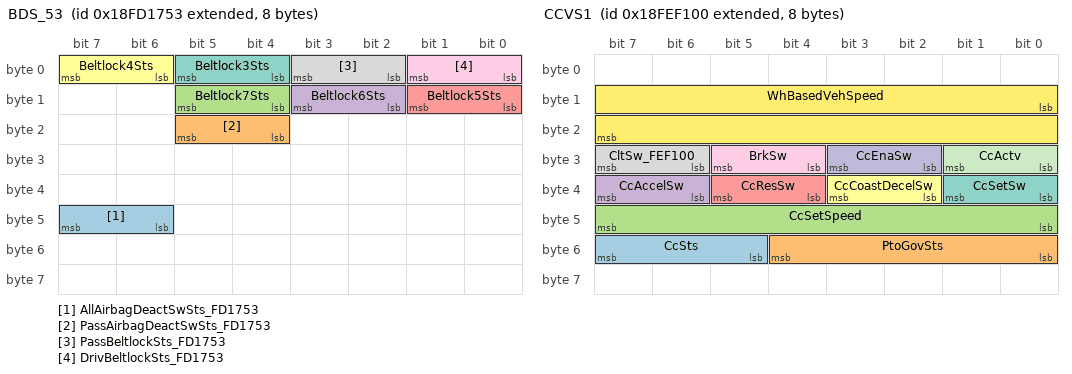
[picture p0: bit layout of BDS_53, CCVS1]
BO_ 2566723411 BDS_53: 8 Airbag
 SG_ AllAirbagDeactSwSts_FD1753 : 46|2@1+ (1,0) [0|3] ""  PCM
 SG_ PassAirbagDeactSwSts_FD1753 : 20|2@1+ (1,0) [0|3] ""  PCM
 SG_ Beltlock7Sts : 12|2@1+ (1,0) [0|3] ""  PCM
 SG_ Beltlock6Sts : 10|2@1+ (1,0) [0|3] ""  PCM
 SG_ Beltlock5Sts : 8|2@1+ (1,0) [0|3] ""  PCM
 SG_ Beltlock4Sts : 6|2@1+ (1,0) [0|3] ""  PCM
 SG_ Beltlock3Sts : 4|2@1+ (1,0) [0|3] ""  PCM
 SG_ PassBeltlockSts_FD1753 : 2|2@1+ (1,0) [0|3] ""  PCM
 SG_ DrivBeltlockSts_FD1753 : 0|2@1+ (1,0) [0|3] ""  PCM

BO_ 2365579520 BsdSensor_00: 8 ECM
 SG_ GasolInj4Diag : 62|2@1+ (1,0) [0|3] ""  PCM
 SG_ GasolInj3Diag : 60|2@1+ (1,0) [0|3] ""  PCM
 SG_ GasolInj2Diag : 58|2@1+ (1,0) [0|3] ""  PCM
 SG_ GasolInj1Diag : 56|2@1+ (1,0) [0|3] ""  PCM
 SG_ MuxSigOnCntVal : 48|8@1+ (1,0) [0|255] ""  PCM
 SG_ AckGasolInjEna : 47|1@1+ (1,0) [0|1] ""  PCM
 SG_ AckGasInjEna : 46|1@1+ (1,0) [0|1] ""  PCM
 SG_ CngInjBottomFault : 44|2@1+ (1,0) [0|3] ""  PCM
 SG_ RollCnt : 40|4@1+ (1,0) [0|15] ""  PCM
 SG_ CngInj1Diag : 38|2@1+ (1,0) [0|3] ""  PCM
 SG_ CngInj2Diag : 36|2@1+ (1,0) [0|3] ""  PCM
 SG_ CngInj3Diag : 34|2@1+ (1,0) [0|3] ""  PCM
 SG_ CngInj4Diag : 32|2@1+ (1,0) [0|3] ""  PCM
 SG_ CngTankPrsSens : 24|8@1+ (1,0) [0|250] "bar"  PCM
 SG_ TempRailPrsSens : 16|8@1+ (1,-40) [-40|60] "�C"  PCM
 SG_ FuelRailPrsSens : 8|8@1+ (0.055,0) [0|14] "bar"  PCM
 SG_ FuelRailPrsSensValData : 7|1@1+ (1,0) [0|1] ""  PCM
 SG_ TempRailPrsSensValData : 6|1@1+ (1,0) [0|1] ""  PCM
 SG_ CngTankPrsSensValData : 5|1@1+ (1,0) [0|1] ""  PCM
 SG_ CngInjBottomFaultType : 3|2@1+ (1,0) [0|3] ""  PCM
 SG_ FuelSelSts : 2|1@1+ (1,0) [0|1] ""  PCM
 SG_ DiagInj2And3ValData : 1|1@1+ (1,0) [0|1] ""  PCM
 SG_ DiagInj1And4ValData : 0|1@1+ (1,0) [0|1] ""  PCM

BO_ 2566843648 CCSS_00: 8 ECM
 SG_ MaxVsl : 0|8@1+ (1,0) [0|250] "km/h"  PCM

BO_ 2566843676 CCSS_1C: 8 PCM
 SG_ MaxVsl_FEED1C : 0|8@1+ (1,0) [0|250] "km/h" Vector__XXX

BO_ 2566844672 CCVS1: 8 ECM
 SG_ CcSts : 53|3@1+ (1,0) [0|7] ""  PCM
 SG_ PtoGovSts : 48|5@1+ (1,0) [0|31] ""  PCM
 SG_ CcSetSpeed : 40|8@1+ (1,0) [0|250] "km/h"  PCM
 SG_ CcAccelSw : 38|2@1+ (1,0) [0|3] ""  PCM
 SG_ CcResSw : 36|2@1+ (1,0) [0|3] ""  PCM
 SG_ CcCoastDecelSw : 34|2@1+ (1,0) [0|3] ""  PCM
 SG_ CcSetSw : 32|2@1+ (1,0) [0|3] ""  PCM
 SG_ CltSw_FEF100 : 30|2@1+ (1,0) [0|3] ""  PCM
 SG_ BrkSw : 28|2@1+ (1,0) [0|3] ""  PCM
 SG_ CcEnaSw : 26|2@1+ (1,0) [0|3] ""  PCM
 SG_ CcActv : 24|2@1+ (1,0) [0|3] ""  PCM
 SG_ WhBasedVehSpeed : 8|16@1+ (0.00390625,0) [0|250.996] "km/h"  PCM

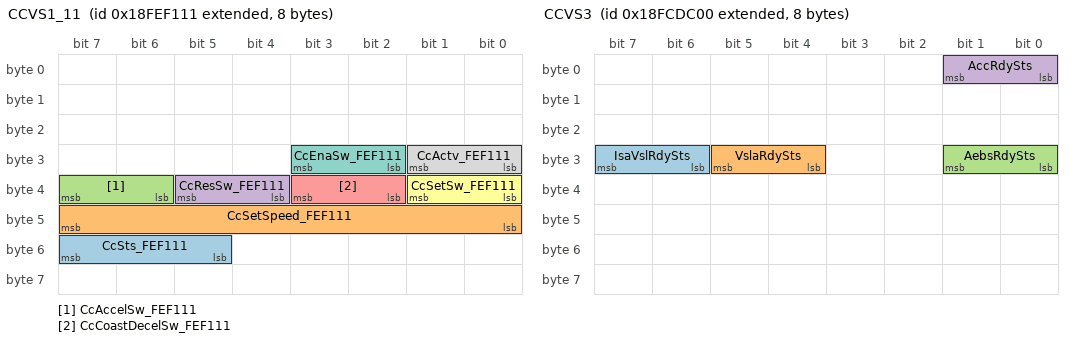
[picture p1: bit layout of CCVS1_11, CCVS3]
BO_ 2566844689 CCVS1_11: 8 NODE_11
 SG_ CcSts_FEF111 : 53|3@1+ (1,0) [0|7] ""  PCM
 SG_ CcSetSpeed_FEF111 : 40|8@1+ (1,0) [0|250] "km/h"  PCM
 SG_ CcAccelSw_FEF111 : 38|2@1+ (1,0) [0|3] ""  PCM
 SG_ CcResSw_FEF111 : 36|2@1+ (1,0) [0|3] ""  PCM
 SG_ CcCoastDecelSw_FEF111 : 34|2@1+ (1,0) [0|3] ""  PCM
 SG_ CcSetSw_FEF111 : 32|2@1+ (1,0) [0|3] ""  PCM
 SG_ CcEnaSw_FEF111 : 26|2@1+ (1,0) [0|3] ""  PCM
 SG_ CcActv_FEF111 : 24|2@1+ (1,0) [0|3] ""  PCM

BO_ 2566708224 CCVS3: 8 ECM
 SG_ IsaVslRdySts : 30|2@1+ (1,0) [0|3] ""  PCM
 SG_ VslaRdySts : 28|2@1+ (1,0) [0|3] ""  PCM
 SG_ AebsRdySts : 24|2@1+ (1,0) [0|3] ""  PCM
 SG_ AccRdySts : 0|2@1+ (1,0) [0|3] ""  PCM

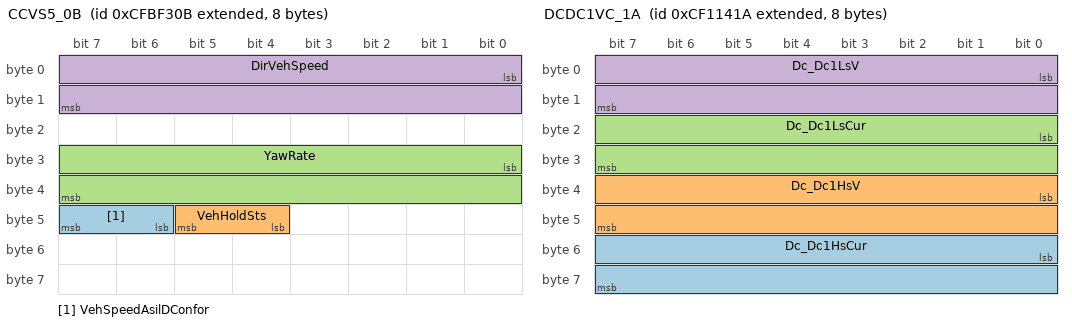
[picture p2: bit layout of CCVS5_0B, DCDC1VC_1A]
BO_ 2365321995 CCVS5_0B: 8 BSM
 SG_ VehSpeedAsilDConfor : 46|2@1+ (1,0) [0|3] ""  PCM
 SG_ VehHoldSts : 44|2@1+ (1,0) [0|3] ""  PCM
 SG_ YawRate : 24|16@1+ (0.0001220703125,-3.92) [-3.92|3.92] "rad/s"  PCM
 SG_ DirVehSpeed : 0|16@1+ (0.0078125,-250) [-250|251.992] "km/h"  PCM

BO_ 2566843136 CI_00: 609 ECM
 SG_ UnitNumPwrUnit : 24|8@1+ (1,0) [0|255] "ASCII"  PCM
 SG_ Sn : 16|8@1+ (1,0) [0|255] "ASCII"  PCM
 SG_ Model : 8|8@1+ (1,0) [0|255] "ASCII"  PCM
 SG_ Make : 0|8@1+ (1,0) [0|255] "ASCII"  PCM

BO_ 2566843141 CI_05: 609 NODE_5
 SG_ UnitNumPwrUnit_FEEB05 : 24|8@1+ (1,0) [0|255] "ASCII"  PCM
 SG_ Sn_FEEB05 : 16|8@1+ (1,0) [0|255] "ASCII"  PCM
 SG_ Model_FEEB05 : 8|8@1+ (1,0) [0|255] "ASCII"  PCM
 SG_ Make_FEEB05 : 0|8@1+ (1,0) [0|255] "ASCII"  PCM

BO_ 2566843143 CI_07: 609 NODE_7
 SG_ Sn_FEEB07 : 16|8@1+ (1,0) [0|255] "ASCII"  PCM
 SG_ Model_FEEB07 : 8|8@1+ (1,0) [0|255] "ASCII"  PCM
 SG_ Make_FEEB07 : 0|8@1+ (1,0) [0|255] "ASCII"  PCM

BO_ 2566843159 CI_17: 609 ICC
 SG_ UnitNumPwrUnit_FEEB17 : 24|8@1+ (1,0) [0|255] "ASCII"  PCM
 SG_ Sn_FEEB17 : 16|8@1+ (1,0) [0|255] "ASCII"  PCM
 SG_ Model_FEEB17 : 8|8@1+ (1,0) [0|255] "ASCII"  PCM
 SG_ Make_FEEB17 : 0|8@1+ (1,0) [0|255] "ASCII"  PCM

BO_ 2566843162 CI_1A: 609 ECS
 SG_ Sn_FEEB1A : 16|8@1+ (1,0) [0|255] "ASCII"  PCM
 SG_ Model_FEEB1A : 8|8@1+ (1,0) [0|255] "ASCII"  PCM
 SG_ Make_FEEB1A : 0|8@1+ (1,0) [0|255] "ASCII"  PCM

BO_ 2566843165 CI_1D: 609 SGW
 SG_ Sn_FEEB1D : 16|8@1+ (1,0) [0|255] "ASCII"  PCM
 SG_ Model_FEEB1D : 8|8@1+ (1,0) [0|255] "ASCII"  PCM
 SG_ Make_FEEB1D : 0|8@1+ (1,0) [0|255] "ASCII"  PCM

BO_ 2566843172 CI_24: 609 NODE_24
 SG_ Sn_FEEB24 : 16|8@1+ (1,0) [0|255] "ASCII"  PCM
 SG_ Model_FEEB24 : 8|8@1+ (1,0) [0|255] "ASCII"  PCM
 SG_ Make_FEEB24 : 0|8@1+ (1,0) [0|255] "ASCII"  PCM

BO_ 2566843175 CI_27: 609 VCM
 SG_ Sn_FEEB27 : 16|8@1+ (1,0) [0|255] "ASCII"  PCM
 SG_ Model_FEEB27 : 8|8@1+ (1,0) [0|255] "ASCII"  PCM
 SG_ Make_FEEB27 : 0|8@1+ (1,0) [0|255] "ASCII"  PCM

BO_ 2566843183 CI_2F: 609 ECAS
 SG_ UnitNumPwrUnit_FEEB2F : 24|8@1+ (1,0) [0|255] "ASCII"  PCM
 SG_ Sn_FEEB2F : 16|8@1+ (1,0) [0|255] "ASCII"  PCM
 SG_ Model_FEEB2F : 8|8@1+ (1,0) [0|255] "ASCII"  PCM
 SG_ Make_FEEB2F : 0|8@1+ (1,0) [0|255] "ASCII"  PCM

BO_ 2566843184 CI_30: 609 CDC
 SG_ Sn_FEEB30 : 16|8@1+ (1,0) [0|255] "ASCII"  PCM
 SG_ Model_FEEB30 : 8|8@1+ (1,0) [0|255] "ASCII"  PCM
 SG_ Make_FEEB30 : 0|8@1+ (1,0) [0|255] "ASCII"  PCM

BO_ 2566843201 CI_41: 609 NIS_RDR
 SG_ UnitNumPwrUnit_FEEB41 : 24|8@1+ (1,0) [0|255] "ASCII"  PCM
 SG_ Sn_FEEB41 : 16|8@1+ (1,0) [0|255] "ASCII"  PCM
 SG_ Model_FEEB41 : 8|8@1+ (1,0) [0|255] "ASCII"  PCM
 SG_ Make_FEEB41 : 0|8@1+ (1,0) [0|255] "ASCII"  PCM

BO_ 2566843209 CI_49: 609 NODE_49
 SG_ Sn_FEEB49 : 16|8@1+ (1,0) [0|255] "ASCII"  PCM
 SG_ Model_FEEB49 : 8|8@1+ (1,0) [0|255] "ASCII"  PCM
 SG_ Make_FEEB49 : 0|8@1+ (1,0) [0|255] "ASCII"  PCM

BO_ 2566843210 CI_4A: 609 PCM
 SG_ UnitNumPwrUnit_FEEB4A : 24|8@1+ (1,0) [0|255] "ASCII" Vector__XXX
 SG_ Sn_FEEB4A : 16|8@1+ (1,0) [0|255] "ASCII" Vector__XXX
 SG_ Model_FEEB4A : 8|8@1+ (1,0) [0|255] "ASCII" Vector__XXX
 SG_ Make_FEEB4A : 0|8@1+ (1,0) [0|255] "ASCII" Vector__XXX

BO_ 2566843213 CI_4D: 609 SCU
 SG_ UnitNumPwrUnit_FEEB4D : 24|8@1+ (1,0) [0|255] "ASCII"  PCM
 SG_ Sn_FEEB4D : 16|8@1+ (1,0) [0|255] "ASCII"  PCM
 SG_ Model_FEEB4D : 8|8@1+ (1,0) [0|255] "ASCII"  PCM
 SG_ Make_FEEB4D : 0|8@1+ (1,0) [0|255] "ASCII"  PCM

BO_ 2566843256 CI_78: 609 PAM
 SG_ UnitNumPwrUnit_FEEB78 : 24|8@1+ (1,0) [0|255] "ASCII"  PCM
 SG_ Sn_FEEB78 : 16|8@1+ (1,0) [0|255] "ASCII"  PCM
 SG_ Model_FEEB78 : 8|8@1+ (1,0) [0|255] "ASCII"  PCM
 SG_ Make_FEEB78 : 0|8@1+ (1,0) [0|255] "ASCII"  PCM

BO_ 2566843260 CI_7C: 609 NODE_7C
 SG_ Sn_FEEB7C : 16|8@1+ (1,0) [0|255] "ASCII"  PCM
 SG_ Model_FEEB7C : 8|8@1+ (1,0) [0|255] "ASCII"  PCM
 SG_ Make_FEEB7C : 0|8@1+ (1,0) [0|255] "ASCII"  PCM

BO_ 2566843375 CI_EF: 609 NODE_EF
 SG_ Sn_FEEBEF : 16|8@1+ (1,0) [0|255] "ASCII"  PCM
 SG_ Model_FEEBEF : 8|8@1+ (1,0) [0|255] "ASCII"  PCM
 SG_ Make_FEEBEF : 0|8@1+ (1,0) [0|255] "ASCII"  PCM

BO_ 2566843378 CI_F2: 609 NODE_F2
 SG_ Sn_FEEBF2 : 16|8@1+ (1,0) [0|255] "ASCII"  PCM
 SG_ Model_FEEBF2 : 8|8@1+ (1,0) [0|255] "ASCII"  PCM
 SG_ Make_FEEBF2 : 0|8@1+ (1,0) [0|255] "ASCII"  PCM

BO_ 2566843379 CI_F3: 609 NODE_F3
 SG_ Sn_FEEBF3 : 16|8@1+ (1,0) [0|255] "ASCII"  PCM
 SG_ Model_FEEBF3 : 8|8@1+ (1,0) [0|255] "ASCII"  PCM
 SG_ Make_FEEBF3 : 0|8@1+ (1,0) [0|255] "ASCII"  PCM

BO_ 2563833623 CL_17: 8 ICC
 SG_ IllBrtPc : 0|8@1+ (0.4,0) [0|100] "%"  PCM

BO_ 2563829281 CL_21_EE: 8 BCM
 SG_ IllBrtPc_D0EE21 : 0|8@1+ (0.4,0) [0|100] "%"  PCM,DTCO

BO_ 2563833665 CL_41: 8 NIS_RDR
 SG_ IllBrtPc_D0FF41 : 0|8@1+ (0.4,0) [0|100] "%"  PCM

BO_ 2564882176 CM1_00: 8 ECM
 SG_ BatMainSwHoldReq : 26|2@1+ (1,0) [0|3] ""  PCM

BO_ 2564882179 CM1_03: 8 AI_G5_TCM
 SG_ EngAutoStartEnaSw : 46|2@1+ (1,0) [0|3] ""  PCM

BO_ 2564882199 CM1_17: 8 ICC
 SG_ AtRegenForceSw : 42|2@1+ (1,0) [0|3] ""  PCM

BO_ 2564882201 CM1_19: 8 ACM
 SG_ CabInternTempCmd : 8|16@1+ (0.03125,-273) [-273|1734.96875] "�C"  PCM

BO_ 2564882209 CM1_21: 8 BCM
 SG_ SeatBeltSw : 30|2@1+ (1,0) [0|3] ""  PCM
 SG_ CabInternTempCmd_E0FF21 : 8|16@1+ (0.03125,-273) [-273|1734.96875] "�C"  PCM

BO_ 2564882215 CM1_27: 8 VCM
 SG_ BatMainSwHoldReq_E0FF27 : 26|2@1+ (1,0) [0|3] ""  PCM

BO_ 2564882227 CM1_33: 8 OptiTire
 SG_ BatMainSwHoldReq_E0FF33 : 26|2@1+ (1,0) [0|3] ""  PCM

BO_ 2564882241 CM1_41: 8 NIS_RDR
 SG_ BatMainSwHoldReq_E0FF41 : 26|2@1+ (1,0) [0|3] ""  PCM

BO_ 2564882250 CM1_4A: 8 PCM
 SG_ BatMainSwHoldReq_E0FF4A : 26|2@1+ (1,0) [0|3] "" Vector__XXX

BO_ 2566811659 CVW_0B: 8 BSM
 SG_ Gcvw : 16|16@1+ (10,0) [0|642550] "kg"  PCM

BO_ 2566811687 CVW_27: 8 VCM
 SG_ Gcvw_FE7027 : 16|16@1+ (10,0) [0|642550] "kg"  PCM

BO_ 2566802967 DC1_17: 8 ICC
 SG_ Sts2OfDoors : 6|2@1+ (1,0) [0|3] ""  PCM

BO_ 2364609063 DCDC1C_27: 8 VCM
 SG_ Dc_Dc1LsVBuckSetp : 8|16@1+ (0.01,0) [0|642.55] "V"  PCM
 SG_ Dc_Dc1OpCmd : 0|4@1+ (1,0) [0|15] ""  PCM

BO_ 2365315367 DCDC1LL_27: 8 VCM
 SG_ Dc_Dc1LsCurMaxLimReq : 32|16@1+ (0.05,0) [0|3212.75] "A"  PCM

BO_ 2364609306 DCDC1OS_1A: 8 ECS
 SG_ Dc_Dc1PwrLimDueToPwrElnTemp : 24|2@1+ (1,0) [0|3] ""  PCM
 SG_ Dc_Dc1OpSts : 0|4@1+ (1,0) [0|15] ""  PCM

BO_ 2364610330 DCDC1S2_1A: 8 ECS
 SG_ Dc_Dc1HsPwr : 16|16@1+ (0.05,-1600) [-1600|1612.75] "kW"  PCM
 SG_ Dc_Dc1LsPwr : 0|16@1+ (0.05,-1600) [-1600|1612.75] "kW"  PCM

BO_ 2365315079 DCDC1T_07: 8 NODE_7
 SG_ Dc_Dc1PwrElnTemp : 16|8@1+ (1,-40) [-40|210] "�C"  PCM

BO_ 2365315098 DCDC1T_1A: 8 ECS
 SG_ Dc_Dc1PwrElnTemp_BD81A : 16|8@1+ (1,-40) [-40|210] "�C"  PCM

BO_ 2365315108 DCDC1T_24: 8 NODE_24
 SG_ Dc_Dc1PwrElnTemp_BD824 : 16|8@1+ (1,-40) [-40|210] "�C"  PCM

BO_ 2364609562 DCDC1VC_1A: 8 ECS
 SG_ Dc_Dc1HsCur : 48|16@1+ (0.1,-3212.7) [-3212.7|3212.8] "A"  PCM
 SG_ Dc_Dc1HsV : 32|16@1+ (0.05,0) [0|3212.75] "V"  PCM
 SG_ Dc_Dc1LsCur : 16|16@1+ (0.1,-3212.7) [-3212.7|3212.8] "A"  PCM
 SG_ Dc_Dc1LsV : 0|16@1+ (0.01,0) [0|642.55] "V"  PCM

BO_ 2364610599 DCDC2C_27: 8 VCM
 SG_ Dc_Dc2LsVBuckSetp : 8|16@1+ (0.01,0) [0|642.55] "V"  PCM
 SG_ Dc_Dc2OpCmd : 0|4@1+ (1,0) [0|15] ""  PCM

BO_ 2365311015 DCDC2LL_27: 8 VCM
 SG_ Dc_Dc2LsCurMaxLimReq : 32|16@1+ (0.05,0) [0|3212.75] "A"  PCM

BO_ 2364611879 DCDC3C_27: 8 VCM
 SG_ Dc_Dc3LsVBuckSetp : 8|16@1+ (0.01,0) [0|642.55] "V"  PCM
 SG_ Dc_Dc3OpCmd : 0|4@1+ (1,0) [0|15] ""  PCM

BO_ 2365309479 DCDC3LL_27: 8 VCM
 SG_ Dc_Dc3LsCurMaxLimReq : 32|16@1+ (0.05,0) [0|3212.75] "A"  PCM

BO_ 2566847488 DD1_00: 8 ECM
 SG_ FuelLev1 : 8|8@1+ (0.4,0) [0|100] "%"  PCM

BO_ 2566847521 DD1_21: 8 BCM
 SG_ FuelLev2 : 48|8@1+ (0.4,0) [0|100] "%"  PCM
 SG_ FuelLev1_FEFC21 : 8|8@1+ (0.4,0) [0|100] "%"  PCM

BO_ 2566810606 DI_EE: 40 DTCO
 SG_ Driv2Id : 8|8@1+ (1,0) [0|255] "ASCII"  PCM
 SG_ Driv1Id : 0|8@1+ (1,0) [0|255] "ASCII"  PCM

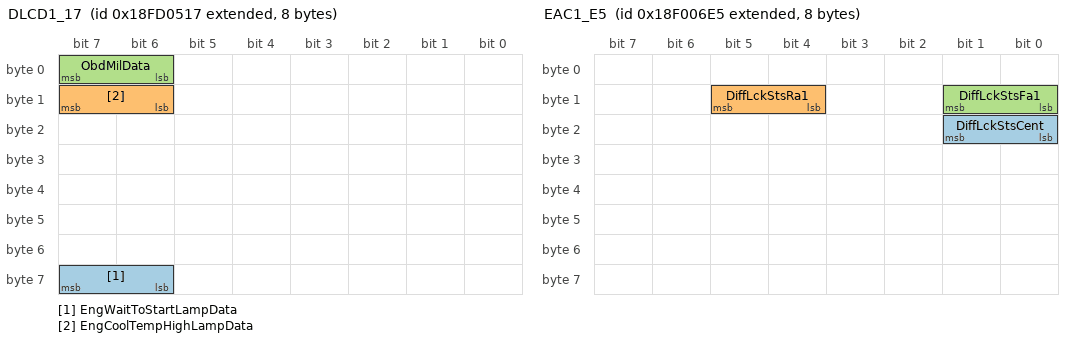
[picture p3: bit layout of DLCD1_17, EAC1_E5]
BO_ 2566718743 DLCD1_17: 8 ICC
 SG_ EngWaitToStartLampData : 62|2@1+ (1,0) [0|3] ""  PCM
 SG_ EngCoolTempHighLampData : 14|2@1+ (1,0) [0|3] ""  PCM
 SG_ ObdMilData : 6|2@1+ (1,0) [0|3] ""  PCM

BO_ 2566834688 DM01_00: 82 ECM
 SG_ SpnCm20 : 655|1@1+ (1,0) [0|1] ""  PCM

BO_ 2566834691 DM01_03: 42 AI_G5_TCM
 SG_ SpnCm10 : 335|1@1+ (1,0) [0|1] ""  PCM

BO_ 2566834693 DM01_05: 42 NODE_5
 SG_ SpnCm10_FECA05 : 335|1@1+ (1,0) [0|1] ""  PCM

BO_ 2566834695 DM01_07: 42 NODE_7
 SG_ SpnCm10_FECA07 : 335|1@1+ (1,0) [0|1] ""  PCM

BO_ 2566834699 DM01_0B: 42 BSM
 SG_ SpnCm10_FECA0B : 335|1@1+ (1,0) [0|1] ""  PCM

BO_ 2566834704 DM01_10: 42 EST54_IRCS
 SG_ SpnCm10_FECA10 : 335|1@1+ (1,0) [0|1] ""  PCM

BO_ 2566834707 DM01_13: 42 NODE_13
 SG_ SpnCm10_FECA13 : 335|1@1+ (1,0) [0|1] ""  PCM

BO_ 2566834711 DM01_17: 82 ICC
 SG_ SpnCm20_FECA17 : 655|1@1+ (1,0) [0|1] ""  PCM

BO_ 2566834713 DM01_19: 42 ACM
 SG_ SpnCm10_FECA19 : 335|1@1+ (1,0) [0|1] ""  PCM

BO_ 2566834714 DM01_1A: 42 ECS
 SG_ SpnCm10_FECA1A : 335|1@1+ (1,0) [0|1] ""  PCM

BO_ 2566834717 DM01_1D: 42 SGW
 SG_ SpnCm10_FECA1D : 335|1@1+ (1,0) [0|1] ""  PCM

BO_ 2566834721 DM01_21: 42 BCM
 SG_ SpnCm10_FECA21 : 335|1@1+ (1,0) [0|1] ""  PCM

BO_ 2566834724 DM01_24: 42 NODE_24
 SG_ SpnCm10_FECA24 : 335|1@1+ (1,0) [0|1] ""  PCM

BO_ 2566834727 DM01_27: 42 VCM
 SG_ SpnCm10_FECA27 : 335|1@1+ (1,0) [0|1] ""  PCM

BO_ 2566834730 DM01_2A: 42 LDW
 SG_ SpnCm10_FECA2A : 335|1@1+ (1,0) [0|1] ""  PCM

BO_ 2566834735 DM01_2F: 42 ECAS
 SG_ SpnCm10_FECA2F : 335|1@1+ (1,0) [0|1] ""  PCM

BO_ 2566834736 DM01_30: 42 CDC
 SG_ SpnCm10_FECA30 : 335|1@1+ (1,0) [0|1] ""  PCM

BO_ 2566834739 DM01_33: 42 OptiTire
 SG_ SpnCm10_FECA33 : 335|1@1+ (1,0) [0|1] ""  PCM

BO_ 2566834753 DM01_41: 42 NIS_RDR
 SG_ SpnCm10_FECA41 : 335|1@1+ (1,0) [0|1] ""  PCM

BO_ 2566834761 DM01_49: 42 NODE_49
 SG_ SpnCm10_FECA49 : 335|1@1+ (1,0) [0|1] ""  PCM

BO_ 2566834762 DM01_4A: 42 PCM
 SG_ SpnCm10_FECA4A : 335|1@1+ (1,0) [0|1] "" Vector__XXX

BO_ 2566834765 DM01_4D: 42 SCU
 SG_ SpnCm10_FECA4D : 335|1@1+ (1,0) [0|1] ""  PCM

BO_ 2566834771 DM01_53: 42 Airbag
 SG_ SpnCm10_FECA53 : 335|1@1+ (1,0) [0|1] ""  PCM

BO_ 2566834802 DM01_72: 42 EM_PTO
 SG_ SpnCm10_FECA72 : 335|1@1+ (1,0) [0|1] ""  PCM

BO_ 2566834808 DM01_78: 42 PAM
 SG_ SpnCm10_FECA78 : 335|1@1+ (1,0) [0|1] ""  PCM

BO_ 2566834812 DM01_7C: 42 NODE_7C
 SG_ SpnCm10_FECA7C : 335|1@1+ (1,0) [0|1] ""  PCM

BO_ 2566834817 DM01_81: 42 NODE_81
 SG_ SpnCm10_FECA81 : 335|1@1+ (1,0) [0|1] ""  PCM

BO_ 2566834844 DM01_9C: 42 RSRRM
 SG_ SpnCm10_FECA9C : 335|1@1+ (1,0) [0|1] ""  PCM

BO_ 2566834846 DM01_9E: 42 ADCU
 SG_ SpnCm10_FECA9E : 335|1@1+ (1,0) [0|1] ""  PCM

BO_ 2566834847 DM01_9F: 42 NODE_9F
 SG_ SpnCm10_FECA9F : 335|1@1+ (1,0) [0|1] ""  PCM

BO_ 2566834848 DM01_A0: 42 AEBS
 SG_ SpnCm10_FECAA0 : 335|1@1+ (1,0) [0|1] ""  PCM

BO_ 2566834889 DM01_C9: 42 ALM
 SG_ SpnCm10_FECAC9 : 335|1@1+ (1,0) [0|1] ""  PCM

BO_ 2566834917 DM01_E5: 42 BC2
 SG_ SpnCm10_FECAE5 : 335|1@1+ (1,0) [0|1] ""  PCM

BO_ 2566834926 DM01_EE: 42 DTCO
 SG_ SpnCm10_FECAEE : 335|1@1+ (1,0) [0|1] ""  PCM

BO_ 2566834927 DM01_EF: 42 NODE_EF
 SG_ SpnCm10_FECAEF : 335|1@1+ (1,0) [0|1] ""  PCM

BO_ 2566834930 DM01_F2: 42 NODE_F2
 SG_ SpnCm10_FECAF2 : 335|1@1+ (1,0) [0|1] ""  PCM

BO_ 2566834931 DM01_F3: 42 NODE_F3
 SG_ SpnCm10_FECAF3 : 335|1@1+ (1,0) [0|1] ""  PCM

BO_ 2566834947 DM02_03: 42 AI_G5_TCM
 SG_ SpnCm10_FECB03 : 335|1@1+ (1,0) [0|1] ""  PCM

BO_ 2566834949 DM02_05: 42 NODE_5
 SG_ SpnCm10_FECB05 : 335|1@1+ (1,0) [0|1] ""  PCM

BO_ 2566834951 DM02_07: 42 NODE_7
 SG_ SpnCm10_FECB07 : 335|1@1+ (1,0) [0|1] ""  PCM

BO_ 2566834970 DM02_1A: 42 ECS
 SG_ SpnCm10_FECB1A : 335|1@1+ (1,0) [0|1] ""  PCM

BO_ 2566834973 DM02_1D: 42 SGW
 SG_ SpnCm10_FECB1D : 335|1@1+ (1,0) [0|1] ""  PCM

BO_ 2566834980 DM02_24: 42 NODE_24
 SG_ SpnCm10_FECB24 : 335|1@1+ (1,0) [0|1] ""  PCM

BO_ 2566834991 DM02_2F: 42 ECAS
 SG_ SpnCm10_FECB2F : 335|1@1+ (1,0) [0|1] ""  PCM

BO_ 2566834992 DM02_30: 42 CDC
 SG_ SpnCm10_FECB30 : 335|1@1+ (1,0) [0|1] ""  PCM

BO_ 2566834995 DM02_33: 42 OptiTire
 SG_ SpnCm10_FECB33 : 335|1@1+ (1,0) [0|1] ""  PCM

BO_ 2566835017 DM02_49: 42 NODE_49
 SG_ SpnCm10_FECB49 : 335|1@1+ (1,0) [0|1] ""  PCM

BO_ 2566835018 DM02_4A: 42 PCM
 SG_ SpnCm10_FECB4A : 335|1@1+ (1,0) [0|1] "" Vector__XXX

BO_ 2566835021 DM02_4D: 42 SCU
 SG_ SpnCm10_FECB4D : 335|1@1+ (1,0) [0|1] ""  PCM

BO_ 2566835058 DM02_72: 42 EM_PTO
 SG_ SpnCm10_FECB72 : 335|1@1+ (1,0) [0|1] ""  PCM

BO_ 2566835068 DM02_7C: 42 NODE_7C
 SG_ SpnCm10_FECB7C : 335|1@1+ (1,0) [0|1] ""  PCM

BO_ 2566835183 DM02_EF: 42 NODE_EF
 SG_ SpnCm10_FECBEF : 335|1@1+ (1,0) [0|1] ""  PCM

BO_ 2566835186 DM02_F2: 42 NODE_F2
 SG_ SpnCm10_FECBF2 : 335|1@1+ (1,0) [0|1] ""  PCM

BO_ 2566835187 DM02_F3: 42 NODE_F3
 SG_ SpnCm10_FECBF3 : 335|1@1+ (1,0) [0|1] ""  PCM

BO_ 2566835459 DM04_03: 351 AI_G5_TCM
 SG_ WhBasedVehSpeed_1 : 88|16@1+ (0.00390625,0) [0|250.996] "km/h"  PCM

BO_ 2566835461 DM04_05: 250 NODE_5
 SG_ HrTotVehDist_10 : 1968|32@1+ (5,0) [0|21055406075] "m"  PCM

BO_ 2566835463 DM04_07: 250 NODE_7
 SG_ HrTotVehDist_10_FECD07 : 1968|32@1+ (5,0) [0|21055406075] "m"  PCM

BO_ 2566835482 DM04_1A: 250 ECS
 SG_ HrTotVehDist_10_FECD1A : 1968|32@1+ (5,0) [0|21055406075] "m"  PCM

BO_ 2566835485 DM04_1D: 250 SGW
 SG_ HrTotVehDist_10_FECD1D : 1968|32@1+ (5,0) [0|21055406075] "m"  PCM

BO_ 2566835492 DM04_24: 250 NODE_24
 SG_ HrTotVehDist_10_FECD24 : 1968|32@1+ (5,0) [0|21055406075] "m"  PCM

BO_ 2566835503 DM04_2F: 250 ECAS
 SG_ HrTotVehDist_10_FECD2F : 1968|32@1+ (5,0) [0|21055406075] "m"  PCM

BO_ 2566835504 DM04_30: 250 CDC
 SG_ HrTotVehDist_10_FECD30 : 1968|32@1+ (5,0) [0|21055406075] "m"  PCM

BO_ 2566835529 DM04_49: 250 NODE_49
 SG_ HrTotVehDist_10_FECD49 : 1968|32@1+ (5,0) [0|21055406075] "m"  PCM

BO_ 2566835530 DM04_4A: 250 PCM
 SG_ HrTotVehDist_10_FECD4A : 1968|32@1+ (5,0) [0|21055406075] "m" Vector__XXX

BO_ 2566835533 DM04_4D: 250 SCU
 SG_ HrTotVehDist_10_FECD4D : 1968|32@1+ (5,0) [0|21055406075] "m"  PCM

BO_ 2566835539 DM04_53: 250 Airbag
 SG_ HrTotVehDist_10_FECD53 : 1968|32@1+ (5,0) [0|21055406075] "m"  PCM

BO_ 2566835576 DM04_78: 250 PAM
 SG_ HrTotVehDist_10_FECD78 : 1968|32@1+ (5,0) [0|21055406075] "m"  PCM

BO_ 2566835580 DM04_7C: 250 NODE_7C
 SG_ HrTotVehDist_10_FECD7C : 1968|32@1+ (5,0) [0|21055406075] "m"  PCM

BO_ 2566835657 DM04_C9: 250 ALM
 SG_ HrTotVehDist_10_FECDC9 : 1968|32@1+ (5,0) [0|21055406075] "m"  PCM

BO_ 2566835695 DM04_EF: 250 NODE_EF
 SG_ HrTotVehDist_10_FECDEF : 1968|32@1+ (5,0) [0|21055406075] "m"  PCM

BO_ 2566835698 DM04_F2: 250 NODE_F2
 SG_ HrTotVehDist_10_FECDF2 : 1968|32@1+ (5,0) [0|21055406075] "m"  PCM

BO_ 2566835699 DM04_F3: 250 NODE_F3
 SG_ HrTotVehDist_10_FECDF3 : 1968|32@1+ (5,0) [0|21055406075] "m"  PCM

BO_ 2565867237 EAC1_E5: 8 BC2
 SG_ DiffLckStsCent : 16|2@1+ (1,0) [0|3] ""  PCM
 SG_ DiffLckStsRa1 : 12|2@1+ (1,0) [0|3] ""  PCM
 SG_ DiffLckStsFa1 : 8|2@1+ (1,0) [0|3] ""  PCM

CM_ SG_ 2566723411 AllAirbagDeactSwSts_FD1753 "- Proprietary Addition";
CM_ BO_ 2566843648 "- SAE Trans.Rate=OnRequest";
CM_ SG_ 2566843648 MaxVsl "- On MY24 it sends the minimum value of Prymary SL, Secondary SL and ECO mode";
CM_ BO_ 2566843676 "- SAE Trans.Rate=OnRequest";
CM_ SG_ 2566843676 MaxVsl_FEED1C "- Road Speed Limit from GPS maps
-  Type of included limits shall be defined";
CM_ SG_ 2566844672 WhBasedVehSpeed "- SAE J1939/73 Freeze Frame parameter";
CM_ SG_ 2566708224 IsaVslRdySts "- Proprietary Addition";
CM_ SG_ 2566708224 VslaRdySts "- Proprietary Addition";
CM_ SG_ 2365321995 VehSpeedAsilDConfor "- Proprietary addition";
CM_ SG_ 2365321995 VehHoldSts "- Proprietary addition";
CM_ SG_ 2365321995 YawRate "- Proprietary addition";
CM_ BO_ 2566843136 "- Delimiter (�*�) required after each parameter, even if not used
-  Multipacket message handled by SAE Transport Protocol (J1939/21, par 5.10, Multipacket Broadcast with TP.CM/BAM, TP.DT)
-  Transport Protocol with Control Flow  (RTS, CTS, EndOfMsgAck, Conn_Abort) shall be also supported by the receiver if the multipacket message has been solicited by a Destination Specific Request
-  Variable Message Length, maximum value used for dbc generation";
CM_ SG_ 2566843136 UnitNumPwrUnit "- 15+1 characters maximum
-  Optional, delimiter only if not supported
-  Variable signal length, 8 bits used for dbc generation only";
CM_ SG_ 2566843136 Sn "- 10+1 characters maximum; Manufacturer assigned (IVECO Std. 18-2253)
-  Optional (IVECO Std. 18-2253), delimiter only if not supported
-  Variable signal length, 8 bits used for dbc generation only";
CM_ SG_ 2566843136 Model "- 15+1 characters maximum; Manufacturer assigned Component (or ECU if no Component) Model or Part Number (IVECO Std. 18-2253)
-  Variable signal length, 8 bits used for dbc generation only";
CM_ SG_ 2566843136 Make "- Variable signal length, 8 bits used for dbc generation only";
CM_ BO_ 2566843141 "- Delimiter (�*�) required after each parameter, even if not used
-  Multipacket message handled by SAE Transport Protocol (J1939/21, par 5.10, Multipacket Broadcast with TP.CM/BAM, TP.DT)
-  Transport Protocol with Control Flow  (RTS, CTS, EndOfMsgAck, Conn_Abort) shall be also supported by the receiver if the multipacket message has been solicited by a Destination Specific Request
-  Variable Message Length, maximum value used for dbc generation";
CM_ SG_ 2566843141 UnitNumPwrUnit_FEEB05 "- 15+1 characters maximum
-  Optional, delimiter only if not supported
-  Variable signal length, 8 bits used for dbc generation only";
CM_ SG_ 2566843141 Sn_FEEB05 "- 10+1 characters maximum; Manufacturer assigned (IVECO Std. 18-2253)
-  Optional (IVECO Std. 18-2253), delimiter only if not supported
-  Variable signal length, 8 bits used for dbc generation only";
CM_ SG_ 2566843141 Model_FEEB05 "- 15+1 characters maximum; Manufacturer assigned Component/ECU Model or P/N(IVECO Std. 18-2253)
-  Variable signal length, 8 bits used for dbc generation only";
CM_ SG_ 2566843141 Make_FEEB05 "- Variable signal length, 8 bits used for dbc generation only";
CM_ BO_ 2566843143 "- Delimiter (�*�) required after each parameter, even if not used
-  Multipacket message handled by SAE Transport Protocol (J1939/21, par 5.10, Multipacket Broadcast with TP.CM/BAM, TP.DT)
-  Transport Protocol with Control Flow  (RTS, CTS, EndOfMsgAck, Conn_Abort) shall be also supported by the receiver if the multipacket message has been solicited by a Destination Specific Request
-  Variable Message Length, maximum value used for dbc generation";
CM_ SG_ 2566843143 Sn_FEEB07 "- 10+1 characters maximum; Manufacturer assigned (IVECO Std. 18-2253)
-  Optional (IVECO Std. 18-2253), delimiter only if not supported
-  Variable signal length, 8 bits used for dbc generation only";
CM_ SG_ 2566843143 Model_FEEB07 "- 15+1 characters maximum; Manufacturer assigned Component/ECU Model or P/N(IVECO Std. 18-2253)
-  Variable signal length, 8 bits used for dbc generation only";
CM_ SG_ 2566843143 Make_FEEB07 "- Variable signal length, 8 bits used for dbc generation only";
CM_ BO_ 2566843159 "- Delimiter (�*�) required after each parameter, even if not used
-  Multipacket message handled by SAE Transport Protocol (J1939/21, par 5.10, Multipacket Broadcast with TP.CM/BAM, TP.DT)
-  Variable Message Length, maximum value used for dbc generation";
CM_ SG_ 2566843159 UnitNumPwrUnit_FEEB17 "- 15+1 characters maximum
-  Optional, delimiter only if not supported
-  Variable signal length, 8 bits used for dbc generation only";
CM_ SG_ 2566843159 Sn_FEEB17 "- 10+1 characters maximum; Manufacturer assigned (IVECO Std. 18-2253)
-  Optional (IVECO Std. 18-2253), delimiter only if not supported
-  Variable signal length, 8 bits used for dbc generation only";
CM_ SG_ 2566843159 Model_FEEB17 "- 15+1 characters maximum; Manufacturer assigned Component/ECU Model or P/N(IVECO Std. 18-2253)
-  Variable signal length, 8 bits used for dbc generation only";
CM_ SG_ 2566843159 Make_FEEB17 "- Variable signal length, 8 bits used for dbc generation only";
CM_ BO_ 2566843162 "- Delimiter (�*�) required after each parameter, even if not used
-  Multipacket message handled by SAE Transport Protocol (J1939/21, par 5.10, Multipacket Broadcast with TP.CM/BAM, TP.DT)
-  Transport Protocol with Control Flow  (RTS, CTS, EndOfMsgAck, Conn_Abort) shall be also supported by the receiver if the multipacket message has been solicited by a Destination Specific Request
-  Variable Message Length, maximum value used for dbc generation";
CM_ SG_ 2566843162 Sn_FEEB1A "- 10+1 characters maximum; Manufacturer assigned (IVECO Std. 18-2253)
-  Optional (IVECO Std. 18-2253), delimiter only if not supported
-  Variable signal length, 8 bits used for dbc generation only";
CM_ SG_ 2566843162 Model_FEEB1A "- 15+1 characters maximum; Manufacturer assigned Component/ECU Model or P/N(IVECO Std. 18-2253)
-  Variable signal length, 8 bits used for dbc generation only";
CM_ SG_ 2566843162 Make_FEEB1A "- Variable signal length, 8 bits used for dbc generation only";
CM_ BO_ 2566843165 "- Delimiter (�*�) required after each parameter, even if not used
-  Multipacket message handled by SAE Transport Protocol (J1939/21, par 5.10, Multipacket Broadcast with TP.CM/BAM, TP.DT)
-  Transport Protocol with Control Flow  (RTS, CTS, EndOfMsgAck, Conn_Abort) shall be also supported by the receiver if the multipacket message has been solicited by a Destination Specific Request
-  Variable Message Length, maximum value used for dbc generation";
CM_ SG_ 2566843165 Sn_FEEB1D "- 10+1 characters maximum; Manufacturer assigned (IVECO Std. 18-2253)
-  Optional (IVECO Std. 18-2253), delimiter only if not supported
-  Variable signal length, 8 bits used for dbc generation only";
CM_ SG_ 2566843165 Model_FEEB1D "- 15+1 characters maximum; Manufacturer assigned Component/ECU Model or P/N(IVECO Std. 18-2253)
-  Variable signal length, 8 bits used for dbc generation only";
CM_ SG_ 2566843165 Make_FEEB1D "- Variable signal length, 8 bits used for dbc generation only";
CM_ BO_ 2566843172 "- Delimiter (�*�) required after each parameter, even if not used
-  Multipacket message handled by SAE Transport Protocol (J1939/21, par 5.10, Multipacket Broadcast with TP.CM/BAM, TP.DT)
-  Transport Protocol with Control Flow  (RTS, CTS, EndOfMsgAck, Conn_Abort) shall be also supported by the receiver if the multipacket message has been solicited by a Destination Specific Request
-  Variable Message Length, maximum value used for dbc generation";
CM_ SG_ 2566843172 Sn_FEEB24 "- 10+1 characters maximum; Manufacturer assigned (IVECO Std. 18-2253)
-  Optional (IVECO Std. 18-2253), delimiter only if not supported
-  Variable signal length, 8 bits used for dbc generation only";
CM_ SG_ 2566843172 Model_FEEB24 "- 15+1 characters maximum; Manufacturer assigned Component/ECU Model or P/N(IVECO Std. 18-2253)
-  Variable signal length, 8 bits used for dbc generation only";
CM_ SG_ 2566843172 Make_FEEB24 "- Variable signal length, 8 bits used for dbc generation only";
CM_ BO_ 2566843175 "- Delimiter (�*�) required after each parameter, even if not used
-  Multipacket message handled by SAE Transport Protocol (J1939/21, par 5.10, Multipacket Broadcast with TP.CM/BAM, TP.DT)
-  Transport Protocol with Control Flow  (RTS, CTS, EndOfMsgAck, Conn_Abort) shall be also supported by the receiver if the multipacket message has been solicited by a Destination Specific Request
-  Variable Message Length, maximum value used for dbc generation";
CM_ SG_ 2566843175 Sn_FEEB27 "- 10+1 characters maximum; Manufacturer assigned (IVECO Std. 18-2253)
-  Optional (IVECO Std. 18-2253), delimiter only if not supported
-  Variable signal length, 8 bits used for dbc generation only";
CM_ SG_ 2566843175 Model_FEEB27 "- 15+1 characters maximum; Manufacturer assigned Component/ECU Model or P/N(IVECO Std. 18-2253)
-  Variable signal length, 8 bits used for dbc generation only";
CM_ SG_ 2566843175 Make_FEEB27 "- Variable signal length, 8 bits used for dbc generation only";
CM_ BO_ 2566843183 "- Delimiter (�*�) required after each parameter, even if not used
-  Multipacket message handled by SAE Transport Protocol (J1939/21, par 5.10, Multipacket Broadcast with TP.CM/BAM, TP.DT)
-  Transport Protocol with Control Flow  (RTS, CTS, EndOfMsgAck, Conn_Abort) shall be also supported by the receiver if the multipacket message has been solicited by a Destination Specific Request
-  Variable Message Length, maximum value used for dbc generation";
CM_ SG_ 2566843183 UnitNumPwrUnit_FEEB2F "- 15+1 characters maximum
-  Optional, delimiter only if not supported
-  Variable signal length, 8 bits used for dbc generation only";
CM_ SG_ 2566843183 Sn_FEEB2F "- 10+1 characters maximum; Manufacturer assigned (IVECO Std. 18-2253)
-  Optional (IVECO Std. 18-2253), delimiter only if not supported
-  Variable signal length, 8 bits used for dbc generation only";
CM_ SG_ 2566843183 Model_FEEB2F "- 15+1 characters maximum; Manufacturer assigned Component/ECU Model or P/N(IVECO Std. 18-2253)
-  Variable signal length, 8 bits used for dbc generation only";
CM_ SG_ 2566843183 Make_FEEB2F "- Variable signal length, 8 bits used for dbc generation only";
CM_ BO_ 2566843184 "- Delimiter (�*�) required after each parameter, even if not used
-  Multipacket message handled by SAE Transport Protocol (J1939/21, par 5.10, Multipacket Broadcast with TP.CM/BAM, TP.DT)
-  Transport Protocol with Control Flow  (RTS, CTS, EndOfMsgAck, Conn_Abort) shall be also supported by the receiver if the multipacket message has been solicited by a Destination Specific Request
-  Variable Message Length, maximum value used for dbc generation";
CM_ SG_ 2566843184 Sn_FEEB30 "- 10+1 characters maximum; Manufacturer assigned (IVECO Std. 18-2253)
-  Optional (IVECO Std. 18-2253), delimiter only if not supported
-  Variable signal length, 8 bits used for dbc generation only";
CM_ SG_ 2566843184 Model_FEEB30 "- 15+1 characters maximum; Manufacturer assigned Component/ECU Model or P/N(IVECO Std. 18-2253)
-  Variable signal length, 8 bits used for dbc generation only";
CM_ SG_ 2566843184 Make_FEEB30 "- Variable signal length, 8 bits used for dbc generation only";
CM_ BO_ 2566843201 "- Delimiter (�*�) required after each parameter, even if not used
-  Multipacket message handled by SAE Transport Protocol (J1939/21, par 5.10, Multipacket Broadcast with TP.CM/BAM, TP.DT)
-  Transport Protocol with Control Flow  (RTS, CTS, EndOfMsgAck, Conn_Abort) shall be also supported by the receiver if the multipacket message has been solicited by a Destination Specific Request
-  Variable Message Length, maximum value used for dbc generation";
CM_ SG_ 2566843201 UnitNumPwrUnit_FEEB41 "- 15+1 characters maximum
-  Optional, delimiter only if not supported
-  Variable signal length, 8 bits used for dbc generation only";
CM_ SG_ 2566843201 Sn_FEEB41 "- 10+1 characters maximum; Manufacturer assigned (IVECO Std. 18-2253)
-  Optional (IVECO Std. 18-2253), delimiter only if not supported
-  Variable signal length, 8 bits used for dbc generation only";
CM_ SG_ 2566843201 Model_FEEB41 "- 15+1 characters maximum; Manufacturer assigned Component/ECU Model or P/N(IVECO Std. 18-2253)
-  Variable signal length, 8 bits used for dbc generation only";
CM_ SG_ 2566843201 Make_FEEB41 "- Variable signal length, 8 bits used for dbc generation only";
CM_ BO_ 2566843209 "- Delimiter (�*�) required after each parameter, even if not used
-  Multipacket message handled by SAE Transport Protocol (J1939/21, par 5.10, Multipacket Broadcast with TP.CM/BAM, TP.DT)
-  Transport Protocol with Control Flow  (RTS, CTS, EndOfMsgAck, Conn_Abort) shall be also supported by the receiver if the multipacket message has been solicited by a Destination Specific Request
-  Variable Message Length, maximum value used for dbc generation";
CM_ SG_ 2566843209 Sn_FEEB49 "- 10+1 characters maximum; Manufacturer assigned (IVECO Std. 18-2253)
-  Optional (IVECO Std. 18-2253), delimiter only if not supported
-  Variable signal length, 8 bits used for dbc generation only";
CM_ SG_ 2566843209 Model_FEEB49 "- 15+1 characters maximum; Manufacturer assigned Component/ECU Model or P/N(IVECO Std. 18-2253)
-  Variable signal length, 8 bits used for dbc generation only";
CM_ SG_ 2566843209 Make_FEEB49 "- Variable signal length, 8 bits used for dbc generation only";
CM_ BO_ 2566843210 "- Delimiter (�*�) required after each parameter, even if not used
-  Multipacket message handled by SAE Transport Protocol (J1939/21, par 5.10, Multipacket Broadcast with TP.CM/BAM, TP.DT)
-  Transport Protocol with Control Flow  (RTS, CTS, EndOfMsgAck, Conn_Abort) shall be also supported by the receiver if the multipacket message has been solicited by a Destination Specific Request
-  Variable Message Length, maximum value used for dbc generation";
CM_ SG_ 2566843210 UnitNumPwrUnit_FEEB4A "- 15+1 characters maximum
-  Optional, delimiter only if not supported
-  Variable signal length, 8 bits used for dbc generation only";
CM_ SG_ 2566843210 Sn_FEEB4A "- 10+1 characters maximum; Manufacturer assigned (IVECO Std. 18-2253)
-  Optional (IVECO Std. 18-2253), delimiter only if not supported
-  Variable signal length, 8 bits used for dbc generation only";
CM_ SG_ 2566843210 Model_FEEB4A "- 15+1 characters maximum; Manufacturer assigned Component/ECU Model or P/N(IVECO Std. 18-2253)
-  Variable signal length, 8 bits used for dbc generation only";
CM_ SG_ 2566843210 Make_FEEB4A "- Variable signal length, 8 bits used for dbc generation only";
CM_ BO_ 2566843213 "- Delimiter (�*�) required after each parameter, even if not used
-  Multipacket message handled by SAE Transport Protocol (J1939/21, par 5.10, Multipacket Broadcast with TP.CM/BAM, TP.DT)
-  Transport Protocol with Control Flow  (RTS, CTS, EndOfMsgAck, Conn_Abort) shall be also supported by the receiver if the multipacket message has been solicited by a Destination Specific Request
-  Variable Message Length, maximum value used for dbc generation";
CM_ SG_ 2566843213 UnitNumPwrUnit_FEEB4D "- 15+1 characters maximum
-  Optional, delimiter only if not supported
-  Variable signal length, 8 bits used for dbc generation only";
CM_ SG_ 2566843213 Sn_FEEB4D "- 10+1 characters maximum; Manufacturer assigned (IVECO Std. 18-2253)
-  Optional (IVECO Std. 18-2253), delimiter only if not supported
-  Variable signal length, 8 bits used for dbc generation only";
CM_ SG_ 2566843213 Model_FEEB4D "- 15+1 characters maximum; Manufacturer assigned Component/ECU Model or P/N(IVECO Std. 18-2253)
-  Variable signal length, 8 bits used for dbc generation only";
CM_ SG_ 2566843213 Make_FEEB4D "- Variable signal length, 8 bits used for dbc generation only";
CM_ BO_ 2566843256 "- Delimiter (�*�) required after each parameter, even if not used
-  Multipacket message handled by SAE Transport Protocol (J1939/21, par 5.10, Multipacket Broadcast with TP.CM/BAM, TP.DT)
-  Transport Protocol with Control Flow  (RTS, CTS, EndOfMsgAck, Conn_Abort) shall be also supported by the receiver if the multipacket message has been solicited by a Destination Specific Request
-  Variable Message Length, maximum value used for dbc generation";
CM_ SG_ 2566843256 UnitNumPwrUnit_FEEB78 "- 15+1 characters maximum
-  Optional, delimiter only if not supported
-  Variable signal length, 8 bits used for dbc generation only";
CM_ SG_ 2566843256 Sn_FEEB78 "- 10+1 characters maximum; Manufacturer assigned (IVECO Std. 18-2253)
-  Optional (IVECO Std. 18-2253), delimiter only if not supported
-  Variable signal length, 8 bits used for dbc generation only";
CM_ SG_ 2566843256 Model_FEEB78 "- 15+1 characters maximum; Manufacturer assigned Component/ECU Model or P/N(IVECO Std. 18-2253)
-  Variable signal length, 8 bits used for dbc generation only";
CM_ SG_ 2566843256 Make_FEEB78 "- Variable signal length, 8 bits used for dbc generation only";
CM_ BO_ 2566843260 "- Delimiter (�*�) required after each parameter, even if not used
-  Multipacket message handled by SAE Transport Protocol (J1939/21, par 5.10, Multipacket Broadcast with TP.CM/BAM, TP.DT)
-  Transport Protocol with Control Flow  (RTS, CTS, EndOfMsgAck, Conn_Abort) shall be also supported by the receiver if the multipacket message has been solicited by a Destination Specific Request
-  Variable Message Length, maximum value used for dbc generation";
CM_ SG_ 2566843260 Sn_FEEB7C "- 10+1 characters maximum; Manufacturer assigned (IVECO Std. 18-2253)
-  Optional (IVECO Std. 18-2253), delimiter only if not supported
-  Variable signal length, 8 bits used for dbc generation only";
CM_ SG_ 2566843260 Model_FEEB7C "- 15+1 characters maximum; Manufacturer assigned Component/ECU Model or P/N(IVECO Std. 18-2253)
-  Variable signal length, 8 bits used for dbc generation only";
CM_ SG_ 2566843260 Make_FEEB7C "- Variable signal length, 8 bits used for dbc generation only";
CM_ BO_ 2566843375 "- Delimiter (�*�) required after each parameter, even if not used
-  Multipacket message handled by SAE Transport Protocol (J1939/21, par 5.10, Multipacket Broadcast with TP.CM/BAM, TP.DT)
-  Transport Protocol with Control Flow  (RTS, CTS, EndOfMsgAck, Conn_Abort) shall be also supported by the receiver if the multipacket message has been solicited by a Destination Specific Request
-  Variable Message Length, maximum value used for dbc generation";
CM_ SG_ 2566843375 Sn_FEEBEF "- 10+1 characters maximum; Manufacturer assigned (IVECO Std. 18-2253)
-  Optional (IVECO Std. 18-2253), delimiter only if not supported
-  Variable signal length, 8 bits used for dbc generation only";
CM_ SG_ 2566843375 Model_FEEBEF "- 15+1 characters maximum; Manufacturer assigned Component/ECU Model or P/N(IVECO Std. 18-2253)
-  Variable signal length, 8 bits used for dbc generation only";
CM_ SG_ 2566843375 Make_FEEBEF "- Variable signal length, 8 bits used for dbc generation only";
CM_ BO_ 2566843378 "- Delimiter (�*�) required after each parameter, even if not used
-  Multipacket message handled by SAE Transport Protocol (J1939/21, par 5.10, Multipacket Broadcast with TP.CM/BAM, TP.DT)
-  Transport Protocol with Control Flow  (RTS, CTS, EndOfMsgAck, Conn_Abort) shall be also supported by the receiver if the multipacket message has been solicited by a Destination Specific Request
-  Variable Message Length, maximum value used for dbc generation";
CM_ SG_ 2566843378 Sn_FEEBF2 "- 10+1 characters maximum; Manufacturer assigned (IVECO Std. 18-2253)
-  Optional (IVECO Std. 18-2253), delimiter only if not supported
-  Variable signal length, 8 bits used for dbc generation only";
CM_ SG_ 2566843378 Model_FEEBF2 "- 15+1 characters maximum; Manufacturer assigned Component/ECU Model or P/N(IVECO Std. 18-2253)
-  Variable signal length, 8 bits used for dbc generation only";
CM_ SG_ 2566843378 Make_FEEBF2 "- Variable signal length, 8 bits used for dbc generation only";
CM_ BO_ 2566843379 "- Delimiter (�*�) required after each parameter, even if not used
-  Multipacket message handled by SAE Transport Protocol (J1939/21, par 5.10, Multipacket Broadcast with TP.CM/BAM, TP.DT)
-  Transport Protocol with Control Flow  (RTS, CTS, EndOfMsgAck, Conn_Abort) shall be also supported by the receiver if the multipacket message has been solicited by a Destination Specific Request
-  Variable Message Length, maximum value used for dbc generation";
CM_ SG_ 2566843379 Sn_FEEBF3 "- 10+1 characters maximum; Manufacturer assigned (IVECO Std. 18-2253)
-  Optional (IVECO Std. 18-2253), delimiter only if not supported
-  Variable signal length, 8 bits used for dbc generation only";
CM_ SG_ 2566843379 Model_FEEBF3 "- 15+1 characters maximum; Manufacturer assigned Component/ECU Model or P/N(IVECO Std. 18-2253)
-  Variable signal length, 8 bits used for dbc generation only";
CM_ SG_ 2566843379 Make_FEEBF3 "- Variable signal length, 8 bits used for dbc generation only";
CM_ BO_ 2564882179 "- SAE Trans.Rate=1000ms
-  Transmitted every 1s and on change of state but no faster than every 100 ms";
CM_ BO_ 2564882201 "- SAE Trans.Rate=1000ms";
CM_ SG_ 2564882201 CabInternTempCmd "- 0x0000 for LO,  0xFAFF for HI, 0xFFFF for NoRequest / Off
-  BCM S-Way MY19 set to 0xFFFF as initial value";
CM_ SG_ 2564882209 SeatBeltSw "- 10b used for Not fastened, alarm";
CM_ SG_ 2564882209 CabInternTempCmd_E0FF21 "- 0x0000 for LO,  0xFAFF for HI, 0xFFFF for NoRequest / Off";
CM_ SG_ 2564882250 BatMainSwHoldReq_E0FF4A "- VT Custom (00b : Network ON - PCM present, Network Available; 01b : Network OFF - PCM present, Network Not Available)";
CM_ BO_ 2566811659 "- Cyclic Transmission Rate as result of PGN requests
-  FMS Trans.Rate=1s
-  SAE Trans.Rate=OnRequest";
CM_ SG_ 2566802967 Sts2OfDoors "- 00 Unlock, 01 Lock";
CM_ BO_ 2566810606 "-  2 Message Variant(s): Transm.Rates 10000, OnRequest
-  Cyclic Transmission Rate as result of PGN requests
-  Multipacket message handled by SAE Transport Protocol (J1939/21, par 5.10, Multipacket Broadcast with TP.CM/BAM, TP.DT)
-  Variable Message Length, maximum value used for dbc generation
-  Multipacket message handled by SAE Transport Protocol (J1939/21, par 5.10, Multipacket Broadcast with TP.CM/BAM, TP.DT)
-  Variable Message Length, maximum value used for dbc generation";
CM_ SG_ 2566810606 Driv2Id "- Issuing member state + CardNumber = 3 + 16 Byte (acc. ISO 16844)
-  Variable signal length, 8 bits used for dbc generation only
-  Variable signal position, SPN Position value used for dbc generation only";
CM_ SG_ 2566810606 Driv1Id "- Issuing member state + CardNumber = 3 + 16 Byte (acc. ISO 16844)
-  Variable signal length, 8 bits used for dbc generation only";
CM_ SG_ 2566718743 EngWaitToStartLampData "- 10b used for Error Indicator, 01b if lamp on or blinking";
CM_ SG_ 2566718743 ObdMilData "- 10b used for Error Indicator, 01b if lamp on or blinking";
CM_ BO_ 2566834688 "- Multipacket message handled by SAE Transport Protocol (J1939/21, par 5.10, Multipacket Broadcast with TP.CM/BAM, TP.DT)
-  Variable Message Length, maximum value used for dbc generation";
CM_ SG_ 2566834688 SpnCm20 "- Always 0b";
CM_ BO_ 2566834691 "- Multipacket message handled by SAE Transport Protocol (J1939/21, par 5.10, Multipacket Broadcast with TP.CM/BAM, TP.DT)
-  Variable Message Length, maximum value used for dbc generation";
CM_ SG_ 2566834691 SpnCm10 "- Always 0b";
CM_ BO_ 2566834693 "- Multipacket message handled by SAE Transport Protocol (J1939/21, par 5.10, Multipacket Broadcast with TP.CM/BAM, TP.DT)
-  Variable Message Length, maximum value used for dbc generation";
CM_ SG_ 2566834693 SpnCm10_FECA05 "- Always 0b";
CM_ BO_ 2566834695 "- Multipacket message handled by SAE Transport Protocol (J1939/21, par 5.10, Multipacket Broadcast with TP.CM/BAM, TP.DT)
-  Variable Message Length, maximum value used for dbc generation";
CM_ SG_ 2566834695 SpnCm10_FECA07 "- Always 0b";
CM_ BO_ 2566834699 "- Multipacket message handled by SAE Transport Protocol (J1939/21, par 5.10, Multipacket Broadcast with TP.CM/BAM, TP.DT)
-  Variable Message Length, maximum value used for dbc generation";
CM_ SG_ 2566834699 SpnCm10_FECA0B "- Always 0b";
CM_ BO_ 2566834704 "- Multipacket message handled by SAE Transport Protocol (J1939/21, par 5.10, Multipacket Broadcast with TP.CM/BAM, TP.DT)
-  Variable Message Length, maximum value used for dbc generation";
CM_ SG_ 2566834704 SpnCm10_FECA10 "- Always 00b";
CM_ BO_ 2566834707 "- Multipacket message handled by SAE Transport Protocol (J1939/21, par 5.10, Multipacket Broadcast with TP.CM/BAM, TP.DT)
-  Variable Message Length, maximum value used for dbc generation";
CM_ SG_ 2566834707 SpnCm10_FECA13 "- Always 0b";
CM_ BO_ 2566834711 "- Multipacket message handled by SAE Transport Protocol (J1939/21, par 5.10, Multipacket Broadcast with TP.CM/BAM, TP.DT)
-  Variable Message Length, maximum value used for dbc generation";
CM_ SG_ 2566834711 SpnCm20_FECA17 "- Always 0b";
CM_ BO_ 2566834713 "- Multipacket message handled by SAE Transport Protocol (J1939/21, par 5.10, Multipacket Broadcast with TP.CM/BAM, TP.DT)
-  Variable Message Length, maximum value used for dbc generation";
CM_ SG_ 2566834713 SpnCm10_FECA19 "- Always 0b";
CM_ BO_ 2566834714 "- Multipacket message handled by SAE Transport Protocol (J1939/21, par 5.10, Multipacket Broadcast with TP.CM/BAM, TP.DT)
-  Variable Message Length, maximum value used for dbc generation";
CM_ SG_ 2566834714 SpnCm10_FECA1A "- Always 0b";
CM_ BO_ 2566834717 "- Multipacket message handled by SAE Transport Protocol (J1939/21, par 5.10, Multipacket Broadcast with TP.CM/BAM, TP.DT)
-  Variable Message Length, maximum value used for dbc generation";
CM_ SG_ 2566834717 SpnCm10_FECA1D "- Always 0b";
CM_ BO_ 2566834721 "- Multipacket message handled by SAE Transport Protocol (J1939/21, par 5.10, Multipacket Broadcast with TP.CM/BAM, TP.DT)
-  Variable Message Length, maximum value used for dbc generation";
CM_ SG_ 2566834721 SpnCm10_FECA21 "- Always 0b";
CM_ BO_ 2566834724 "- Multipacket message handled by SAE Transport Protocol (J1939/21, par 5.10, Multipacket Broadcast with TP.CM/BAM, TP.DT)
-  Variable Message Length, maximum value used for dbc generation";
CM_ SG_ 2566834724 SpnCm10_FECA24 "- Always 0b";
CM_ BO_ 2566834727 "- Multipacket message handled by SAE Transport Protocol (J1939/21, par 5.10, Multipacket Broadcast with TP.CM/BAM, TP.DT)
-  Variable Message Length, maximum value used for dbc generation";
CM_ SG_ 2566834727 SpnCm10_FECA27 "- Always 0b";
CM_ BO_ 2566834730 "- Multipacket message handled by SAE Transport Protocol (J1939/21, par 5.10, Multipacket Broadcast with TP.CM/BAM, TP.DT)
-  Variable Message Length, maximum value used for dbc generation";
CM_ SG_ 2566834730 SpnCm10_FECA2A "- Always 0b";
CM_ BO_ 2566834735 "- Multipacket message handled by SAE Transport Protocol (J1939/21, par 5.10, Multipacket Broadcast with TP.CM/BAM, TP.DT)
-  Variable Message Length, maximum value used for dbc generation";
CM_ SG_ 2566834735 SpnCm10_FECA2F "- Always 0b";
CM_ BO_ 2566834736 "- Multipacket message handled by SAE Transport Protocol (J1939/21, par 5.10, Multipacket Broadcast with TP.CM/BAM, TP.DT)
-  Variable Message Length, maximum value used for dbc generation";
CM_ SG_ 2566834736 SpnCm10_FECA30 "- Always 0b";
CM_ BO_ 2566834739 "- Multipacket message handled by SAE Transport Protocol (J1939/21, par 5.10, Multipacket Broadcast with TP.CM/BAM, TP.DT)
-  Variable Message Length, maximum value used for dbc generation";
CM_ SG_ 2566834739 SpnCm10_FECA33 "- Always 0b";
CM_ BO_ 2566834753 "- Multipacket message handled by SAE Transport Protocol (J1939/21, par 5.10, Multipacket Broadcast with TP.CM/BAM, TP.DT)
-  Variable Message Length, maximum value used for dbc generation";
CM_ SG_ 2566834753 SpnCm10_FECA41 "- Always 0b";
CM_ BO_ 2566834761 "- Multipacket message handled by SAE Transport Protocol (J1939/21, par 5.10, Multipacket Broadcast with TP.CM/BAM, TP.DT)
-  Variable Message Length, maximum value used for dbc generation";
CM_ SG_ 2566834761 SpnCm10_FECA49 "- Always 0b";
CM_ BO_ 2566834765 "- Multipacket message handled by SAE Transport Protocol (J1939/21, par 5.10, Multipacket Broadcast with TP.CM/BAM, TP.DT)
-  Transmitted in C-Roads and Ensemble Project by FOBS
-  Variable Message Length, maximum value used for dbc generation";
CM_ SG_ 2566834765 SpnCm10_FECA4D "- Always 0b";
CM_ BO_ 2566834771 "- Multipacket message handled by SAE Transport Protocol (J1939/21, par 5.10, Multipacket Broadcast with TP.CM/BAM, TP.DT)
-  Variable Message Length, maximum value used for dbc generation";
CM_ SG_ 2566834771 SpnCm10_FECA53 "- Always 0b";
CM_ BO_ 2566834802 "- Multipacket message handled by SAE Transport Protocol (J1939/21, par 5.10, Multipacket Broadcast with TP.CM/BAM, TP.DT)
-  Variable Message Length, maximum value used for dbc generation";
CM_ SG_ 2566834802 SpnCm10_FECA72 "- Always 0b";
CM_ BO_ 2566834808 "- Multipacket message handled by SAE Transport Protocol (J1939/21, par 5.10, Multipacket Broadcast with TP.CM/BAM, TP.DT)
-  Variable Message Length, maximum value used for dbc generation";
CM_ SG_ 2566834808 SpnCm10_FECA78 "- Always 0b";
CM_ BO_ 2566834812 "- Multipacket message handled by SAE Transport Protocol (J1939/21, par 5.10, Multipacket Broadcast with TP.CM/BAM, TP.DT)
-  Variable Message Length, maximum value used for dbc generation";
CM_ SG_ 2566834812 SpnCm10_FECA7C "- Always 0b";
CM_ BO_ 2566834817 "- Multipacket message handled by SAE Transport Protocol (J1939/21, par 5.10, Multipacket Broadcast with TP.CM/BAM, TP.DT)
-  Variable Message Length, maximum value used for dbc generation";
CM_ SG_ 2566834817 SpnCm10_FECA81 "- Always 0b";
CM_ BO_ 2566834844 "- Multipacket message handled by SAE Transport Protocol (J1939/21, par 5.10, Multipacket Broadcast with TP.CM/BAM, TP.DT)
-  Variable Message Length, maximum value used for dbc generation";
CM_ SG_ 2566834844 SpnCm10_FECA9C "- Always 0b";
CM_ BO_ 2566834846 "- Multipacket message handled by SAE Transport Protocol (J1939/21, par 5.10, Multipacket Broadcast with TP.CM/BAM, TP.DT)
-  Variable Message Length, maximum value used for dbc generation";
CM_ SG_ 2566834846 SpnCm10_FECA9E "- Always 0b";
CM_ BO_ 2566834847 "- Multipacket message handled by SAE Transport Protocol (J1939/21, par 5.10, Multipacket Broadcast with TP.CM/BAM, TP.DT)
-  Transport Protocol Packets (TP.CM, TP.DT) Priority=7
-  Variable Message Length, maximum value used for dbc generation";
CM_ SG_ 2566834847 SpnCm10_FECA9F "- Always 0b";
CM_ BO_ 2566834848 "- Multipacket message handled by SAE Transport Protocol (J1939/21, par 5.10, Multipacket Broadcast with TP.CM/BAM, TP.DT)
-  Variable Message Length, maximum value used for dbc generation";
CM_ SG_ 2566834848 SpnCm10_FECAA0 "- Always 0b";
CM_ BO_ 2566834889 "- Multipacket message handled by SAE Transport Protocol (J1939/21, par 5.10, Multipacket Broadcast with TP.CM/BAM, TP.DT)
-  Variable Message Length, maximum value used for dbc generation";
CM_ BO_ 2566834917 "- Multipacket message handled by SAE Transport Protocol (J1939/21, par 5.10, Multipacket Broadcast with TP.CM/BAM, TP.DT)
-  Variable Message Length, maximum value used for dbc generation";
CM_ SG_ 2566834917 SpnCm10_FECAE5 "- Always 0b";
CM_ BO_ 2566834926 "- Multipacket message handled by SAE Transport Protocol (J1939/21, par 5.10, Multipacket Broadcast with TP.CM/BAM, TP.DT)
-  Variable Message Length, maximum value used for dbc generation";
CM_ SG_ 2566834926 SpnCm10_FECAEE "- Always 0b";
CM_ BO_ 2566834927 "- Multipacket message handled by SAE Transport Protocol (J1939/21, par 5.10, Multipacket Broadcast with TP.CM/BAM, TP.DT)
-  Variable Message Length, maximum value used for dbc generation";
CM_ BO_ 2566834930 "- Multipacket message handled by SAE Transport Protocol (J1939/21, par 5.10, Multipacket Broadcast with TP.CM/BAM, TP.DT)
-  Variable Message Length, maximum value used for dbc generation";
CM_ BO_ 2566834931 "- Multipacket message handled by SAE Transport Protocol (J1939/21, par 5.10, Multipacket Broadcast with TP.CM/BAM, TP.DT)
-  Variable Message Length, maximum value used for dbc generation";
CM_ SG_ 2566834931 SpnCm10_FECAF3 "- Always 0b";
CM_ BO_ 2566834947 "- Multipacket message handled by SAE Transport Protocol (J1939/21, par 5.10, Multipacket Broadcast with TP.CM/BAM, TP.DT)
-  Transport Protocol with Control Flow  (RTS, CTS, EndOfMsgAck, Conn_Abort) shall be also supported by the receiver if the multipacket message has been solicited by a Destination Specific Request
-  Variable Message Length, maximum value used for dbc generation";
CM_ BO_ 2566834949 "- Multipacket message handled by SAE Transport Protocol (J1939/21, par 5.10, Multipacket Broadcast with TP.CM/BAM, TP.DT)
-  Variable Message Length, maximum value used for dbc generation";
CM_ SG_ 2566834949 SpnCm10_FECB05 "- Always 0b";
CM_ BO_ 2566834951 "- Multipacket message handled by SAE Transport Protocol (J1939/21, par 5.10, Multipacket Broadcast with TP.CM/BAM, TP.DT)
-  Variable Message Length, maximum value used for dbc generation";
CM_ SG_ 2566834951 SpnCm10_FECB07 "- Always 0b";
CM_ BO_ 2566834970 "- Multipacket message handled by SAE Transport Protocol (J1939/21, par 5.10, Multipacket Broadcast with TP.CM/BAM, TP.DT)
-  Variable Message Length, maximum value used for dbc generation";
CM_ SG_ 2566834970 SpnCm10_FECB1A "- Always 0b";
CM_ BO_ 2566834973 "- Multipacket message handled by SAE Transport Protocol (J1939/21, par 5.10, Multipacket Broadcast with TP.CM/BAM, TP.DT)
-  Transport Protocol with Control Flow  (RTS, CTS, EndOfMsgAck, Conn_Abort) shall be also supported by the receiver if the multipacket message has been solicited by a Destination Specific Request
-  Variable Message Length, maximum value used for dbc generation";
CM_ SG_ 2566834973 SpnCm10_FECB1D "- Always 0b";
CM_ BO_ 2566834980 "- Multipacket message handled by SAE Transport Protocol (J1939/21, par 5.10, Multipacket Broadcast with TP.CM/BAM, TP.DT)
-  Variable Message Length, maximum value used for dbc generation";
CM_ SG_ 2566834980 SpnCm10_FECB24 "- Always 0b";
CM_ BO_ 2566834991 "- Multipacket message handled by SAE Transport Protocol (J1939/21, par 5.10, Multipacket Broadcast with TP.CM/BAM, TP.DT)
-  Transport Protocol with Control Flow  (RTS, CTS, EndOfMsgAck, Conn_Abort) shall be also supported by the receiver if the multipacket message has been solicited by a Destination Specific Request
-  Variable Message Length, maximum value used for dbc generation";
CM_ SG_ 2566834991 SpnCm10_FECB2F "- Always 0b";
CM_ BO_ 2566834992 "- Multipacket message handled by SAE Transport Protocol (J1939/21, par 5.10, Multipacket Broadcast with TP.CM/BAM, TP.DT)
-  Variable Message Length, maximum value used for dbc generation";
CM_ SG_ 2566834992 SpnCm10_FECB30 "- Always 0b";
CM_ BO_ 2566834995 "- Multipacket message handled by SAE Transport Protocol (J1939/21, par 5.10, Multipacket Broadcast with TP.CM/BAM, TP.DT)
-  Variable Message Length, maximum value used for dbc generation";
CM_ BO_ 2566835017 "- Multipacket message handled by SAE Transport Protocol (J1939/21, par 5.10, Multipacket Broadcast with TP.CM/BAM, TP.DT)
-  Variable Message Length, maximum value used for dbc generation";
CM_ SG_ 2566835017 SpnCm10_FECB49 "- Always 0b";
CM_ BO_ 2566835018 "- Multipacket message handled by SAE Transport Protocol (J1939/21, par 5.10, Multipacket Broadcast with TP.CM/BAM, TP.DT)
-  Transport Protocol with Control Flow  (RTS, CTS, EndOfMsgAck, Conn_Abort) shall be also supported by the receiver if the multipacket message has been solicited by a Destination Specific Request
-  Variable Message Length, maximum value used for dbc generation";
CM_ SG_ 2566835018 SpnCm10_FECB4A "- Always 0b";
CM_ BO_ 2566835021 "- Multipacket message handled by SAE Transport Protocol (J1939/21, par 5.10, Multipacket Broadcast with TP.CM/BAM, TP.DT)
-  Transport Protocol with Control Flow  (RTS, CTS, EndOfMsgAck, Conn_Abort) shall be also supported by the receiver if the multipacket message has been solicited by a Destination Specific Request
-  Variable Message Length, maximum value used for dbc generation";
CM_ SG_ 2566835021 SpnCm10_FECB4D "- Always 0b";
CM_ BO_ 2566835058 "- Multipacket message handled by SAE Transport Protocol (J1939/21, par 5.10, Multipacket Broadcast with TP.CM/BAM, TP.DT)
-  Transport Protocol with Control Flow  (RTS, CTS, EndOfMsgAck, Conn_Abort) shall be also supported by the receiver if the multipacket message has been solicited by a Destination Specific Request
-  Variable Message Length, maximum value used for dbc generation";
CM_ SG_ 2566835058 SpnCm10_FECB72 "- Always 0b";
CM_ BO_ 2566835068 "- Multipacket message handled by SAE Transport Protocol (J1939/21, par 5.10, Multipacket Broadcast with TP.CM/BAM, TP.DT)
-  Variable Message Length, maximum value used for dbc generation";
CM_ SG_ 2566835068 SpnCm10_FECB7C "- Always 0b";
CM_ BO_ 2566835183 "- Multipacket message handled by SAE Transport Protocol (J1939/21, par 5.10, Multipacket Broadcast with TP.CM/BAM, TP.DT)
-  Transport Protocol with Control Flow  (RTS, CTS, EndOfMsgAck, Conn_Abort) shall be also supported by the receiver if the multipacket message has been solicited by a Destination Specific Request
-  Variable Message Length, maximum value used for dbc generation";
CM_ SG_ 2566835183 SpnCm10_FECBEF "- Always 0b";
CM_ BO_ 2566835186 "- Multipacket message handled by SAE Transport Protocol (J1939/21, par 5.10, Multipacket Broadcast with TP.CM/BAM, TP.DT)
-  Transport Protocol with Control Flow  (RTS, CTS, EndOfMsgAck, Conn_Abort) shall be also supported by the receiver if the multipacket message has been solicited by a Destination Specific Request
-  Variable Message Length, maximum value used for dbc generation";
CM_ SG_ 2566835186 SpnCm10_FECBF2 "- Always 0b";
CM_ BO_ 2566835187 "- Multipacket message handled by SAE Transport Protocol (J1939/21, par 5.10, Multipacket Broadcast with TP.CM/BAM, TP.DT)
-  Transport Protocol with Control Flow  (RTS, CTS, EndOfMsgAck, Conn_Abort) shall be also supported by the receiver if the multipacket message has been solicited by a Destination Specific Request
-  Variable Message Length, maximum value used for dbc generation";
CM_ SG_ 2566835187 SpnCm10_FECBF3 "- Always 0b";
CM_ BO_ 2566835459 "- Freeze Parameters taken at last fault occurrence
-  Multipacket message handled by SAE Transport Protocol (J1939/21, par 5.10, Multipacket Broadcast with TP.CM/BAM, TP.DT)
-  Variable Message Length, maximum value used for dbc generation";
CM_ BO_ 2566835461 "- Freeze Parameters taken at last fault occurrence
-  Multipacket message handled by SAE Transport Protocol (J1939/21, par 5.10, Multipacket Broadcast with TP.CM/BAM, TP.DT)
-  Variable Message Length, maximum value used for dbc generation";
CM_ SG_ 2566835461 HrTotVehDist_10 "- �Manufacturer Specified Information� as per IVECO 18-2253";
CM_ BO_ 2566835463 "- Freeze Parameters taken at last fault occurrence
-  Multipacket message handled by SAE Transport Protocol (J1939/21, par 5.10, Multipacket Broadcast with TP.CM/BAM, TP.DT)
-  Variable Message Length, maximum value used for dbc generation";
CM_ SG_ 2566835463 HrTotVehDist_10_FECD07 "- �Manufacturer Specified Information� as per IVECO 18-2253";
CM_ BO_ 2566835482 "- Freeze Parameters taken at last fault occurrence
-  Multipacket message handled by SAE Transport Protocol (J1939/21, par 5.10, Multipacket Broadcast with TP.CM/BAM, TP.DT)
-  Variable Message Length, maximum value used for dbc generation";
CM_ SG_ 2566835482 HrTotVehDist_10_FECD1A "- �Manufacturer Specified Information� as per IVECO 18-2253";
CM_ BO_ 2566835485 "- Freeze Parameters taken at last fault occurrence
-  Multipacket message handled by SAE Transport Protocol (J1939/21, par 5.10, Multipacket Broadcast with TP.CM/BAM, TP.DT)
-  Variable Message Length, maximum value used for dbc generation";
CM_ SG_ 2566835485 HrTotVehDist_10_FECD1D "- �Manufacturer Specified Information� as per IVECO 18-2253";
CM_ BO_ 2566835492 "- Freeze Parameters taken at last fault occurrence
-  Multipacket message handled by SAE Transport Protocol (J1939/21, par 5.10, Multipacket Broadcast with TP.CM/BAM, TP.DT)
-  Variable Message Length, maximum value used for dbc generation";
CM_ SG_ 2566835492 HrTotVehDist_10_FECD24 "- �Manufacturer Specified Information� as per IVECO 18-2253";
CM_ BO_ 2566835503 "- Freeze Parameters taken at last fault occurrence
-  Multipacket message handled by SAE Transport Protocol (J1939/21, par 5.10, Multipacket Broadcast with TP.CM/BAM, TP.DT)
-  Variable Message Length, maximum value used for dbc generation";
CM_ SG_ 2566835503 HrTotVehDist_10_FECD2F "- �Manufacturer Specified Information� as per IVECO 18-2253";
CM_ BO_ 2566835504 "- Freeze Parameters taken at last fault occurrence
-  Multipacket message handled by SAE Transport Protocol (J1939/21, par 5.10, Multipacket Broadcast with TP.CM/BAM, TP.DT)
-  Variable Message Length, maximum value used for dbc generation";
CM_ SG_ 2566835504 HrTotVehDist_10_FECD30 "- �Manufacturer Specified Information� as per IVECO 18-2253";
CM_ BO_ 2566835529 "- Freeze Parameters taken at last fault occurrence
-  Multipacket message handled by SAE Transport Protocol (J1939/21, par 5.10, Multipacket Broadcast with TP.CM/BAM, TP.DT)
-  Variable Message Length, maximum value used for dbc generation";
CM_ SG_ 2566835529 HrTotVehDist_10_FECD49 "- �Manufacturer Specified Information� as per IVECO 18-2253";
CM_ BO_ 2566835530 "- Freeze Parameters taken at last fault occurrence
-  Multipacket message handled by SAE Transport Protocol (J1939/21, par 5.10, Multipacket Broadcast with TP.CM/BAM, TP.DT)
-  Variable Message Length, maximum value used for dbc generation";
CM_ SG_ 2566835530 HrTotVehDist_10_FECD4A "- �Manufacturer Specified Information� as per IVECO 18-2253";
CM_ BO_ 2566835533 "- Freeze Parameters taken at last fault occurrence
-  Multipacket message handled by SAE Transport Protocol (J1939/21, par 5.10, Multipacket Broadcast with TP.CM/BAM, TP.DT)
-  Variable Message Length, maximum value used for dbc generation";
CM_ SG_ 2566835533 HrTotVehDist_10_FECD4D "- �Manufacturer Specified Information� as per IVECO 18-2253";
CM_ BO_ 2566835539 "- Freeze Parameters taken at last fault occurrence
-  Multipacket message handled by SAE Transport Protocol (J1939/21, par 5.10, Multipacket Broadcast with TP.CM/BAM, TP.DT)
-  Variable Message Length, maximum value used for dbc generation";
CM_ SG_ 2566835539 HrTotVehDist_10_FECD53 "- �Manufacturer Specified Information� as per IVECO 18-2253";
CM_ BO_ 2566835576 "- Freeze Parameters taken at last fault occurrence
-  Multipacket message handled by SAE Transport Protocol (J1939/21, par 5.10, Multipacket Broadcast with TP.CM/BAM, TP.DT)
-  Variable Message Length, maximum value used for dbc generation";
CM_ SG_ 2566835576 HrTotVehDist_10_FECD78 "- �Manufacturer Specified Information� as per IVECO 18-2253";
CM_ BO_ 2566835580 "- Freeze Parameters taken at last fault occurrence
-  Multipacket message handled by SAE Transport Protocol (J1939/21, par 5.10, Multipacket Broadcast with TP.CM/BAM, TP.DT)
-  Variable Message Length, maximum value used for dbc generation";
CM_ SG_ 2566835580 HrTotVehDist_10_FECD7C "- �Manufacturer Specified Information� as per IVECO 18-2253";
CM_ BO_ 2566835657 "- Freeze Parameters taken at last fault occurrence
-  Multipacket message handled by SAE Transport Protocol (J1939/21, par 5.10, Multipacket Broadcast with TP.CM/BAM, TP.DT)
-  Variable Message Length, maximum value used for dbc generation";
CM_ SG_ 2566835657 HrTotVehDist_10_FECDC9 "- �Manufacturer Specified Information� as per IVECO 18-2253";
CM_ BO_ 2566835695 "- Freeze Parameters taken at last fault occurrence
-  Multipacket message handled by SAE Transport Protocol (J1939/21, par 5.10, Multipacket Broadcast with TP.CM/BAM, TP.DT)
-  Variable Message Length, maximum value used for dbc generation";
CM_ SG_ 2566835695 HrTotVehDist_10_FECDEF "- �Manufacturer Specified Information� as per IVECO 18-2253";
CM_ BO_ 2566835698 "- Freeze Parameters taken at last fault occurrence
-  Multipacket message handled by SAE Transport Protocol (J1939/21, par 5.10, Multipacket Broadcast with TP.CM/BAM, TP.DT)
-  Variable Message Length, maximum value used for dbc generation";
CM_ SG_ 2566835698 HrTotVehDist_10_FECDF2 "- �Manufacturer Specified Information� as per IVECO 18-2253";
CM_ BO_ 2566835699 "- Freeze Parameters taken at last fault occurrence
-  Multipacket message handled by SAE Transport Protocol (J1939/21, par 5.10, Multipacket Broadcast with TP.CM/BAM, TP.DT)
-  Variable Message Length, maximum value used for dbc generation";
CM_ SG_ 2566835699 HrTotVehDist_10_FECDF3 "- �Manufacturer Specified Information� as per IVECO 18-2253";
BA_DEF_ BO_  "CI_MsgDefinition" STRING ;
BA_DEF_ BO_  "CI_MsgId" INT 0 2147483647;
BA_DEF_ BO_  "CI_MsgName" STRING ;
BA_DEF_ BO_  "GenMsgCycleTime" INT 0 3600000;
BA_DEF_ BO_  "GenMsgCycleTimeFast" INT 0 3600000;
BA_DEF_ BO_  "GenMsgDelayTime" INT 0 3600000;
BA_DEF_ BO_  "GenMsgILSupport" ENUM  "No","Yes";
BA_DEF_ BO_  "GenMsgNrOfRepetition" INT 0 1000000;
BA_DEF_ BO_  "GenMsgRequestable" INT 0 1;
BA_DEF_ BO_  "GenMsgSendType" ENUM  "cyclic","NotUsed","NotUsed","NotUsed","NotUsed","NotUsed","NotUsed","IfActive","noMsgSendType";
BA_DEF_ BO_  "GenMsgStartDelayTime" INT 0 100000;
BA_DEF_ BO_  "TpJ1939VarDlc" ENUM  "No","Yes";
BA_DEF_ BO_  "VFrameFormat" ENUM  "StandardCAN","ExtendedCAN","reserved","J1939PG";
BA_DEF_ SG_  "CI_ParId" STRING ;
BA_DEF_ SG_  "CI_SigId" INT 0 2147483647;
BA_DEF_ SG_  "CI_SigName" STRING ;
BA_DEF_ SG_  "GenSigEVName" STRING ;
BA_DEF_ SG_  "GenSigILSupport" ENUM  "No","Yes";
BA_DEF_ SG_  "GenSigInactiveValue" INT 0 2147483647;
BA_DEF_ SG_  "GenSigSendType" ENUM  "Cyclic","OnWrite","OnWriteWithRepetition","OnChange","OnChangeWithRepetition","IfActive","IfActiveWithRepetition","NoSigSendType";
BA_DEF_ SG_  "GenSigStartValue" INT 0 2147483647;
BA_DEF_ SG_  "GenSigTimeoutTime_PCM" INT 0 3600000;
BA_DEF_ SG_  "GenSigTimeoutTime_SGW" INT 0 3600000;
BA_DEF_ SG_  "SPN" INT 0 524287;
BA_DEF_ SG_  "SigType" ENUM  "Default","Range","RangeSigned","ASCII","Discrete","Control","ReferencePGN","DTC","StringDelimiter","StringLength","StringLengthControl";
BA_DEF_DEF_  "CI_MsgDefinition" "";
BA_DEF_DEF_  "CI_MsgId" 0;
BA_DEF_DEF_  "CI_MsgName" "";
BA_DEF_DEF_  "GenMsgCycleTime" 0;
BA_DEF_DEF_  "GenMsgCycleTimeFast" 0;
BA_DEF_DEF_  "GenMsgDelayTime" 1;
BA_DEF_DEF_  "GenMsgILSupport" "Yes";
BA_DEF_DEF_  "GenMsgNrOfRepetition" 0;
BA_DEF_DEF_  "GenMsgRequestable" 0;
BA_DEF_DEF_  "GenMsgSendType" "noMsgSendType";
BA_DEF_DEF_  "GenMsgStartDelayTime" 0;
BA_DEF_DEF_  "TpJ1939VarDlc" "No";
BA_DEF_DEF_  "VFrameFormat" "J1939PG";
BA_DEF_DEF_  "CI_ParId" "";
BA_DEF_DEF_  "CI_SigId" 0;
BA_DEF_DEF_  "CI_SigName" "";
BA_DEF_DEF_  "GenSigEVName" "Env@Nodename_@Signame";
BA_DEF_DEF_  "GenSigILSupport" "Yes";
BA_DEF_DEF_  "GenSigInactiveValue" 0;
BA_DEF_DEF_  "GenSigSendType" "NoSigSendType";
BA_DEF_DEF_  "GenSigStartValue" 0;
BA_DEF_DEF_  "GenSigTimeoutTime_PCM" 0;
BA_DEF_DEF_  "GenSigTimeoutTime_SGW" 0;
BA_DEF_DEF_  "SPN" 0;
BA_DEF_DEF_  "SigType" "Default";
BA_ "CI_MsgDefinition" BO_ 2566723411 "J1939DA";
BA_ "CI_MsgId" BO_ 2566723411 4419;
BA_ "CI_MsgName" BO_ 2566723411 "BDS_53 - Beltlock and Airbag Deactivation Switch Information";
BA_ "GenMsgCycleTime" BO_ 2566723411 250;
BA_ "GenMsgCycleTimeFast" BO_ 2566723411 250;
BA_ "GenMsgDelayTime" BO_ 2566723411 125;
BA_ "GenMsgSendType" BO_ 2566723411 0;
BA_ "GenMsgStartDelayTime" BO_ 2566723411 107;
BA_ "CI_MsgDefinition" BO_ 2365579520 "Iveco Daily Proprietary";
BA_ "CI_MsgId" BO_ 2365579520 35787;
BA_ "CI_MsgName" BO_ 2365579520 "BsdSensor_00 - BSD Sensor Message";
BA_ "GenMsgCycleTime" BO_ 2365579520 10;
BA_ "GenMsgCycleTimeFast" BO_ 2365579520 10;
BA_ "GenMsgDelayTime" BO_ 2365579520 5;
BA_ "GenMsgSendType" BO_ 2365579520 0;
BA_ "GenMsgStartDelayTime" BO_ 2365579520 9;
BA_ "CI_MsgDefinition" BO_ 2566843648 "J1939DA";
BA_ "CI_MsgId" BO_ 2566843648 3209;
BA_ "CI_MsgName" BO_ 2566843648 "CCSS_00 - Cruise Control/Vehicle Speed Setup";
BA_ "GenMsgCycleTime" BO_ 2566843648 250;
BA_ "GenMsgCycleTimeFast" BO_ 2566843648 250;
BA_ "GenMsgDelayTime" BO_ 2566843648 125;
BA_ "GenMsgSendType" BO_ 2566843648 0;
BA_ "GenMsgStartDelayTime" BO_ 2566843648 111;
BA_ "CI_MsgDefinition" BO_ 2566843676 "J1939DA";
BA_ "CI_MsgId" BO_ 2566843676 3218;
BA_ "CI_MsgName" BO_ 2566843676 "CCSS_1C - Cruise Control/Vehicle Speed Setup";
BA_ "GenMsgCycleTime" BO_ 2566843676 1000;
BA_ "GenMsgCycleTimeFast" BO_ 2566843676 1000;
BA_ "GenMsgDelayTime" BO_ 2566843676 100;
BA_ "GenMsgSendType" BO_ 2566843676 0;
BA_ "GenMsgStartDelayTime" BO_ 2566843676 16;
BA_ "CI_MsgDefinition" BO_ 2566844672 "J1939DA";
BA_ "CI_MsgId" BO_ 2566844672 3029;
BA_ "CI_MsgName" BO_ 2566844672 "CCVS1 - Cruise Control/Vehicle Speed 1";
BA_ "GenMsgCycleTime" BO_ 2566844672 100;
BA_ "GenMsgCycleTimeFast" BO_ 2566844672 100;
BA_ "GenMsgDelayTime" BO_ 2566844672 50;
BA_ "GenMsgSendType" BO_ 2566844672 0;
BA_ "GenMsgStartDelayTime" BO_ 2566844672 78;
BA_ "CI_MsgDefinition" BO_ 2566844689 "J1939DA";
BA_ "CI_MsgId" BO_ 2566844689 3077;
BA_ "CI_MsgName" BO_ 2566844689 "CCVS1_11 - Cruise Control/Vehicle Speed 1";
BA_ "GenMsgCycleTime" BO_ 2566844689 100;
BA_ "GenMsgCycleTimeFast" BO_ 2566844689 100;
BA_ "GenMsgDelayTime" BO_ 2566844689 10;
BA_ "GenMsgSendType" BO_ 2566844689 0;
BA_ "GenMsgStartDelayTime" BO_ 2566844689 79;
BA_ "CI_MsgDefinition" BO_ 2566708224 "J1939DA";
BA_ "CI_MsgId" BO_ 2566708224 3163;
BA_ "CI_MsgName" BO_ 2566708224 "CCVS3 - Cruise Control / Vehicle Speed 3";
BA_ "GenMsgCycleTime" BO_ 2566708224 100;
BA_ "GenMsgCycleTimeFast" BO_ 2566708224 100;
BA_ "GenMsgDelayTime" BO_ 2566708224 50;
BA_ "GenMsgSendType" BO_ 2566708224 0;
BA_ "GenMsgStartDelayTime" BO_ 2566708224 68;
BA_ "CI_MsgDefinition" BO_ 2365321995 "J1939DA";
BA_ "CI_MsgId" BO_ 2365321995 3189;
BA_ "CI_MsgName" BO_ 2365321995 "CCVS5_0B - Cruise Control / Vehicle Speed 5";
BA_ "GenMsgCycleTime" BO_ 2365321995 20;
BA_ "GenMsgCycleTimeFast" BO_ 2365321995 20;
BA_ "GenMsgDelayTime" BO_ 2365321995 10;
BA_ "GenMsgSendType" BO_ 2365321995 0;
BA_ "GenMsgStartDelayTime" BO_ 2365321995 17;
BA_ "CI_MsgDefinition" BO_ 2566843136 "J1939DA";
BA_ "CI_MsgId" BO_ 2566843136 26045;
BA_ "CI_MsgName" BO_ 2566843136 "CI_00 - Component Identification";
BA_ "TpJ1939VarDlc" BO_ 2566843136 1;
BA_ "CI_MsgDefinition" BO_ 2566843141 "J1939DA";
BA_ "CI_MsgId" BO_ 2566843141 40723;
BA_ "CI_MsgName" BO_ 2566843141 "CI_05 - Component Identification";
BA_ "TpJ1939VarDlc" BO_ 2566843141 1;
BA_ "CI_MsgDefinition" BO_ 2566843143 "J1939DA";
BA_ "CI_MsgId" BO_ 2566843143 38548;
BA_ "CI_MsgName" BO_ 2566843143 "CI_07 - Component Identification";
BA_ "TpJ1939VarDlc" BO_ 2566843143 1;
BA_ "CI_MsgDefinition" BO_ 2566843159 "J1939DA";
BA_ "CI_MsgId" BO_ 2566843159 26080;
BA_ "CI_MsgName" BO_ 2566843159 "CI_17 - Component Identification";
BA_ "TpJ1939VarDlc" BO_ 2566843159 1;
BA_ "CI_MsgDefinition" BO_ 2566843162 "J1939DA";
BA_ "CI_MsgId" BO_ 2566843162 34476;
BA_ "CI_MsgName" BO_ 2566843162 "CI_1A - Component Identification";
BA_ "TpJ1939VarDlc" BO_ 2566843162 1;
BA_ "CI_MsgDefinition" BO_ 2566843165 "J1939DA";
BA_ "CI_MsgId" BO_ 2566843165 26095;
BA_ "CI_MsgName" BO_ 2566843165 "CI_1D - Component Identification";
BA_ "TpJ1939VarDlc" BO_ 2566843165 1;
BA_ "CI_MsgDefinition" BO_ 2566843172 "J1939DA";
BA_ "CI_MsgId" BO_ 2566843172 38553;
BA_ "CI_MsgName" BO_ 2566843172 "CI_24 - Component Identification";
BA_ "TpJ1939VarDlc" BO_ 2566843172 1;
BA_ "CI_MsgDefinition" BO_ 2566843175 "J1939DA";
BA_ "CI_MsgId" BO_ 2566843175 26105;
BA_ "CI_MsgName" BO_ 2566843175 "CI_27 - Component Identification";
BA_ "TpJ1939VarDlc" BO_ 2566843175 1;
BA_ "CI_MsgDefinition" BO_ 2566843183 "J1939DA";
BA_ "CI_MsgId" BO_ 2566843183 26115;
BA_ "CI_MsgName" BO_ 2566843183 "CI_2F - Component Identification";
BA_ "TpJ1939VarDlc" BO_ 2566843183 1;
BA_ "CI_MsgDefinition" BO_ 2566843184 "J1939DA";
BA_ "CI_MsgId" BO_ 2566843184 39838;
BA_ "CI_MsgName" BO_ 2566843184 "CI_30 - Component Identification";
BA_ "GenMsgDelayTime" BO_ 2566843184 10;
BA_ "TpJ1939VarDlc" BO_ 2566843184 1;
BA_ "CI_MsgDefinition" BO_ 2566843201 "J1939DA";
BA_ "CI_MsgId" BO_ 2566843201 26125;
BA_ "CI_MsgName" BO_ 2566843201 "CI_41 - Component Identification";
BA_ "TpJ1939VarDlc" BO_ 2566843201 1;
BA_ "CI_MsgDefinition" BO_ 2566843209 "J1939DA";
BA_ "CI_MsgId" BO_ 2566843209 34481;
BA_ "CI_MsgName" BO_ 2566843209 "CI_49 - Component Identification";
BA_ "TpJ1939VarDlc" BO_ 2566843209 1;
BA_ "CI_MsgDefinition" BO_ 2566843210 "J1939DA";
BA_ "CI_MsgId" BO_ 2566843210 26150;
BA_ "CI_MsgName" BO_ 2566843210 "CI_4A - Component Identification";
BA_ "TpJ1939VarDlc" BO_ 2566843210 1;
BA_ "CI_MsgDefinition" BO_ 2566843213 "J1939DA";
BA_ "CI_MsgId" BO_ 2566843213 37230;
BA_ "CI_MsgName" BO_ 2566843213 "CI_4D - Component Identification";
BA_ "TpJ1939VarDlc" BO_ 2566843213 1;
BA_ "CI_MsgDefinition" BO_ 2566843256 "J1939DA";
BA_ "CI_MsgId" BO_ 2566843256 40190;
BA_ "CI_MsgName" BO_ 2566843256 "CI_78 - Component Identification";
BA_ "TpJ1939VarDlc" BO_ 2566843256 1;
BA_ "CI_MsgDefinition" BO_ 2566843260 "J1939DA";
BA_ "CI_MsgId" BO_ 2566843260 36815;
BA_ "CI_MsgName" BO_ 2566843260 "CI_7C - Component Identification";
BA_ "TpJ1939VarDlc" BO_ 2566843260 1;
BA_ "CI_MsgDefinition" BO_ 2566843375 "J1939DA";
BA_ "CI_MsgId" BO_ 2566843375 34789;
BA_ "CI_MsgName" BO_ 2566843375 "CI_EF - Component Identification";
BA_ "TpJ1939VarDlc" BO_ 2566843375 1;
BA_ "CI_MsgDefinition" BO_ 2566843378 "J1939DA";
BA_ "CI_MsgId" BO_ 2566843378 39077;
BA_ "CI_MsgName" BO_ 2566843378 "CI_F2 - Component Identification";
BA_ "TpJ1939VarDlc" BO_ 2566843378 1;
BA_ "CI_MsgDefinition" BO_ 2566843379 "J1939DA";
BA_ "CI_MsgId" BO_ 2566843379 33375;
BA_ "CI_MsgName" BO_ 2566843379 "CI_F3 - Component Identification";
BA_ "TpJ1939VarDlc" BO_ 2566843379 1;
BA_ "CI_MsgDefinition" BO_ 2563833623 "J1939DA";
BA_ "CI_MsgId" BO_ 2563833623 4192;
BA_ "CI_MsgName" BO_ 2563833623 "CL_17 - Cab Illumination Message";
BA_ "GenMsgCycleTime" BO_ 2563833623 5000;
BA_ "GenMsgCycleTimeFast" BO_ 2563833623 5000;
BA_ "GenMsgDelayTime" BO_ 2563833623 100;
BA_ "GenMsgSendType" BO_ 2563833623 0;
BA_ "GenMsgStartDelayTime" BO_ 2563833623 335;
BA_ "CI_MsgDefinition" BO_ 2563829281 "J1939DA";
BA_ "CI_MsgId" BO_ 2563829281 4197;
BA_ "CI_MsgName" BO_ 2563829281 "CL_21_EE - Cab Illumination Message";
BA_ "GenMsgCycleTime" BO_ 2563829281 5000;
BA_ "GenMsgCycleTimeFast" BO_ 2563829281 5000;
BA_ "GenMsgDelayTime" BO_ 2563829281 100;
BA_ "GenMsgSendType" BO_ 2563829281 0;
BA_ "GenMsgStartDelayTime" BO_ 2563829281 334;
BA_ "CI_MsgDefinition" BO_ 2563833665 "J1939DA";
BA_ "CI_MsgId" BO_ 2563833665 4203;
BA_ "CI_MsgName" BO_ 2563833665 "CL_41 - Cab Illumination Message";
BA_ "GenMsgCycleTime" BO_ 2563833665 5000;
BA_ "GenMsgCycleTimeFast" BO_ 2563833665 5000;
BA_ "GenMsgDelayTime" BO_ 2563833665 100;
BA_ "GenMsgSendType" BO_ 2563833665 0;
BA_ "GenMsgStartDelayTime" BO_ 2563833665 336;
BA_ "CI_MsgDefinition" BO_ 2564882176 "J1939DA";
BA_ "CI_MsgId" BO_ 2564882176 3239;
BA_ "CI_MsgName" BO_ 2564882176 "CM1_00 - Cab Message 1";
BA_ "GenMsgCycleTime" BO_ 2564882176 1000;
BA_ "GenMsgCycleTimeFast" BO_ 2564882176 1000;
BA_ "GenMsgDelayTime" BO_ 2564882176 100;
BA_ "GenMsgSendType" BO_ 2564882176 0;
BA_ "GenMsgStartDelayTime" BO_ 2564882176 151;
BA_ "CI_MsgDefinition" BO_ 2564882179 "J1939DA";
BA_ "CI_MsgId" BO_ 2564882179 3252;
BA_ "CI_MsgName" BO_ 2564882179 "CM1_03 - Cab Message 1";
BA_ "GenMsgCycleTime" BO_ 2564882179 1000;
BA_ "GenMsgCycleTimeFast" BO_ 2564882179 1000;
BA_ "GenMsgDelayTime" BO_ 2564882179 20;
BA_ "GenMsgSendType" BO_ 2564882179 0;
BA_ "GenMsgStartDelayTime" BO_ 2564882179 152;
BA_ "CI_MsgDefinition" BO_ 2564882199 "J1939DA";
BA_ "CI_MsgId" BO_ 2564882199 3256;
BA_ "CI_MsgName" BO_ 2564882199 "CM1_17 - Cab Message 1";
BA_ "GenMsgCycleTime" BO_ 2564882199 1000;
BA_ "GenMsgCycleTimeFast" BO_ 2564882199 1000;
BA_ "GenMsgDelayTime" BO_ 2564882199 100;
BA_ "GenMsgSendType" BO_ 2564882199 0;
BA_ "GenMsgStartDelayTime" BO_ 2564882199 153;
BA_ "CI_MsgDefinition" BO_ 2564882201 "J1939DA";
BA_ "CI_MsgId" BO_ 2564882201 3262;
BA_ "CI_MsgName" BO_ 2564882201 "CM1_19 - Cab Message 1";
BA_ "GenMsgCycleTime" BO_ 2564882201 1000;
BA_ "GenMsgCycleTimeFast" BO_ 2564882201 1000;
BA_ "GenMsgDelayTime" BO_ 2564882201 100;
BA_ "GenMsgSendType" BO_ 2564882201 0;
BA_ "GenMsgStartDelayTime" BO_ 2564882201 154;
BA_ "CI_MsgDefinition" BO_ 2564882209 "J1939DA";
BA_ "CI_MsgId" BO_ 2564882209 3269;
BA_ "CI_MsgName" BO_ 2564882209 "CM1_21 - Cab Message 1";
BA_ "GenMsgCycleTime" BO_ 2564882209 1000;
BA_ "GenMsgCycleTimeFast" BO_ 2564882209 1000;
BA_ "GenMsgDelayTime" BO_ 2564882209 100;
BA_ "GenMsgSendType" BO_ 2564882209 0;
BA_ "GenMsgStartDelayTime" BO_ 2564882209 155;
BA_ "CI_MsgDefinition" BO_ 2564882215 "J1939DA";
BA_ "CI_MsgId" BO_ 2564882215 3314;
BA_ "CI_MsgName" BO_ 2564882215 "CM1_27 - Cab Message 1";
BA_ "GenMsgCycleTime" BO_ 2564882215 1000;
BA_ "GenMsgCycleTimeFast" BO_ 2564882215 1000;
BA_ "GenMsgDelayTime" BO_ 2564882215 100;
BA_ "GenMsgSendType" BO_ 2564882215 0;
BA_ "GenMsgStartDelayTime" BO_ 2564882215 156;
BA_ "CI_MsgDefinition" BO_ 2564882227 "J1939DA";
BA_ "CI_MsgId" BO_ 2564882227 3317;
BA_ "CI_MsgName" BO_ 2564882227 "CM1_33 - Cab Message 1";
BA_ "GenMsgCycleTime" BO_ 2564882227 1000;
BA_ "GenMsgCycleTimeFast" BO_ 2564882227 1000;
BA_ "GenMsgDelayTime" BO_ 2564882227 100;
BA_ "GenMsgSendType" BO_ 2564882227 0;
BA_ "GenMsgStartDelayTime" BO_ 2564882227 157;
BA_ "CI_MsgDefinition" BO_ 2564882241 "J1939DA";
BA_ "CI_MsgId" BO_ 2564882241 3320;
BA_ "CI_MsgName" BO_ 2564882241 "CM1_41 - Cab Message 1";
BA_ "GenMsgCycleTime" BO_ 2564882241 1000;
BA_ "GenMsgCycleTimeFast" BO_ 2564882241 1000;
BA_ "GenMsgDelayTime" BO_ 2564882241 100;
BA_ "GenMsgSendType" BO_ 2564882241 0;
BA_ "GenMsgStartDelayTime" BO_ 2564882241 158;
BA_ "CI_MsgDefinition" BO_ 2564882250 "J1939DA";
BA_ "CI_MsgId" BO_ 2564882250 43033;
BA_ "CI_MsgName" BO_ 2564882250 "CM1_4A - Cab Message 1";
BA_ "GenMsgCycleTime" BO_ 2564882250 1000;
BA_ "GenMsgCycleTimeFast" BO_ 2564882250 1000;
BA_ "GenMsgDelayTime" BO_ 2564882250 100;
BA_ "GenMsgSendType" BO_ 2564882250 0;
BA_ "GenMsgStartDelayTime" BO_ 2564882250 10;
BA_ "CI_MsgDefinition" BO_ 2566811659 "J1939DA";
BA_ "CI_MsgId" BO_ 2566811659 954;
BA_ "CI_MsgName" BO_ 2566811659 "CVW_0B - Combination Vehicle Weight";
BA_ "GenMsgCycleTime" BO_ 2566811659 1000;
BA_ "GenMsgCycleTimeFast" BO_ 2566811659 1000;
BA_ "GenMsgDelayTime" BO_ 2566811659 500;
BA_ "GenMsgSendType" BO_ 2566811659 0;
BA_ "GenMsgStartDelayTime" BO_ 2566811659 181;
BA_ "CI_MsgDefinition" BO_ 2566811687 "J1939DA";
BA_ "CI_MsgId" BO_ 2566811687 39634;
BA_ "CI_MsgName" BO_ 2566811687 "CVW_27 - Combination Vehicle Weight";
BA_ "GenMsgCycleTime" BO_ 2566811687 1000;
BA_ "GenMsgCycleTimeFast" BO_ 2566811687 1000;
BA_ "GenMsgDelayTime" BO_ 2566811687 500;
BA_ "GenMsgSendType" BO_ 2566811687 0;
BA_ "GenMsgStartDelayTime" BO_ 2566811687 182;
BA_ "CI_MsgDefinition" BO_ 2566802967 "J1939DA";
BA_ "CI_MsgId" BO_ 2566802967 6162;
BA_ "CI_MsgName" BO_ 2566802967 "DC1_17 - Door Control 1";
BA_ "GenMsgCycleTime" BO_ 2566802967 1000;
BA_ "GenMsgCycleTimeFast" BO_ 2566802967 1000;
BA_ "GenMsgDelayTime" BO_ 2566802967 100;
BA_ "GenMsgSendType" BO_ 2566802967 0;
BA_ "GenMsgStartDelayTime" BO_ 2566802967 178;
BA_ "CI_MsgDefinition" BO_ 2364609063 "J1939DA";
BA_ "CI_MsgId" BO_ 2364609063 3611;
BA_ "CI_MsgName" BO_ 2364609063 "DCDC1C_27 - DC/DC Converter 1 Control";
BA_ "GenMsgCycleTime" BO_ 2364609063 100;
BA_ "GenMsgCycleTimeFast" BO_ 2364609063 100;
BA_ "GenMsgDelayTime" BO_ 2364609063 50;
BA_ "GenMsgSendType" BO_ 2364609063 0;
BA_ "GenMsgStartDelayTime" BO_ 2364609063 54;
BA_ "CI_MsgDefinition" BO_ 2365315367 "J1939DA";
BA_ "CI_MsgId" BO_ 2365315367 33339;
BA_ "CI_MsgName" BO_ 2365315367 "DCDC1LL_27 - DC/DC Converter 1 Low Side Limits";
BA_ "GenMsgCycleTime" BO_ 2365315367 1000;
BA_ "GenMsgCycleTimeFast" BO_ 2365315367 1000;
BA_ "GenMsgDelayTime" BO_ 2365315367 100;
BA_ "GenMsgSendType" BO_ 2365315367 0;
BA_ "GenMsgStartDelayTime" BO_ 2365315367 145;
BA_ "CI_MsgDefinition" BO_ 2364609306 "J1939DA";
BA_ "CI_MsgId" BO_ 2364609306 3627;
BA_ "CI_MsgName" BO_ 2364609306 "DCDC1OS_1A - DC/DC Converter 1 Operating Status";
BA_ "GenMsgCycleTime" BO_ 2364609306 100;
BA_ "GenMsgCycleTimeFast" BO_ 2364609306 100;
BA_ "GenMsgDelayTime" BO_ 2364609306 50;
BA_ "GenMsgSendType" BO_ 2364609306 0;
BA_ "GenMsgStartDelayTime" BO_ 2364609306 55;
BA_ "CI_MsgDefinition" BO_ 2364610330 "J1939DA";
BA_ "CI_MsgId" BO_ 2364610330 3649;
BA_ "CI_MsgName" BO_ 2364610330 "DCDC1S2_1A - DC/DC Converter 1 Status 2";
BA_ "GenMsgCycleTime" BO_ 2364610330 100;
BA_ "GenMsgCycleTimeFast" BO_ 2364610330 100;
BA_ "GenMsgDelayTime" BO_ 2364610330 50;
BA_ "GenMsgSendType" BO_ 2364610330 0;
BA_ "GenMsgStartDelayTime" BO_ 2364610330 57;
BA_ "CI_MsgDefinition" BO_ 2365315079 "J1939DA";
BA_ "CI_MsgId" BO_ 2365315079 37800;
BA_ "CI_MsgName" BO_ 2365315079 "DCDC1T_07 - DC/DC Converter 1 Temperatures";
BA_ "GenMsgCycleTime" BO_ 2365315079 1000;
BA_ "GenMsgCycleTimeFast" BO_ 2365315079 1000;
BA_ "GenMsgDelayTime" BO_ 2365315079 500;
BA_ "GenMsgSendType" BO_ 2365315079 0;
BA_ "GenMsgStartDelayTime" BO_ 2365315079 142;
BA_ "CI_MsgDefinition" BO_ 2365315098 "J1939DA";
BA_ "CI_MsgId" BO_ 2365315098 35349;
BA_ "CI_MsgName" BO_ 2365315098 "DCDC1T_1A - DC/DC Converter 1 Temperatures";
BA_ "GenMsgCycleTime" BO_ 2365315098 1000;
BA_ "GenMsgCycleTimeFast" BO_ 2365315098 1000;
BA_ "GenMsgDelayTime" BO_ 2365315098 500;
BA_ "GenMsgSendType" BO_ 2365315098 0;
BA_ "GenMsgStartDelayTime" BO_ 2365315098 143;
BA_ "CI_MsgDefinition" BO_ 2365315108 "J1939DA";
BA_ "CI_MsgId" BO_ 2365315108 37802;
BA_ "CI_MsgName" BO_ 2365315108 "DCDC1T_24 - DC/DC Converter 1 Temperatures";
BA_ "GenMsgCycleTime" BO_ 2365315108 1000;
BA_ "GenMsgCycleTimeFast" BO_ 2365315108 1000;
BA_ "GenMsgDelayTime" BO_ 2365315108 500;
BA_ "GenMsgSendType" BO_ 2365315108 0;
BA_ "GenMsgStartDelayTime" BO_ 2365315108 144;
BA_ "CI_MsgDefinition" BO_ 2364609562 "J1939DA";
BA_ "CI_MsgId" BO_ 2364609562 3644;
BA_ "CI_MsgName" BO_ 2364609562 "DCDC1VC_1A - DC/DC Converter 1 Voltage and Current";
BA_ "GenMsgCycleTime" BO_ 2364609562 100;
BA_ "GenMsgCycleTimeFast" BO_ 2364609562 100;
BA_ "GenMsgDelayTime" BO_ 2364609562 50;
BA_ "GenMsgSendType" BO_ 2364609562 0;
BA_ "GenMsgStartDelayTime" BO_ 2364609562 56;
BA_ "CI_MsgDefinition" BO_ 2364610599 "J1939DA";
BA_ "CI_MsgId" BO_ 2364610599 42764;
BA_ "CI_MsgName" BO_ 2364610599 "DCDC2C_27 - DC/DCConverter2Control";
BA_ "GenMsgCycleTime" BO_ 2364610599 100;
BA_ "GenMsgCycleTimeFast" BO_ 2364610599 100;
BA_ "GenMsgDelayTime" BO_ 2364610599 50;
BA_ "GenMsgSendType" BO_ 2364610599 0;
BA_ "GenMsgStartDelayTime" BO_ 2364610599 58;
BA_ "CI_MsgDefinition" BO_ 2365311015 "J1939DA";
BA_ "CI_MsgId" BO_ 2365311015 42769;
BA_ "CI_MsgName" BO_ 2365311015 "DCDC2LL_27 - DC/DCConverter2LowSideLimits";
BA_ "GenMsgCycleTime" BO_ 2365311015 1000;
BA_ "GenMsgCycleTimeFast" BO_ 2365311015 1000;
BA_ "GenMsgDelayTime" BO_ 2365311015 100;
BA_ "GenMsgSendType" BO_ 2365311015 0;
BA_ "GenMsgStartDelayTime" BO_ 2365311015 141;
BA_ "CI_MsgDefinition" BO_ 2364611879 "J1939DA";
BA_ "CI_MsgId" BO_ 2364611879 45700;
BA_ "CI_MsgName" BO_ 2364611879 "DCDC3C_27 - DC/DCConverter3Control";
BA_ "GenMsgCycleTime" BO_ 2364611879 100;
BA_ "GenMsgCycleTimeFast" BO_ 2364611879 100;
BA_ "GenMsgDelayTime" BO_ 2364611879 50;
BA_ "GenMsgSendType" BO_ 2364611879 0;
BA_ "GenMsgStartDelayTime" BO_ 2364611879 59;
BA_ "CI_MsgDefinition" BO_ 2365309479 "J1939DA";
BA_ "CI_MsgId" BO_ 2365309479 45707;
BA_ "CI_MsgName" BO_ 2365309479 "DCDC3LL_27 - DC/DCConverter3LowSideLimits";
BA_ "GenMsgCycleTime" BO_ 2365309479 1000;
BA_ "GenMsgCycleTimeFast" BO_ 2365309479 1000;
BA_ "GenMsgDelayTime" BO_ 2365309479 100;
BA_ "GenMsgSendType" BO_ 2365309479 0;
BA_ "GenMsgStartDelayTime" BO_ 2365309479 139;
BA_ "CI_MsgDefinition" BO_ 2566847488 "J1939DA";
BA_ "CI_MsgId" BO_ 2566847488 5155;
BA_ "CI_MsgName" BO_ 2566847488 "DD1_00 - Dash Display 1";
BA_ "GenMsgCycleTime" BO_ 2566847488 1000;
BA_ "GenMsgCycleTimeFast" BO_ 2566847488 1000;
BA_ "GenMsgDelayTime" BO_ 2566847488 500;
BA_ "GenMsgSendType" BO_ 2566847488 0;
BA_ "GenMsgStartDelayTime" BO_ 2566847488 245;
BA_ "CI_MsgDefinition" BO_ 2566847521 "J1939DA";
BA_ "CI_MsgId" BO_ 2566847521 5167;
BA_ "CI_MsgName" BO_ 2566847521 "DD1_21 - Dash Display 1";
BA_ "GenMsgCycleTime" BO_ 2566847521 1000;
BA_ "GenMsgCycleTimeFast" BO_ 2566847521 1000;
BA_ "GenMsgDelayTime" BO_ 2566847521 500;
BA_ "GenMsgSendType" BO_ 2566847521 0;
BA_ "GenMsgStartDelayTime" BO_ 2566847521 246;
BA_ "CI_MsgDefinition" BO_ 2566810606 "J1939DA";
BA_ "CI_MsgId" BO_ 2566810606 1638;
BA_ "CI_MsgName" BO_ 2566810606 "DI_EE - Driver's Identification";
BA_ "GenMsgCycleTime" BO_ 2566810606 10000;
BA_ "GenMsgCycleTimeFast" BO_ 2566810606 10000;
BA_ "GenMsgDelayTime" BO_ 2566810606 5000;
BA_ "GenMsgSendType" BO_ 2566810606 0;
BA_ "GenMsgStartDelayTime" BO_ 2566810606 343;
BA_ "TpJ1939VarDlc" BO_ 2566810606 1;
BA_ "CI_MsgDefinition" BO_ 2566718743 "J1939DA";
BA_ "CI_MsgId" BO_ 2566718743 2527;
BA_ "CI_MsgName" BO_ 2566718743 "DLCD1_17 - Direct Lamp Control Data 1";
BA_ "GenMsgCycleTime" BO_ 2566718743 1000;
BA_ "GenMsgCycleTimeFast" BO_ 2566718743 1000;
BA_ "GenMsgDelayTime" BO_ 2566718743 500;
BA_ "GenMsgSendType" BO_ 2566718743 0;
BA_ "GenMsgStartDelayTime" BO_ 2566718743 163;
BA_ "CI_MsgDefinition" BO_ 2566834688 "J1939-73";
BA_ "CI_MsgId" BO_ 2566834688 11638;
BA_ "CI_MsgName" BO_ 2566834688 "DM01_00 - Active Diagnostic Trouble Codes";
BA_ "GenMsgCycleTime" BO_ 2566834688 1000;
BA_ "GenMsgCycleTimeFast" BO_ 2566834688 1000;
BA_ "GenMsgDelayTime" BO_ 2566834688 100;
BA_ "GenMsgSendType" BO_ 2566834688 0;
BA_ "GenMsgStartDelayTime" BO_ 2566834688 186;
BA_ "TpJ1939VarDlc" BO_ 2566834688 1;
BA_ "CI_MsgDefinition" BO_ 2566834691 "J1939-73";
BA_ "CI_MsgId" BO_ 2566834691 11748;
BA_ "CI_MsgName" BO_ 2566834691 "DM01_03 - Active Diagnostic Trouble Codes";
BA_ "GenMsgCycleTime" BO_ 2566834691 1000;
BA_ "GenMsgCycleTimeFast" BO_ 2566834691 1000;
BA_ "GenMsgDelayTime" BO_ 2566834691 100;
BA_ "GenMsgSendType" BO_ 2566834691 0;
BA_ "GenMsgStartDelayTime" BO_ 2566834691 187;
BA_ "TpJ1939VarDlc" BO_ 2566834691 1;
BA_ "CI_MsgDefinition" BO_ 2566834693 "J1939-73";
BA_ "CI_MsgId" BO_ 2566834693 40728;
BA_ "CI_MsgName" BO_ 2566834693 "DM01_05 - Active Diagnostic Trouble Codes";
BA_ "GenMsgCycleTime" BO_ 2566834693 1000;
BA_ "GenMsgCycleTimeFast" BO_ 2566834693 1000;
BA_ "GenMsgDelayTime" BO_ 2566834693 100;
BA_ "GenMsgSendType" BO_ 2566834693 0;
BA_ "GenMsgStartDelayTime" BO_ 2566834693 188;
BA_ "TpJ1939VarDlc" BO_ 2566834693 1;
BA_ "CI_MsgDefinition" BO_ 2566834695 "J1939-73";
BA_ "CI_MsgId" BO_ 2566834695 37870;
BA_ "CI_MsgName" BO_ 2566834695 "DM01_07 - Active Diagnostic Trouble Codes";
BA_ "GenMsgCycleTime" BO_ 2566834695 1000;
BA_ "GenMsgCycleTimeFast" BO_ 2566834695 1000;
BA_ "GenMsgDelayTime" BO_ 2566834695 100;
BA_ "GenMsgSendType" BO_ 2566834695 0;
BA_ "GenMsgStartDelayTime" BO_ 2566834695 189;
BA_ "TpJ1939VarDlc" BO_ 2566834695 1;
BA_ "CI_MsgDefinition" BO_ 2566834699 "J1939-73";
BA_ "CI_MsgId" BO_ 2566834699 12032;
BA_ "CI_MsgName" BO_ 2566834699 "DM01_0B - Active Diagnostic Trouble Codes";
BA_ "GenMsgCycleTime" BO_ 2566834699 1000;
BA_ "GenMsgCycleTimeFast" BO_ 2566834699 1000;
BA_ "GenMsgDelayTime" BO_ 2566834699 100;
BA_ "GenMsgSendType" BO_ 2566834699 0;
BA_ "GenMsgStartDelayTime" BO_ 2566834699 191;
BA_ "TpJ1939VarDlc" BO_ 2566834699 1;
BA_ "CI_MsgDefinition" BO_ 2566834704 "J1939-73";
BA_ "CI_MsgId" BO_ 2566834704 12143;
BA_ "CI_MsgName" BO_ 2566834704 "DM01_10 - Active Diagnostic Trouble Codes";
BA_ "GenMsgCycleTime" BO_ 2566834704 1000;
BA_ "GenMsgCycleTimeFast" BO_ 2566834704 1000;
BA_ "GenMsgDelayTime" BO_ 2566834704 100;
BA_ "GenMsgSendType" BO_ 2566834704 0;
BA_ "GenMsgStartDelayTime" BO_ 2566834704 192;
BA_ "TpJ1939VarDlc" BO_ 2566834704 1;
BA_ "CI_MsgDefinition" BO_ 2566834707 "J1939-73";
BA_ "CI_MsgId" BO_ 2566834707 12202;
BA_ "CI_MsgName" BO_ 2566834707 "DM01_13 - Active Diagnostic Trouble Codes";
BA_ "GenMsgCycleTime" BO_ 2566834707 1000;
BA_ "GenMsgCycleTimeFast" BO_ 2566834707 1000;
BA_ "GenMsgDelayTime" BO_ 2566834707 100;
BA_ "GenMsgSendType" BO_ 2566834707 0;
BA_ "GenMsgStartDelayTime" BO_ 2566834707 193;
BA_ "TpJ1939VarDlc" BO_ 2566834707 1;
BA_ "CI_MsgDefinition" BO_ 2566834711 "J1939-73";
BA_ "CI_MsgId" BO_ 2566834711 12257;
BA_ "CI_MsgName" BO_ 2566834711 "DM01_17 - Active Diagnostic Trouble Codes";
BA_ "GenMsgCycleTime" BO_ 2566834711 1000;
BA_ "GenMsgCycleTimeFast" BO_ 2566834711 1000;
BA_ "GenMsgDelayTime" BO_ 2566834711 100;
BA_ "GenMsgSendType" BO_ 2566834711 0;
BA_ "GenMsgStartDelayTime" BO_ 2566834711 194;
BA_ "TpJ1939VarDlc" BO_ 2566834711 1;
BA_ "CI_MsgDefinition" BO_ 2566834713 "J1939-73";
BA_ "CI_MsgId" BO_ 2566834713 12362;
BA_ "CI_MsgName" BO_ 2566834713 "DM01_19 - Active Diagnostic Trouble Codes";
BA_ "GenMsgCycleTime" BO_ 2566834713 1000;
BA_ "GenMsgCycleTimeFast" BO_ 2566834713 1000;
BA_ "GenMsgDelayTime" BO_ 2566834713 100;
BA_ "GenMsgSendType" BO_ 2566834713 0;
BA_ "GenMsgStartDelayTime" BO_ 2566834713 195;
BA_ "TpJ1939VarDlc" BO_ 2566834713 1;
BA_ "CI_MsgDefinition" BO_ 2566834714 "J1939-73";
BA_ "CI_MsgId" BO_ 2566834714 33792;
BA_ "CI_MsgName" BO_ 2566834714 "DM01_1A - Active Diagnostic Trouble Codes";
BA_ "GenMsgCycleTime" BO_ 2566834714 1000;
BA_ "GenMsgCycleTimeFast" BO_ 2566834714 1000;
BA_ "GenMsgDelayTime" BO_ 2566834714 100;
BA_ "GenMsgSendType" BO_ 2566834714 0;
BA_ "GenMsgStartDelayTime" BO_ 2566834714 196;
BA_ "TpJ1939VarDlc" BO_ 2566834714 1;
BA_ "CI_MsgDefinition" BO_ 2566834717 "J1939-73";
BA_ "CI_MsgId" BO_ 2566834717 12472;
BA_ "CI_MsgName" BO_ 2566834717 "DM01_1D - Active Diagnostic Trouble Codes";
BA_ "GenMsgCycleTime" BO_ 2566834717 1000;
BA_ "GenMsgCycleTimeFast" BO_ 2566834717 1000;
BA_ "GenMsgDelayTime" BO_ 2566834717 100;
BA_ "GenMsgSendType" BO_ 2566834717 0;
BA_ "GenMsgStartDelayTime" BO_ 2566834717 197;
BA_ "TpJ1939VarDlc" BO_ 2566834717 1;
BA_ "CI_MsgDefinition" BO_ 2566834721 "J1939-73";
BA_ "CI_MsgId" BO_ 2566834721 12527;
BA_ "CI_MsgName" BO_ 2566834721 "DM01_21 - Active Diagnostic Trouble Codes";
BA_ "GenMsgCycleTime" BO_ 2566834721 1000;
BA_ "GenMsgCycleTimeFast" BO_ 2566834721 1000;
BA_ "GenMsgDelayTime" BO_ 2566834721 100;
BA_ "GenMsgSendType" BO_ 2566834721 0;
BA_ "GenMsgStartDelayTime" BO_ 2566834721 198;
BA_ "TpJ1939VarDlc" BO_ 2566834721 1;
BA_ "CI_MsgDefinition" BO_ 2566834724 "J1939-73";
BA_ "CI_MsgId" BO_ 2566834724 37925;
BA_ "CI_MsgName" BO_ 2566834724 "DM01_24 - Active Diagnostic Trouble Codes";
BA_ "GenMsgCycleTime" BO_ 2566834724 1000;
BA_ "GenMsgCycleTimeFast" BO_ 2566834724 1000;
BA_ "GenMsgDelayTime" BO_ 2566834724 100;
BA_ "GenMsgSendType" BO_ 2566834724 0;
BA_ "GenMsgStartDelayTime" BO_ 2566834724 199;
BA_ "TpJ1939VarDlc" BO_ 2566834724 1;
BA_ "CI_MsgDefinition" BO_ 2566834727 "J1939-73";
BA_ "CI_MsgId" BO_ 2566834727 12638;
BA_ "CI_MsgName" BO_ 2566834727 "DM01_27 - Active Diagnostic Trouble Codes";
BA_ "GenMsgCycleTime" BO_ 2566834727 1000;
BA_ "GenMsgCycleTimeFast" BO_ 2566834727 1000;
BA_ "GenMsgDelayTime" BO_ 2566834727 100;
BA_ "GenMsgSendType" BO_ 2566834727 0;
BA_ "GenMsgStartDelayTime" BO_ 2566834727 201;
BA_ "TpJ1939VarDlc" BO_ 2566834727 1;
BA_ "CI_MsgDefinition" BO_ 2566834730 "J1939-73";
BA_ "CI_MsgId" BO_ 2566834730 12748;
BA_ "CI_MsgName" BO_ 2566834730 "DM01_2A - Active Diagnostic Trouble Codes";
BA_ "GenMsgCycleTime" BO_ 2566834730 1000;
BA_ "GenMsgCycleTimeFast" BO_ 2566834730 1000;
BA_ "GenMsgDelayTime" BO_ 2566834730 100;
BA_ "GenMsgSendType" BO_ 2566834730 0;
BA_ "GenMsgStartDelayTime" BO_ 2566834730 202;
BA_ "TpJ1939VarDlc" BO_ 2566834730 1;
BA_ "CI_MsgDefinition" BO_ 2566834735 "J1939-73";
BA_ "CI_MsgId" BO_ 2566834735 12693;
BA_ "CI_MsgName" BO_ 2566834735 "DM01_2F - Active Diagnostic Trouble Codes";
BA_ "GenMsgCycleTime" BO_ 2566834735 1000;
BA_ "GenMsgCycleTimeFast" BO_ 2566834735 1000;
BA_ "GenMsgDelayTime" BO_ 2566834735 100;
BA_ "GenMsgSendType" BO_ 2566834735 0;
BA_ "GenMsgStartDelayTime" BO_ 2566834735 203;
BA_ "TpJ1939VarDlc" BO_ 2566834735 1;
BA_ "CI_MsgDefinition" BO_ 2566834736 "J1939-73";
BA_ "CI_MsgId" BO_ 2566834736 34828;
BA_ "CI_MsgName" BO_ 2566834736 "DM01_30 - Active Diagnostic Trouble Codes";
BA_ "GenMsgCycleTime" BO_ 2566834736 1000;
BA_ "GenMsgCycleTimeFast" BO_ 2566834736 1000;
BA_ "GenMsgDelayTime" BO_ 2566834736 100;
BA_ "GenMsgSendType" BO_ 2566834736 0;
BA_ "GenMsgStartDelayTime" BO_ 2566834736 204;
BA_ "TpJ1939VarDlc" BO_ 2566834736 1;
BA_ "CI_MsgDefinition" BO_ 2566834739 "J1939-73";
BA_ "CI_MsgId" BO_ 2566834739 12969;
BA_ "CI_MsgName" BO_ 2566834739 "DM01_33 - Active Diagnostic Trouble Codes";
BA_ "GenMsgCycleTime" BO_ 2566834739 1000;
BA_ "GenMsgCycleTimeFast" BO_ 2566834739 1000;
BA_ "GenMsgDelayTime" BO_ 2566834739 100;
BA_ "GenMsgSendType" BO_ 2566834739 0;
BA_ "GenMsgStartDelayTime" BO_ 2566834739 205;
BA_ "TpJ1939VarDlc" BO_ 2566834739 1;
BA_ "CI_MsgDefinition" BO_ 2566834753 "J1939-73";
BA_ "CI_MsgId" BO_ 2566834753 13110;
BA_ "CI_MsgName" BO_ 2566834753 "DM01_41 - Active Diagnostic Trouble Codes";
BA_ "GenMsgCycleTime" BO_ 2566834753 1000;
BA_ "GenMsgCycleTimeFast" BO_ 2566834753 1000;
BA_ "GenMsgDelayTime" BO_ 2566834753 100;
BA_ "GenMsgSendType" BO_ 2566834753 0;
BA_ "GenMsgStartDelayTime" BO_ 2566834753 206;
BA_ "TpJ1939VarDlc" BO_ 2566834753 1;
BA_ "CI_MsgDefinition" BO_ 2566834761 "J1939-73";
BA_ "CI_MsgId" BO_ 2566834761 33847;
BA_ "CI_MsgName" BO_ 2566834761 "DM01_49 - Active Diagnostic Trouble Codes";
BA_ "GenMsgCycleTime" BO_ 2566834761 1000;
BA_ "GenMsgCycleTimeFast" BO_ 2566834761 1000;
BA_ "GenMsgDelayTime" BO_ 2566834761 100;
BA_ "GenMsgSendType" BO_ 2566834761 0;
BA_ "GenMsgStartDelayTime" BO_ 2566834761 207;
BA_ "TpJ1939VarDlc" BO_ 2566834761 1;
BA_ "CI_MsgDefinition" BO_ 2566834762 "J1939-73";
BA_ "CI_MsgId" BO_ 2566834762 13440;
BA_ "CI_MsgName" BO_ 2566834762 "DM01_4A - Active Diagnostic Trouble Codes";
BA_ "GenMsgCycleTime" BO_ 2566834762 1000;
BA_ "GenMsgCycleTimeFast" BO_ 2566834762 1000;
BA_ "GenMsgDelayTime" BO_ 2566834762 100;
BA_ "GenMsgSendType" BO_ 2566834762 0;
BA_ "GenMsgStartDelayTime" BO_ 2566834762 12;
BA_ "TpJ1939VarDlc" BO_ 2566834762 1;
BA_ "CI_MsgDefinition" BO_ 2566834765 "J1939-73";
BA_ "CI_MsgId" BO_ 2566834765 36898;
BA_ "CI_MsgName" BO_ 2566834765 "DM01_4D - Active Diagnostic Trouble Codes";
BA_ "GenMsgCycleTime" BO_ 2566834765 1000;
BA_ "GenMsgCycleTimeFast" BO_ 2566834765 1000;
BA_ "GenMsgDelayTime" BO_ 2566834765 100;
BA_ "GenMsgSendType" BO_ 2566834765 0;
BA_ "GenMsgStartDelayTime" BO_ 2566834765 208;
BA_ "TpJ1939VarDlc" BO_ 2566834765 1;
BA_ "CI_MsgDefinition" BO_ 2566834771 "J1939-73";
BA_ "CI_MsgId" BO_ 2566834771 13771;
BA_ "CI_MsgName" BO_ 2566834771 "DM01_53 - Active Diagnostic Trouble Codes";
BA_ "GenMsgCycleTime" BO_ 2566834771 1000;
BA_ "GenMsgCycleTimeFast" BO_ 2566834771 1000;
BA_ "GenMsgDelayTime" BO_ 2566834771 100;
BA_ "GenMsgSendType" BO_ 2566834771 0;
BA_ "GenMsgStartDelayTime" BO_ 2566834771 209;
BA_ "TpJ1939VarDlc" BO_ 2566834771 1;
BA_ "CI_MsgDefinition" BO_ 2566834802 "J1939-73";
BA_ "CI_MsgId" BO_ 2566834802 14001;
BA_ "CI_MsgName" BO_ 2566834802 "DM01_72 - Active Diagnostic Trouble Codes";
BA_ "GenMsgCycleTime" BO_ 2566834802 1000;
BA_ "GenMsgCycleTimeFast" BO_ 2566834802 1000;
BA_ "GenMsgDelayTime" BO_ 2566834802 100;
BA_ "GenMsgSendType" BO_ 2566834802 0;
BA_ "GenMsgStartDelayTime" BO_ 2566834802 211;
BA_ "TpJ1939VarDlc" BO_ 2566834802 1;
BA_ "CI_MsgDefinition" BO_ 2566834808 "J1939-73";
BA_ "CI_MsgId" BO_ 2566834808 39872;
BA_ "CI_MsgName" BO_ 2566834808 "DM01_78 - Active Diagnostic Trouble Codes";
BA_ "GenMsgCycleTime" BO_ 2566834808 1000;
BA_ "GenMsgCycleTimeFast" BO_ 2566834808 1000;
BA_ "GenMsgDelayTime" BO_ 2566834808 100;
BA_ "GenMsgSendType" BO_ 2566834808 0;
BA_ "GenMsgStartDelayTime" BO_ 2566834808 212;
BA_ "TpJ1939VarDlc" BO_ 2566834808 1;
BA_ "CI_MsgDefinition" BO_ 2566834812 "J1939-73";
BA_ "CI_MsgId" BO_ 2566834812 36483;
BA_ "CI_MsgName" BO_ 2566834812 "DM01_7C - Active Diagnostic Trouble Codes";
BA_ "GenMsgCycleTime" BO_ 2566834812 1000;
BA_ "GenMsgCycleTimeFast" BO_ 2566834812 1000;
BA_ "GenMsgDelayTime" BO_ 2566834812 100;
BA_ "GenMsgSendType" BO_ 2566834812 0;
BA_ "GenMsgStartDelayTime" BO_ 2566834812 213;
BA_ "TpJ1939VarDlc" BO_ 2566834812 1;
BA_ "CI_MsgDefinition" BO_ 2566834817 "J1939-73";
BA_ "CI_MsgId" BO_ 2566834817 36088;
BA_ "CI_MsgName" BO_ 2566834817 "DM01_81 - Active Diagnostic Trouble Codes";
BA_ "GenMsgCycleTime" BO_ 2566834817 1000;
BA_ "GenMsgCycleTimeFast" BO_ 2566834817 1000;
BA_ "GenMsgDelayTime" BO_ 2566834817 100;
BA_ "GenMsgSendType" BO_ 2566834817 0;
BA_ "GenMsgStartDelayTime" BO_ 2566834817 214;
BA_ "TpJ1939VarDlc" BO_ 2566834817 1;
BA_ "CI_MsgDefinition" BO_ 2566834844 "J1939-73";
BA_ "CI_MsgId" BO_ 2566834844 42840;
BA_ "CI_MsgName" BO_ 2566834844 "DM01_9C - Active Diagnostic Trouble Codes";
BA_ "GenMsgCycleTime" BO_ 2566834844 1000;
BA_ "GenMsgCycleTimeFast" BO_ 2566834844 1000;
BA_ "GenMsgDelayTime" BO_ 2566834844 100;
BA_ "GenMsgSendType" BO_ 2566834844 0;
BA_ "GenMsgStartDelayTime" BO_ 2566834844 215;
BA_ "TpJ1939VarDlc" BO_ 2566834844 1;
BA_ "CI_MsgDefinition" BO_ 2566834846 "J1939-73";
BA_ "CI_MsgId" BO_ 2566834846 42895;
BA_ "CI_MsgName" BO_ 2566834846 "DM01_9E - Active Diagnostic Trouble Codes";
BA_ "GenMsgCycleTime" BO_ 2566834846 1000;
BA_ "GenMsgCycleTimeFast" BO_ 2566834846 1000;
BA_ "GenMsgDelayTime" BO_ 2566834846 100;
BA_ "GenMsgSendType" BO_ 2566834846 0;
BA_ "GenMsgStartDelayTime" BO_ 2566834846 216;
BA_ "TpJ1939VarDlc" BO_ 2566834846 1;
BA_ "CI_MsgDefinition" BO_ 2566834847 "J1939-73";
BA_ "CI_MsgId" BO_ 2566834847 14182;
BA_ "CI_MsgName" BO_ 2566834847 "DM01_9F - Active Diagnostic Trouble Codes";
BA_ "GenMsgCycleTime" BO_ 2566834847 1000;
BA_ "GenMsgCycleTimeFast" BO_ 2566834847 1000;
BA_ "GenMsgDelayTime" BO_ 2566834847 100;
BA_ "GenMsgSendType" BO_ 2566834847 0;
BA_ "GenMsgStartDelayTime" BO_ 2566834847 217;
BA_ "TpJ1939VarDlc" BO_ 2566834847 1;
BA_ "CI_MsgDefinition" BO_ 2566834848 "J1939-73";
BA_ "CI_MsgId" BO_ 2566834848 14237;
BA_ "CI_MsgName" BO_ 2566834848 "DM01_A0 - Active Diagnostic Trouble Codes";
BA_ "GenMsgCycleTime" BO_ 2566834848 1000;
BA_ "GenMsgCycleTimeFast" BO_ 2566834848 1000;
BA_ "GenMsgDelayTime" BO_ 2566834848 100;
BA_ "GenMsgSendType" BO_ 2566834848 0;
BA_ "GenMsgStartDelayTime" BO_ 2566834848 218;
BA_ "TpJ1939VarDlc" BO_ 2566834848 1;
BA_ "CI_MsgDefinition" BO_ 2566834889 "J1939-73";
BA_ "CI_MsgId" BO_ 2566834889 41838;
BA_ "CI_MsgName" BO_ 2566834889 "DM01_C9 - Active Diagnostic Trouble Codes";
BA_ "GenMsgCycleTime" BO_ 2566834889 1000;
BA_ "GenMsgCycleTimeFast" BO_ 2566834889 1000;
BA_ "GenMsgDelayTime" BO_ 2566834889 100;
BA_ "GenMsgSendType" BO_ 2566834889 0;
BA_ "GenMsgStartDelayTime" BO_ 2566834889 219;
BA_ "TpJ1939VarDlc" BO_ 2566834889 1;
BA_ "CI_MsgDefinition" BO_ 2566834917 "J1939-73";
BA_ "CI_MsgId" BO_ 2566834917 14402;
BA_ "CI_MsgName" BO_ 2566834917 "DM01_E5 - Active Diagnostic Trouble Codes";
BA_ "GenMsgCycleTime" BO_ 2566834917 1000;
BA_ "GenMsgCycleTimeFast" BO_ 2566834917 1000;
BA_ "GenMsgDelayTime" BO_ 2566834917 100;
BA_ "GenMsgSendType" BO_ 2566834917 0;
BA_ "GenMsgStartDelayTime" BO_ 2566834917 221;
BA_ "TpJ1939VarDlc" BO_ 2566834917 1;
BA_ "CI_MsgDefinition" BO_ 2566834926 "J1939-73";
BA_ "CI_MsgId" BO_ 2566834926 14633;
BA_ "CI_MsgName" BO_ 2566834926 "DM01_EE - Active Diagnostic Trouble Codes";
BA_ "GenMsgCycleTime" BO_ 2566834926 1000;
BA_ "GenMsgCycleTimeFast" BO_ 2566834926 1000;
BA_ "GenMsgDelayTime" BO_ 2566834926 100;
BA_ "GenMsgSendType" BO_ 2566834926 0;
BA_ "GenMsgStartDelayTime" BO_ 2566834926 222;
BA_ "TpJ1939VarDlc" BO_ 2566834926 1;
BA_ "CI_MsgDefinition" BO_ 2566834927 "J1939-73";
BA_ "CI_MsgId" BO_ 2566834927 14689;
BA_ "CI_MsgName" BO_ 2566834927 "DM01_EF - Active Diagnostic Trouble Codes";
BA_ "GenMsgCycleTime" BO_ 2566834927 1000;
BA_ "GenMsgCycleTimeFast" BO_ 2566834927 1000;
BA_ "GenMsgDelayTime" BO_ 2566834927 100;
BA_ "GenMsgSendType" BO_ 2566834927 0;
BA_ "GenMsgStartDelayTime" BO_ 2566834927 223;
BA_ "TpJ1939VarDlc" BO_ 2566834927 1;
BA_ "CI_MsgDefinition" BO_ 2566834930 "J1939-73";
BA_ "CI_MsgId" BO_ 2566834930 38737;
BA_ "CI_MsgName" BO_ 2566834930 "DM01_F2 - Active Diagnostic Trouble Codes";
BA_ "GenMsgCycleTime" BO_ 2566834930 1000;
BA_ "GenMsgCycleTimeFast" BO_ 2566834930 1000;
BA_ "GenMsgDelayTime" BO_ 2566834930 100;
BA_ "GenMsgSendType" BO_ 2566834930 0;
BA_ "GenMsgStartDelayTime" BO_ 2566834930 224;
BA_ "TpJ1939VarDlc" BO_ 2566834930 1;
BA_ "CI_MsgDefinition" BO_ 2566834931 "J1939-73";
BA_ "CI_MsgId" BO_ 2566834931 14744;
BA_ "CI_MsgName" BO_ 2566834931 "DM01_F3 - Active Diagnostic Trouble Codes";
BA_ "GenMsgCycleTime" BO_ 2566834931 1000;
BA_ "GenMsgCycleTimeFast" BO_ 2566834931 1000;
BA_ "GenMsgDelayTime" BO_ 2566834931 100;
BA_ "GenMsgSendType" BO_ 2566834931 0;
BA_ "GenMsgStartDelayTime" BO_ 2566834931 225;
BA_ "TpJ1939VarDlc" BO_ 2566834931 1;
BA_ "CI_MsgDefinition" BO_ 2566834947 "J1939-73";
BA_ "CI_MsgId" BO_ 2566834947 15176;
BA_ "CI_MsgName" BO_ 2566834947 "DM02_03 - Previously Active Diagnostic Trouble Codes";
BA_ "TpJ1939VarDlc" BO_ 2566834947 1;
BA_ "CI_MsgDefinition" BO_ 2566834949 "J1939-73";
BA_ "CI_MsgId" BO_ 2566834949 40784;
BA_ "CI_MsgName" BO_ 2566834949 "DM02_05 - Previously Active Diagnostic Trouble Codes";
BA_ "TpJ1939VarDlc" BO_ 2566834949 1;
BA_ "CI_MsgDefinition" BO_ 2566834951 "J1939-73";
BA_ "CI_MsgId" BO_ 2566834951 37980;
BA_ "CI_MsgName" BO_ 2566834951 "DM02_07 - Previously Active Diagnostic Trouble Codes";
BA_ "TpJ1939VarDlc" BO_ 2566834951 1;
BA_ "CI_MsgDefinition" BO_ 2566834970 "J1939-73";
BA_ "CI_MsgId" BO_ 2566834970 33902;
BA_ "CI_MsgName" BO_ 2566834970 "DM02_1A - Previously Active Diagnostic Trouble Codes";
BA_ "TpJ1939VarDlc" BO_ 2566834970 1;
BA_ "CI_MsgDefinition" BO_ 2566834973 "J1939-73";
BA_ "CI_MsgId" BO_ 2566834973 15844;
BA_ "CI_MsgName" BO_ 2566834973 "DM02_1D - Previously Active Diagnostic Trouble Codes";
BA_ "TpJ1939VarDlc" BO_ 2566834973 1;
BA_ "CI_MsgDefinition" BO_ 2566834980 "J1939-73";
BA_ "CI_MsgId" BO_ 2566834980 38035;
BA_ "CI_MsgName" BO_ 2566834980 "DM02_24 - Previously Active Diagnostic Trouble Codes";
BA_ "TpJ1939VarDlc" BO_ 2566834980 1;
BA_ "CI_MsgDefinition" BO_ 2566834991 "J1939-73";
BA_ "CI_MsgId" BO_ 2566834991 15954;
BA_ "CI_MsgName" BO_ 2566834991 "DM02_2F - Previously Active Diagnostic Trouble Codes";
BA_ "TpJ1939VarDlc" BO_ 2566834991 1;
BA_ "CI_MsgDefinition" BO_ 2566834992 "J1939-73";
BA_ "CI_MsgId" BO_ 2566834992 39839;
BA_ "CI_MsgName" BO_ 2566834992 "DM02_30 - Previously Active Diagnostic Trouble Codes";
BA_ "GenMsgDelayTime" BO_ 2566834992 10;
BA_ "TpJ1939VarDlc" BO_ 2566834992 1;
BA_ "CI_MsgDefinition" BO_ 2566834995 "J1939-73";
BA_ "CI_MsgId" BO_ 2566834995 16064;
BA_ "CI_MsgName" BO_ 2566834995 "DM02_33 - Previously Active Diagnostic Trouble Codes";
BA_ "TpJ1939VarDlc" BO_ 2566834995 1;
BA_ "CI_MsgDefinition" BO_ 2566835017 "J1939-73";
BA_ "CI_MsgId" BO_ 2566835017 33957;
BA_ "CI_MsgName" BO_ 2566835017 "DM02_49 - Previously Active Diagnostic Trouble Codes";
BA_ "TpJ1939VarDlc" BO_ 2566835017 1;
BA_ "CI_MsgDefinition" BO_ 2566835018 "J1939-73";
BA_ "CI_MsgId" BO_ 2566835018 16339;
BA_ "CI_MsgName" BO_ 2566835018 "DM02_4A - Previously Active Diagnostic Trouble Codes";
BA_ "TpJ1939VarDlc" BO_ 2566835018 1;
BA_ "CI_MsgDefinition" BO_ 2566835021 "J1939-73";
BA_ "CI_MsgId" BO_ 2566835021 36953;
BA_ "CI_MsgName" BO_ 2566835021 "DM02_4D - Previously Active Diagnostic Trouble Codes";
BA_ "TpJ1939VarDlc" BO_ 2566835021 1;
BA_ "CI_MsgDefinition" BO_ 2566835058 "J1939-73";
BA_ "CI_MsgId" BO_ 2566835058 16504;
BA_ "CI_MsgName" BO_ 2566835058 "DM02_72 - Previously Active Diagnostic Trouble Codes";
BA_ "TpJ1939VarDlc" BO_ 2566835058 1;
BA_ "CI_MsgDefinition" BO_ 2566835068 "J1939-73";
BA_ "CI_MsgId" BO_ 2566835068 36538;
BA_ "CI_MsgName" BO_ 2566835068 "DM02_7C - Previously Active Diagnostic Trouble Codes";
BA_ "TpJ1939VarDlc" BO_ 2566835068 1;
BA_ "CI_MsgDefinition" BO_ 2566835183 "J1939-73";
BA_ "CI_MsgId" BO_ 2566835183 34528;
BA_ "CI_MsgName" BO_ 2566835183 "DM02_EF - Previously Active Diagnostic Trouble Codes";
BA_ "TpJ1939VarDlc" BO_ 2566835183 1;
BA_ "CI_MsgDefinition" BO_ 2566835186 "J1939-73";
BA_ "CI_MsgId" BO_ 2566835186 38792;
BA_ "CI_MsgName" BO_ 2566835186 "DM02_F2 - Previously Active Diagnostic Trouble Codes";
BA_ "TpJ1939VarDlc" BO_ 2566835186 1;
BA_ "CI_MsgDefinition" BO_ 2566835187 "J1939-73";
BA_ "CI_MsgId" BO_ 2566835187 32751;
BA_ "CI_MsgName" BO_ 2566835187 "DM02_F3 - Previously Active Diagnostic Trouble Codes";
BA_ "TpJ1939VarDlc" BO_ 2566835187 1;
BA_ "CI_MsgDefinition" BO_ 2566835459 "Iveco Proprietary";
BA_ "CI_MsgId" BO_ 2566835459 18002;
BA_ "CI_MsgName" BO_ 2566835459 "DM04_03 - Freeze Frame Parameters";
BA_ "TpJ1939VarDlc" BO_ 2566835459 1;
BA_ "CI_MsgDefinition" BO_ 2566835461 "Iveco Proprietary";
BA_ "CI_MsgId" BO_ 2566835461 40839;
BA_ "CI_MsgName" BO_ 2566835461 "DM04_05 - Freeze Frame Parameters";
BA_ "TpJ1939VarDlc" BO_ 2566835461 1;
BA_ "CI_MsgDefinition" BO_ 2566835463 "Iveco Proprietary";
BA_ "CI_MsgId" BO_ 2566835463 38092;
BA_ "CI_MsgName" BO_ 2566835463 "DM04_07 - Freeze Frame Parameters";
BA_ "TpJ1939VarDlc" BO_ 2566835463 1;
BA_ "CI_MsgDefinition" BO_ 2566835482 "Iveco Proprietary";
BA_ "CI_MsgId" BO_ 2566835482 34012;
BA_ "CI_MsgName" BO_ 2566835482 "DM04_1A - Freeze Frame Parameters";
BA_ "TpJ1939VarDlc" BO_ 2566835482 1;
BA_ "CI_MsgDefinition" BO_ 2566835485 "Iveco Proprietary";
BA_ "CI_MsgId" BO_ 2566835485 19439;
BA_ "CI_MsgName" BO_ 2566835485 "DM04_1D - Freeze Frame Parameters";
BA_ "TpJ1939VarDlc" BO_ 2566835485 1;
BA_ "CI_MsgDefinition" BO_ 2566835492 "Iveco Proprietary";
BA_ "CI_MsgId" BO_ 2566835492 38293;
BA_ "CI_MsgName" BO_ 2566835492 "DM04_24 - Freeze Frame Parameters";
BA_ "TpJ1939VarDlc" BO_ 2566835492 1;
BA_ "CI_MsgDefinition" BO_ 2566835503 "Iveco Proprietary";
BA_ "CI_MsgId" BO_ 2566835503 33138;
BA_ "CI_MsgName" BO_ 2566835503 "DM04_2F - Freeze Frame Parameters";
BA_ "TpJ1939VarDlc" BO_ 2566835503 1;
BA_ "CI_MsgDefinition" BO_ 2566835504 "Iveco Proprietary";
BA_ "CI_MsgId" BO_ 2566835504 39841;
BA_ "CI_MsgName" BO_ 2566835504 "DM04_30 - Freeze Frame Parameters";
BA_ "GenMsgDelayTime" BO_ 2566835504 10;
BA_ "TpJ1939VarDlc" BO_ 2566835504 1;
BA_ "CI_MsgDefinition" BO_ 2566835529 "Iveco Proprietary";
BA_ "CI_MsgId" BO_ 2566835529 34213;
BA_ "CI_MsgName" BO_ 2566835529 "DM04_49 - Freeze Frame Parameters";
BA_ "TpJ1939VarDlc" BO_ 2566835529 1;
BA_ "CI_MsgDefinition" BO_ 2566835530 "Iveco Proprietary";
BA_ "CI_MsgId" BO_ 2566835530 20888;
BA_ "CI_MsgName" BO_ 2566835530 "DM04_4A - Freeze Frame Parameters";
BA_ "TpJ1939VarDlc" BO_ 2566835530 1;
BA_ "CI_MsgDefinition" BO_ 2566835533 "Iveco Proprietary";
BA_ "CI_MsgId" BO_ 2566835533 37009;
BA_ "CI_MsgName" BO_ 2566835533 "DM04_4D - Freeze Frame Parameters";
BA_ "TpJ1939VarDlc" BO_ 2566835533 1;
BA_ "CI_MsgDefinition" BO_ 2566835539 "Iveco Proprietary";
BA_ "CI_MsgId" BO_ 2566835539 21491;
BA_ "CI_MsgName" BO_ 2566835539 "DM04_53 - Freeze Frame Parameters";
BA_ "TpJ1939VarDlc" BO_ 2566835539 1;
BA_ "CI_MsgDefinition" BO_ 2566835576 "Iveco Proprietary";
BA_ "CI_MsgId" BO_ 2566835576 39982;
BA_ "CI_MsgName" BO_ 2566835576 "DM04_78 - Freeze Frame Parameters";
BA_ "TpJ1939VarDlc" BO_ 2566835576 1;
BA_ "CI_MsgDefinition" BO_ 2566835580 "Iveco Proprietary";
BA_ "CI_MsgId" BO_ 2566835580 36594;
BA_ "CI_MsgName" BO_ 2566835580 "DM04_7C - Freeze Frame Parameters";
BA_ "TpJ1939VarDlc" BO_ 2566835580 1;
BA_ "CI_MsgDefinition" BO_ 2566835657 "Iveco Proprietary";
BA_ "CI_MsgId" BO_ 2566835657 44899;
BA_ "CI_MsgName" BO_ 2566835657 "DM04_C9 - Freeze Frame Parameters";
BA_ "TpJ1939VarDlc" BO_ 2566835657 1;
BA_ "CI_MsgDefinition" BO_ 2566835695 "Iveco Proprietary";
BA_ "CI_MsgId" BO_ 2566835695 34583;
BA_ "CI_MsgName" BO_ 2566835695 "DM04_EF - Freeze Frame Parameters";
BA_ "TpJ1939VarDlc" BO_ 2566835695 1;
BA_ "CI_MsgDefinition" BO_ 2566835698 "Iveco Proprietary";
BA_ "CI_MsgId" BO_ 2566835698 38849;
BA_ "CI_MsgName" BO_ 2566835698 "DM04_F2 - Freeze Frame Parameters";
BA_ "TpJ1939VarDlc" BO_ 2566835698 1;
BA_ "CI_MsgDefinition" BO_ 2566835699 "Iveco Proprietary";
BA_ "CI_MsgId" BO_ 2566835699 21089;
BA_ "CI_MsgName" BO_ 2566835699 "DM04_F3 - Freeze Frame Parameters";
BA_ "TpJ1939VarDlc" BO_ 2566835699 1;
BA_ "CI_MsgDefinition" BO_ 2565867237 "J1939DA";
BA_ "CI_MsgId" BO_ 2565867237 4154;
BA_ "CI_MsgName" BO_ 2565867237 "EAC1_E5 - Electronic Axle Controller 1";
BA_ "GenMsgCycleTime" BO_ 2565867237 500;
BA_ "GenMsgCycleTimeFast" BO_ 2565867237 500;
BA_ "GenMsgDelayTime" BO_ 2565867237 250;
BA_ "GenMsgSendType" BO_ 2565867237 0;
BA_ "GenMsgStartDelayTime" BO_ 2565867237 124;
BA_ "CI_ParId" SG_ 2566723411 AllAirbagDeactSwSts_FD1753 "ID2366";
BA_ "CI_SigId" SG_ 2566723411 AllAirbagDeactSwSts_FD1753 43105;
BA_ "CI_SigName" SG_ 2566723411 AllAirbagDeactSwSts_FD1753 "All Airbag Deactivation Switch Status";
BA_ "GenSigTimeoutTime_PCM" SG_ 2566723411 AllAirbagDeactSwSts_FD1753 1250;
BA_ "SigType" SG_ 2566723411 AllAirbagDeactSwSts_FD1753 4;
BA_ "CI_ParId" SG_ 2566723411 PassAirbagDeactSwSts_FD1753 "4962";
BA_ "CI_SigId" SG_ 2566723411 PassAirbagDeactSwSts_FD1753 4430;
BA_ "CI_SigName" SG_ 2566723411 PassAirbagDeactSwSts_FD1753 "Passenger Airbag Deactivation Switch Status";
BA_ "GenSigTimeoutTime_PCM" SG_ 2566723411 PassAirbagDeactSwSts_FD1753 1250;
BA_ "SPN" SG_ 2566723411 PassAirbagDeactSwSts_FD1753 4962;
BA_ "SigType" SG_ 2566723411 PassAirbagDeactSwSts_FD1753 4;
BA_ "CI_ParId" SG_ 2566723411 Beltlock7Sts "4958";
BA_ "CI_SigId" SG_ 2566723411 Beltlock7Sts 4426;
BA_ "CI_SigName" SG_ 2566723411 Beltlock7Sts "Beltlock 7 Status";
BA_ "GenSigTimeoutTime_PCM" SG_ 2566723411 Beltlock7Sts 1250;
BA_ "SPN" SG_ 2566723411 Beltlock7Sts 4958;
BA_ "SigType" SG_ 2566723411 Beltlock7Sts 4;
BA_ "CI_ParId" SG_ 2566723411 Beltlock6Sts "4957";
BA_ "CI_SigId" SG_ 2566723411 Beltlock6Sts 4425;
BA_ "CI_SigName" SG_ 2566723411 Beltlock6Sts "Beltlock 6 Status";
BA_ "GenSigTimeoutTime_PCM" SG_ 2566723411 Beltlock6Sts 1250;
BA_ "SPN" SG_ 2566723411 Beltlock6Sts 4957;
BA_ "SigType" SG_ 2566723411 Beltlock6Sts 4;
BA_ "CI_ParId" SG_ 2566723411 Beltlock5Sts "4956";
BA_ "CI_SigId" SG_ 2566723411 Beltlock5Sts 4424;
BA_ "CI_SigName" SG_ 2566723411 Beltlock5Sts "Beltlock 5 Status";
BA_ "GenSigTimeoutTime_PCM" SG_ 2566723411 Beltlock5Sts 1250;
BA_ "SPN" SG_ 2566723411 Beltlock5Sts 4956;
BA_ "SigType" SG_ 2566723411 Beltlock5Sts 4;
BA_ "CI_ParId" SG_ 2566723411 Beltlock4Sts "4955";
BA_ "CI_SigId" SG_ 2566723411 Beltlock4Sts 4423;
BA_ "CI_SigName" SG_ 2566723411 Beltlock4Sts "Beltlock 4 Status";
BA_ "GenSigTimeoutTime_PCM" SG_ 2566723411 Beltlock4Sts 1250;
BA_ "SPN" SG_ 2566723411 Beltlock4Sts 4955;
BA_ "SigType" SG_ 2566723411 Beltlock4Sts 4;
BA_ "CI_ParId" SG_ 2566723411 Beltlock3Sts "4954";
BA_ "CI_SigId" SG_ 2566723411 Beltlock3Sts 4422;
BA_ "CI_SigName" SG_ 2566723411 Beltlock3Sts "Beltlock 3 Status";
BA_ "GenSigTimeoutTime_PCM" SG_ 2566723411 Beltlock3Sts 1250;
BA_ "SPN" SG_ 2566723411 Beltlock3Sts 4954;
BA_ "SigType" SG_ 2566723411 Beltlock3Sts 4;
BA_ "CI_ParId" SG_ 2566723411 PassBeltlockSts_FD1753 "4953";
BA_ "CI_SigId" SG_ 2566723411 PassBeltlockSts_FD1753 4421;
BA_ "CI_SigName" SG_ 2566723411 PassBeltlockSts_FD1753 "Passenger Beltlock Status";
BA_ "GenSigTimeoutTime_PCM" SG_ 2566723411 PassBeltlockSts_FD1753 1250;
BA_ "SPN" SG_ 2566723411 PassBeltlockSts_FD1753 4953;
BA_ "SigType" SG_ 2566723411 PassBeltlockSts_FD1753 4;
BA_ "CI_ParId" SG_ 2566723411 DrivBeltlockSts_FD1753 "4952";
BA_ "CI_SigId" SG_ 2566723411 DrivBeltlockSts_FD1753 4420;
BA_ "CI_SigName" SG_ 2566723411 DrivBeltlockSts_FD1753 "Driver Beltlock Status";
BA_ "GenSigTimeoutTime_PCM" SG_ 2566723411 DrivBeltlockSts_FD1753 1250;
BA_ "SPN" SG_ 2566723411 DrivBeltlockSts_FD1753 4952;
BA_ "SigType" SG_ 2566723411 DrivBeltlockSts_FD1753 4;
BA_ "CI_ParId" SG_ 2365579520 GasolInj4Diag "ID0123";
BA_ "CI_SigId" SG_ 2365579520 GasolInj4Diag 35810;
BA_ "CI_SigName" SG_ 2365579520 GasolInj4Diag "Gasoline Injector 4 Diagnosis";
BA_ "GenSigTimeoutTime_PCM" SG_ 2365579520 GasolInj4Diag 500;
BA_ "SigType" SG_ 2365579520 GasolInj4Diag 4;
BA_ "CI_ParId" SG_ 2365579520 GasolInj3Diag "ID0122";
BA_ "CI_SigId" SG_ 2365579520 GasolInj3Diag 35809;
BA_ "CI_SigName" SG_ 2365579520 GasolInj3Diag "Gasoline Injector 3 Diagnosis";
BA_ "GenSigTimeoutTime_PCM" SG_ 2365579520 GasolInj3Diag 500;
BA_ "SigType" SG_ 2365579520 GasolInj3Diag 4;
BA_ "CI_ParId" SG_ 2365579520 GasolInj2Diag "ID0121";
BA_ "CI_SigId" SG_ 2365579520 GasolInj2Diag 35808;
BA_ "CI_SigName" SG_ 2365579520 GasolInj2Diag "Gasoline Injector 2 Diagnosis";
BA_ "GenSigTimeoutTime_PCM" SG_ 2365579520 GasolInj2Diag 500;
BA_ "SigType" SG_ 2365579520 GasolInj2Diag 4;
BA_ "CI_ParId" SG_ 2365579520 GasolInj1Diag "ID0120";
BA_ "CI_SigId" SG_ 2365579520 GasolInj1Diag 35807;
BA_ "CI_SigName" SG_ 2365579520 GasolInj1Diag "Gasoline Injector 1 Diagnosis";
BA_ "GenSigTimeoutTime_PCM" SG_ 2365579520 GasolInj1Diag 500;
BA_ "SigType" SG_ 2365579520 GasolInj1Diag 4;
BA_ "CI_ParId" SG_ 2365579520 MuxSigOnCntVal "ID0119";
BA_ "CI_SigId" SG_ 2365579520 MuxSigOnCntVal 35806;
BA_ "CI_SigName" SG_ 2365579520 MuxSigOnCntVal "Multiplexed Signal on Counter value";
BA_ "GenSigTimeoutTime_PCM" SG_ 2365579520 MuxSigOnCntVal 500;
BA_ "CI_ParId" SG_ 2365579520 AckGasolInjEna "ID0115";
BA_ "CI_SigId" SG_ 2365579520 AckGasolInjEna 35805;
BA_ "CI_SigName" SG_ 2365579520 AckGasolInjEna "Acknowledge Gasoline Injectors Enable";
BA_ "GenSigTimeoutTime_PCM" SG_ 2365579520 AckGasolInjEna 500;
BA_ "CI_ParId" SG_ 2365579520 AckGasInjEna "ID0116";
BA_ "CI_SigId" SG_ 2365579520 AckGasInjEna 35804;
BA_ "CI_SigName" SG_ 2365579520 AckGasInjEna "Acknowledge Gas Injectors Enable";
BA_ "GenSigTimeoutTime_PCM" SG_ 2365579520 AckGasInjEna 500;
BA_ "CI_ParId" SG_ 2365579520 CngInjBottomFault "ID0117";
BA_ "CI_SigId" SG_ 2365579520 CngInjBottomFault 35803;
BA_ "CI_SigName" SG_ 2365579520 CngInjBottomFault "CNG Injector Bottom Fault";
BA_ "GenSigTimeoutTime_PCM" SG_ 2365579520 CngInjBottomFault 500;
BA_ "SigType" SG_ 2365579520 CngInjBottomFault 4;
BA_ "CI_ParId" SG_ 2365579520 RollCnt "ID0118";
BA_ "CI_SigId" SG_ 2365579520 RollCnt 35802;
BA_ "CI_SigName" SG_ 2365579520 RollCnt "Rolling Counter";
BA_ "GenSigTimeoutTime_PCM" SG_ 2365579520 RollCnt 500;
BA_ "CI_ParId" SG_ 2365579520 CngInj1Diag "ID0111";
BA_ "CI_SigId" SG_ 2365579520 CngInj1Diag 35801;
BA_ "CI_SigName" SG_ 2365579520 CngInj1Diag "CNG Injector 1 Diagnosis";
BA_ "GenSigTimeoutTime_PCM" SG_ 2365579520 CngInj1Diag 500;
BA_ "SigType" SG_ 2365579520 CngInj1Diag 4;
BA_ "CI_ParId" SG_ 2365579520 CngInj2Diag "ID0112";
BA_ "CI_SigId" SG_ 2365579520 CngInj2Diag 35800;
BA_ "CI_SigName" SG_ 2365579520 CngInj2Diag "CNG Injector 2 Diagnosis";
BA_ "GenSigTimeoutTime_PCM" SG_ 2365579520 CngInj2Diag 500;
BA_ "SigType" SG_ 2365579520 CngInj2Diag 4;
BA_ "CI_ParId" SG_ 2365579520 CngInj3Diag "ID0113";
BA_ "CI_SigId" SG_ 2365579520 CngInj3Diag 35799;
BA_ "CI_SigName" SG_ 2365579520 CngInj3Diag "CNG Injector 3 Diagnosis";
BA_ "GenSigTimeoutTime_PCM" SG_ 2365579520 CngInj3Diag 500;
BA_ "SigType" SG_ 2365579520 CngInj3Diag 4;
BA_ "CI_ParId" SG_ 2365579520 CngInj4Diag "ID0114";
BA_ "CI_SigId" SG_ 2365579520 CngInj4Diag 35798;
BA_ "CI_SigName" SG_ 2365579520 CngInj4Diag "CNG Injector 4 Diagnosis";
BA_ "GenSigTimeoutTime_PCM" SG_ 2365579520 CngInj4Diag 500;
BA_ "SigType" SG_ 2365579520 CngInj4Diag 4;
BA_ "CI_ParId" SG_ 2365579520 CngTankPrsSens "ID0110";
BA_ "CI_SigId" SG_ 2365579520 CngTankPrsSens 35797;
BA_ "CI_SigName" SG_ 2365579520 CngTankPrsSens "CNG Tank Pressure Sensor";
BA_ "GenSigTimeoutTime_PCM" SG_ 2365579520 CngTankPrsSens 500;
BA_ "SigType" SG_ 2365579520 CngTankPrsSens 1;
BA_ "CI_ParId" SG_ 2365579520 TempRailPrsSens "ID0109";
BA_ "CI_SigId" SG_ 2365579520 TempRailPrsSens 35796;
BA_ "CI_SigName" SG_ 2365579520 TempRailPrsSens "Temperature Rail Pressure Sensor";
BA_ "GenSigTimeoutTime_PCM" SG_ 2365579520 TempRailPrsSens 500;
BA_ "SigType" SG_ 2365579520 TempRailPrsSens 1;
BA_ "CI_ParId" SG_ 2365579520 FuelRailPrsSens "ID0108";
BA_ "CI_SigId" SG_ 2365579520 FuelRailPrsSens 35795;
BA_ "CI_SigName" SG_ 2365579520 FuelRailPrsSens "Fuel Rail Pressure Sensor";
BA_ "GenSigTimeoutTime_PCM" SG_ 2365579520 FuelRailPrsSens 500;
BA_ "SigType" SG_ 2365579520 FuelRailPrsSens 1;
BA_ "CI_ParId" SG_ 2365579520 FuelRailPrsSensValData "ID0101";
BA_ "CI_SigId" SG_ 2365579520 FuelRailPrsSensValData 35794;
BA_ "CI_SigName" SG_ 2365579520 FuelRailPrsSensValData "Fuel Rail Pressure Sensor Valid Data";
BA_ "GenSigTimeoutTime_PCM" SG_ 2365579520 FuelRailPrsSensValData 500;
BA_ "CI_ParId" SG_ 2365579520 TempRailPrsSensValData "ID0102";
BA_ "CI_SigId" SG_ 2365579520 TempRailPrsSensValData 35793;
BA_ "CI_SigName" SG_ 2365579520 TempRailPrsSensValData "Temperature Rail Pressure Sensor Valid Data";
BA_ "GenSigTimeoutTime_PCM" SG_ 2365579520 TempRailPrsSensValData 500;
BA_ "CI_ParId" SG_ 2365579520 CngTankPrsSensValData "ID0103";
BA_ "CI_SigId" SG_ 2365579520 CngTankPrsSensValData 35792;
BA_ "CI_SigName" SG_ 2365579520 CngTankPrsSensValData "CNG Tank Pressure Sensor Valid Data";
BA_ "GenSigTimeoutTime_PCM" SG_ 2365579520 CngTankPrsSensValData 500;
BA_ "CI_ParId" SG_ 2365579520 CngInjBottomFaultType "ID0104";
BA_ "CI_SigId" SG_ 2365579520 CngInjBottomFaultType 35791;
BA_ "CI_SigName" SG_ 2365579520 CngInjBottomFaultType "CNG Injector Bottom Fault Type";
BA_ "GenSigTimeoutTime_PCM" SG_ 2365579520 CngInjBottomFaultType 500;
BA_ "SigType" SG_ 2365579520 CngInjBottomFaultType 4;
BA_ "CI_ParId" SG_ 2365579520 FuelSelSts "ID0105";
BA_ "CI_SigId" SG_ 2365579520 FuelSelSts 35790;
BA_ "CI_SigName" SG_ 2365579520 FuelSelSts "Fuel Selector Status";
BA_ "GenSigTimeoutTime_PCM" SG_ 2365579520 FuelSelSts 500;
BA_ "CI_ParId" SG_ 2365579520 DiagInj2And3ValData "ID0106";
BA_ "CI_SigId" SG_ 2365579520 DiagInj2And3ValData 35789;
BA_ "CI_SigName" SG_ 2365579520 DiagInj2And3ValData "Diagnosis Injectors 2 and 3 Valid Data";
BA_ "GenSigTimeoutTime_PCM" SG_ 2365579520 DiagInj2And3ValData 500;
BA_ "CI_ParId" SG_ 2365579520 DiagInj1And4ValData "ID0107";
BA_ "CI_SigId" SG_ 2365579520 DiagInj1And4ValData 35788;
BA_ "CI_SigName" SG_ 2365579520 DiagInj1And4ValData "Diagnosis Injectors 1 and 4 Valid Data";
BA_ "GenSigTimeoutTime_PCM" SG_ 2365579520 DiagInj1And4ValData 500;
BA_ "CI_ParId" SG_ 2566843648 MaxVsl "74";
BA_ "CI_SigId" SG_ 2566843648 MaxVsl 3210;
BA_ "CI_SigName" SG_ 2566843648 MaxVsl "Maximum Vehicle Speed Limit";
BA_ "GenSigTimeoutTime_PCM" SG_ 2566843648 MaxVsl 1250;
BA_ "SPN" SG_ 2566843648 MaxVsl 74;
BA_ "SigType" SG_ 2566843648 MaxVsl 1;
BA_ "CI_ParId" SG_ 2566843676 MaxVsl_FEED1C "74";
BA_ "CI_SigId" SG_ 2566843676 MaxVsl_FEED1C 3219;
BA_ "CI_SigName" SG_ 2566843676 MaxVsl_FEED1C "Maximum Vehicle Speed Limit";
BA_ "GenSigSendType" SG_ 2566843676 MaxVsl_FEED1C 3;
BA_ "GenSigTimeoutTime_SGW" SG_ 2566843676 MaxVsl_FEED1C 5000;
BA_ "SPN" SG_ 2566843676 MaxVsl_FEED1C 74;
BA_ "SigType" SG_ 2566843676 MaxVsl_FEED1C 1;
BA_ "CI_ParId" SG_ 2566844672 CcSts "527";
BA_ "CI_SigId" SG_ 2566844672 CcSts 3047;
BA_ "CI_SigName" SG_ 2566844672 CcSts "Cruise Control States";
BA_ "GenSigTimeoutTime_PCM" SG_ 2566844672 CcSts 500;
BA_ "SPN" SG_ 2566844672 CcSts 527;
BA_ "CI_ParId" SG_ 2566844672 PtoGovSts "976";
BA_ "CI_SigId" SG_ 2566844672 PtoGovSts 3045;
BA_ "CI_SigName" SG_ 2566844672 PtoGovSts "PTO Governor State";
BA_ "GenSigTimeoutTime_PCM" SG_ 2566844672 PtoGovSts 500;
BA_ "SPN" SG_ 2566844672 PtoGovSts 976;
BA_ "CI_ParId" SG_ 2566844672 CcSetSpeed "86";
BA_ "CI_SigId" SG_ 2566844672 CcSetSpeed 3044;
BA_ "CI_SigName" SG_ 2566844672 CcSetSpeed "Cruise Control Set Speed";
BA_ "GenSigTimeoutTime_PCM" SG_ 2566844672 CcSetSpeed 500;
BA_ "SPN" SG_ 2566844672 CcSetSpeed 86;
BA_ "SigType" SG_ 2566844672 CcSetSpeed 1;
BA_ "CI_ParId" SG_ 2566844672 CcAccelSw "602";
BA_ "CI_SigId" SG_ 2566844672 CcAccelSw 3043;
BA_ "CI_SigName" SG_ 2566844672 CcAccelSw "Cruise Control Accelerate Switch";
BA_ "GenSigTimeoutTime_PCM" SG_ 2566844672 CcAccelSw 500;
BA_ "SPN" SG_ 2566844672 CcAccelSw 602;
BA_ "SigType" SG_ 2566844672 CcAccelSw 4;
BA_ "CI_ParId" SG_ 2566844672 CcResSw "601";
BA_ "CI_SigId" SG_ 2566844672 CcResSw 3042;
BA_ "CI_SigName" SG_ 2566844672 CcResSw "Cruise Control Resume Switch";
BA_ "GenSigTimeoutTime_PCM" SG_ 2566844672 CcResSw 500;
BA_ "SPN" SG_ 2566844672 CcResSw 601;
BA_ "SigType" SG_ 2566844672 CcResSw 4;
BA_ "CI_ParId" SG_ 2566844672 CcCoastDecelSw "600";
BA_ "CI_SigId" SG_ 2566844672 CcCoastDecelSw 3041;
BA_ "CI_SigName" SG_ 2566844672 CcCoastDecelSw "Cruise Control Coast (Decelerate) Switch";
BA_ "GenSigTimeoutTime_PCM" SG_ 2566844672 CcCoastDecelSw 500;
BA_ "SPN" SG_ 2566844672 CcCoastDecelSw 600;
BA_ "SigType" SG_ 2566844672 CcCoastDecelSw 4;
BA_ "CI_ParId" SG_ 2566844672 CcSetSw "599";
BA_ "CI_SigId" SG_ 2566844672 CcSetSw 3040;
BA_ "CI_SigName" SG_ 2566844672 CcSetSw "Cruise Control Set Switch";
BA_ "GenSigTimeoutTime_PCM" SG_ 2566844672 CcSetSw 500;
BA_ "SPN" SG_ 2566844672 CcSetSw 599;
BA_ "SigType" SG_ 2566844672 CcSetSw 4;
BA_ "CI_ParId" SG_ 2566844672 CltSw_FEF100 "598";
BA_ "CI_SigId" SG_ 2566844672 CltSw_FEF100 3039;
BA_ "CI_SigName" SG_ 2566844672 CltSw_FEF100 "Clutch Switch";
BA_ "GenSigTimeoutTime_PCM" SG_ 2566844672 CltSw_FEF100 500;
BA_ "SPN" SG_ 2566844672 CltSw_FEF100 598;
BA_ "SigType" SG_ 2566844672 CltSw_FEF100 4;
BA_ "CI_ParId" SG_ 2566844672 BrkSw "597";
BA_ "CI_SigId" SG_ 2566844672 BrkSw 3038;
BA_ "CI_SigName" SG_ 2566844672 BrkSw "Brake Switch";
BA_ "GenSigTimeoutTime_PCM" SG_ 2566844672 BrkSw 500;
BA_ "SPN" SG_ 2566844672 BrkSw 597;
BA_ "SigType" SG_ 2566844672 BrkSw 4;
BA_ "CI_ParId" SG_ 2566844672 CcEnaSw "596";
BA_ "CI_SigId" SG_ 2566844672 CcEnaSw 3037;
BA_ "CI_SigName" SG_ 2566844672 CcEnaSw "Cruise Control Enable Switch";
BA_ "GenSigTimeoutTime_PCM" SG_ 2566844672 CcEnaSw 500;
BA_ "SPN" SG_ 2566844672 CcEnaSw 596;
BA_ "SigType" SG_ 2566844672 CcEnaSw 4;
BA_ "CI_ParId" SG_ 2566844672 CcActv "595";
BA_ "CI_SigId" SG_ 2566844672 CcActv 3036;
BA_ "CI_SigName" SG_ 2566844672 CcActv "Cruise Control Active";
BA_ "GenSigTimeoutTime_PCM" SG_ 2566844672 CcActv 500;
BA_ "SPN" SG_ 2566844672 CcActv 595;
BA_ "SigType" SG_ 2566844672 CcActv 4;
BA_ "CI_ParId" SG_ 2566844672 WhBasedVehSpeed "84";
BA_ "CI_SigId" SG_ 2566844672 WhBasedVehSpeed 3035;
BA_ "CI_SigName" SG_ 2566844672 WhBasedVehSpeed "Wheel-Based Vehicle Speed";
BA_ "GenSigTimeoutTime_PCM" SG_ 2566844672 WhBasedVehSpeed 500;
BA_ "SPN" SG_ 2566844672 WhBasedVehSpeed 84;
BA_ "SigType" SG_ 2566844672 WhBasedVehSpeed 1;
BA_ "CI_ParId" SG_ 2566844689 CcSts_FEF111 "527";
BA_ "CI_SigId" SG_ 2566844689 CcSts_FEF111 3091;
BA_ "CI_SigName" SG_ 2566844689 CcSts_FEF111 "Cruise Control States";
BA_ "GenSigSendType" SG_ 2566844689 CcSts_FEF111 3;
BA_ "GenSigTimeoutTime_PCM" SG_ 2566844689 CcSts_FEF111 500;
BA_ "SPN" SG_ 2566844689 CcSts_FEF111 527;
BA_ "CI_ParId" SG_ 2566844689 CcSetSpeed_FEF111 "86";
BA_ "CI_SigId" SG_ 2566844689 CcSetSpeed_FEF111 3089;
BA_ "CI_SigName" SG_ 2566844689 CcSetSpeed_FEF111 "Cruise Control Set Speed";
BA_ "GenSigSendType" SG_ 2566844689 CcSetSpeed_FEF111 3;
BA_ "GenSigTimeoutTime_PCM" SG_ 2566844689 CcSetSpeed_FEF111 500;
BA_ "SPN" SG_ 2566844689 CcSetSpeed_FEF111 86;
BA_ "SigType" SG_ 2566844689 CcSetSpeed_FEF111 1;
BA_ "CI_ParId" SG_ 2566844689 CcAccelSw_FEF111 "602";
BA_ "CI_SigId" SG_ 2566844689 CcAccelSw_FEF111 3088;
BA_ "CI_SigName" SG_ 2566844689 CcAccelSw_FEF111 "Cruise Control Accelerate Switch";
BA_ "GenSigSendType" SG_ 2566844689 CcAccelSw_FEF111 3;
BA_ "GenSigTimeoutTime_PCM" SG_ 2566844689 CcAccelSw_FEF111 500;
BA_ "SPN" SG_ 2566844689 CcAccelSw_FEF111 602;
BA_ "SigType" SG_ 2566844689 CcAccelSw_FEF111 4;
BA_ "CI_ParId" SG_ 2566844689 CcResSw_FEF111 "601";
BA_ "CI_SigId" SG_ 2566844689 CcResSw_FEF111 3087;
BA_ "CI_SigName" SG_ 2566844689 CcResSw_FEF111 "Cruise Control Resume Switch";
BA_ "GenSigSendType" SG_ 2566844689 CcResSw_FEF111 3;
BA_ "GenSigTimeoutTime_PCM" SG_ 2566844689 CcResSw_FEF111 500;
BA_ "SPN" SG_ 2566844689 CcResSw_FEF111 601;
BA_ "SigType" SG_ 2566844689 CcResSw_FEF111 4;
BA_ "CI_ParId" SG_ 2566844689 CcCoastDecelSw_FEF111 "600";
BA_ "CI_SigId" SG_ 2566844689 CcCoastDecelSw_FEF111 3086;
BA_ "CI_SigName" SG_ 2566844689 CcCoastDecelSw_FEF111 "Cruise Control Coast (Decelerate) Switch";
BA_ "GenSigSendType" SG_ 2566844689 CcCoastDecelSw_FEF111 3;
BA_ "GenSigTimeoutTime_PCM" SG_ 2566844689 CcCoastDecelSw_FEF111 500;
BA_ "SPN" SG_ 2566844689 CcCoastDecelSw_FEF111 600;
BA_ "SigType" SG_ 2566844689 CcCoastDecelSw_FEF111 4;
BA_ "CI_ParId" SG_ 2566844689 CcSetSw_FEF111 "599";
BA_ "CI_SigId" SG_ 2566844689 CcSetSw_FEF111 3085;
BA_ "CI_SigName" SG_ 2566844689 CcSetSw_FEF111 "Cruise Control Set Switch";
BA_ "GenSigSendType" SG_ 2566844689 CcSetSw_FEF111 3;
BA_ "GenSigTimeoutTime_PCM" SG_ 2566844689 CcSetSw_FEF111 500;
BA_ "SPN" SG_ 2566844689 CcSetSw_FEF111 599;
BA_ "SigType" SG_ 2566844689 CcSetSw_FEF111 4;
BA_ "CI_ParId" SG_ 2566844689 CcEnaSw_FEF111 "596";
BA_ "CI_SigId" SG_ 2566844689 CcEnaSw_FEF111 3084;
BA_ "CI_SigName" SG_ 2566844689 CcEnaSw_FEF111 "Cruise Control Enable Switch";
BA_ "GenSigSendType" SG_ 2566844689 CcEnaSw_FEF111 3;
BA_ "GenSigTimeoutTime_PCM" SG_ 2566844689 CcEnaSw_FEF111 500;
BA_ "SPN" SG_ 2566844689 CcEnaSw_FEF111 596;
BA_ "SigType" SG_ 2566844689 CcEnaSw_FEF111 4;
BA_ "CI_ParId" SG_ 2566844689 CcActv_FEF111 "595";
BA_ "CI_SigId" SG_ 2566844689 CcActv_FEF111 3081;
BA_ "CI_SigName" SG_ 2566844689 CcActv_FEF111 "Cruise Control Active";
BA_ "GenSigSendType" SG_ 2566844689 CcActv_FEF111 3;
BA_ "GenSigTimeoutTime_PCM" SG_ 2566844689 CcActv_FEF111 500;
BA_ "SPN" SG_ 2566844689 CcActv_FEF111 595;
BA_ "SigType" SG_ 2566844689 CcActv_FEF111 4;
BA_ "CI_ParId" SG_ 2566708224 IsaVslRdySts "ID2316";
BA_ "CI_SigId" SG_ 2566708224 IsaVslRdySts 42794;
BA_ "CI_SigName" SG_ 2566708224 IsaVslRdySts "ISA Vehicle Speed Limit Readiness State";
BA_ "GenSigTimeoutTime_PCM" SG_ 2566708224 IsaVslRdySts 500;
BA_ "SigType" SG_ 2566708224 IsaVslRdySts 4;
BA_ "CI_ParId" SG_ 2566708224 VslaRdySts "ID2315";
BA_ "CI_SigId" SG_ 2566708224 VslaRdySts 42793;
BA_ "CI_SigName" SG_ 2566708224 VslaRdySts "Adjustable Vehicle Speed Limit Readiness State";
BA_ "GenSigTimeoutTime_PCM" SG_ 2566708224 VslaRdySts 500;
BA_ "SigType" SG_ 2566708224 VslaRdySts 4;
BA_ "CI_ParId" SG_ 2566708224 AebsRdySts "6208";
BA_ "CI_SigId" SG_ 2566708224 AebsRdySts 3169;
BA_ "CI_SigName" SG_ 2566708224 AebsRdySts "AEBS readiness state";
BA_ "GenSigTimeoutTime_PCM" SG_ 2566708224 AebsRdySts 500;
BA_ "SPN" SG_ 2566708224 AebsRdySts 6208;
BA_ "SigType" SG_ 2566708224 AebsRdySts 4;
BA_ "CI_ParId" SG_ 2566708224 AccRdySts "5606";
BA_ "CI_SigId" SG_ 2566708224 AccRdySts 3164;
BA_ "CI_SigName" SG_ 2566708224 AccRdySts "Adaptive Cruise Control Readiness Status";
BA_ "GenSigTimeoutTime_PCM" SG_ 2566708224 AccRdySts 500;
BA_ "SPN" SG_ 2566708224 AccRdySts 5606;
BA_ "SigType" SG_ 2566708224 AccRdySts 4;
BA_ "CI_ParId" SG_ 2365321995 VehSpeedAsilDConfor "ID0970";
BA_ "CI_SigId" SG_ 2365321995 VehSpeedAsilDConfor 3193;
BA_ "CI_SigName" SG_ 2365321995 VehSpeedAsilDConfor "Vehicle Speed ASIL D Conformance";
BA_ "GenSigTimeoutTime_PCM" SG_ 2365321995 VehSpeedAsilDConfor 500;
BA_ "SigType" SG_ 2365321995 VehSpeedAsilDConfor 4;
BA_ "CI_ParId" SG_ 2365321995 VehHoldSts "I803";
BA_ "CI_SigId" SG_ 2365321995 VehHoldSts 3192;
BA_ "CI_SigName" SG_ 2365321995 VehHoldSts "Vehicle Hold State";
BA_ "GenSigTimeoutTime_PCM" SG_ 2365321995 VehHoldSts 500;
BA_ "SigType" SG_ 2365321995 VehHoldSts 4;
BA_ "CI_ParId" SG_ 2365321995 YawRate "1808";
BA_ "CI_SigId" SG_ 2365321995 YawRate 3191;
BA_ "CI_SigName" SG_ 2365321995 YawRate "Yaw Rate";
BA_ "GenSigTimeoutTime_PCM" SG_ 2365321995 YawRate 500;
BA_ "SPN" SG_ 2365321995 YawRate 1808;
BA_ "SigType" SG_ 2365321995 YawRate 1;
BA_ "CI_ParId" SG_ 2365321995 DirVehSpeed "8166";
BA_ "CI_SigId" SG_ 2365321995 DirVehSpeed 3190;
BA_ "CI_SigName" SG_ 2365321995 DirVehSpeed "Directional Vehicle Speed";
BA_ "GenSigTimeoutTime_PCM" SG_ 2365321995 DirVehSpeed 500;
BA_ "SPN" SG_ 2365321995 DirVehSpeed 8166;
BA_ "SigType" SG_ 2365321995 DirVehSpeed 1;
BA_ "CI_ParId" SG_ 2566843136 UnitNumPwrUnit "233";
BA_ "CI_SigId" SG_ 2566843136 UnitNumPwrUnit 26049;
BA_ "CI_SigName" SG_ 2566843136 UnitNumPwrUnit "Unit Number (Power Unit)";
BA_ "SPN" SG_ 2566843136 UnitNumPwrUnit 233;
BA_ "SigType" SG_ 2566843136 UnitNumPwrUnit 8;
BA_ "CI_ParId" SG_ 2566843136 Sn "588";
BA_ "CI_SigId" SG_ 2566843136 Sn 26048;
BA_ "CI_SigName" SG_ 2566843136 Sn "Serial Number";
BA_ "SPN" SG_ 2566843136 Sn 588;
BA_ "SigType" SG_ 2566843136 Sn 8;
BA_ "CI_ParId" SG_ 2566843136 Model "587";
BA_ "CI_SigId" SG_ 2566843136 Model 26047;
BA_ "CI_SigName" SG_ 2566843136 Model "Model";
BA_ "SPN" SG_ 2566843136 Model 587;
BA_ "SigType" SG_ 2566843136 Model 8;
BA_ "CI_ParId" SG_ 2566843136 Make "586";
BA_ "CI_SigId" SG_ 2566843136 Make 26046;
BA_ "CI_SigName" SG_ 2566843136 Make "Make";
BA_ "SPN" SG_ 2566843136 Make 586;
BA_ "SigType" SG_ 2566843136 Make 8;
BA_ "CI_ParId" SG_ 2566843141 UnitNumPwrUnit_FEEB05 "233";
BA_ "CI_SigId" SG_ 2566843141 UnitNumPwrUnit_FEEB05 40727;
BA_ "CI_SigName" SG_ 2566843141 UnitNumPwrUnit_FEEB05 "Unit Number (Power Unit)";
BA_ "SPN" SG_ 2566843141 UnitNumPwrUnit_FEEB05 233;
BA_ "SigType" SG_ 2566843141 UnitNumPwrUnit_FEEB05 8;
BA_ "CI_ParId" SG_ 2566843141 Sn_FEEB05 "588";
BA_ "CI_SigId" SG_ 2566843141 Sn_FEEB05 40726;
BA_ "CI_SigName" SG_ 2566843141 Sn_FEEB05 "Serial Number";
BA_ "SPN" SG_ 2566843141 Sn_FEEB05 588;
BA_ "SigType" SG_ 2566843141 Sn_FEEB05 8;
BA_ "CI_ParId" SG_ 2566843141 Model_FEEB05 "587";
BA_ "CI_SigId" SG_ 2566843141 Model_FEEB05 40725;
BA_ "CI_SigName" SG_ 2566843141 Model_FEEB05 "Model";
BA_ "SPN" SG_ 2566843141 Model_FEEB05 587;
BA_ "SigType" SG_ 2566843141 Model_FEEB05 8;
BA_ "CI_ParId" SG_ 2566843141 Make_FEEB05 "586";
BA_ "CI_SigId" SG_ 2566843141 Make_FEEB05 40724;
BA_ "CI_SigName" SG_ 2566843141 Make_FEEB05 "Make";
BA_ "SPN" SG_ 2566843141 Make_FEEB05 586;
BA_ "SigType" SG_ 2566843141 Make_FEEB05 8;
BA_ "CI_ParId" SG_ 2566843143 Sn_FEEB07 "588";
BA_ "CI_SigId" SG_ 2566843143 Sn_FEEB07 38551;
BA_ "CI_SigName" SG_ 2566843143 Sn_FEEB07 "Serial Number";
BA_ "SPN" SG_ 2566843143 Sn_FEEB07 588;
BA_ "SigType" SG_ 2566843143 Sn_FEEB07 8;
BA_ "CI_ParId" SG_ 2566843143 Model_FEEB07 "587";
BA_ "CI_SigId" SG_ 2566843143 Model_FEEB07 38550;
BA_ "CI_SigName" SG_ 2566843143 Model_FEEB07 "Model";
BA_ "SPN" SG_ 2566843143 Model_FEEB07 587;
BA_ "SigType" SG_ 2566843143 Model_FEEB07 8;
BA_ "CI_ParId" SG_ 2566843143 Make_FEEB07 "586";
BA_ "CI_SigId" SG_ 2566843143 Make_FEEB07 38549;
BA_ "CI_SigName" SG_ 2566843143 Make_FEEB07 "Make";
BA_ "SPN" SG_ 2566843143 Make_FEEB07 586;
BA_ "SigType" SG_ 2566843143 Make_FEEB07 8;
BA_ "CI_ParId" SG_ 2566843159 UnitNumPwrUnit_FEEB17 "233";
BA_ "CI_SigId" SG_ 2566843159 UnitNumPwrUnit_FEEB17 26084;
BA_ "CI_SigName" SG_ 2566843159 UnitNumPwrUnit_FEEB17 "Unit Number (Power Unit)";
BA_ "SPN" SG_ 2566843159 UnitNumPwrUnit_FEEB17 233;
BA_ "SigType" SG_ 2566843159 UnitNumPwrUnit_FEEB17 8;
BA_ "CI_ParId" SG_ 2566843159 Sn_FEEB17 "588";
BA_ "CI_SigId" SG_ 2566843159 Sn_FEEB17 26083;
BA_ "CI_SigName" SG_ 2566843159 Sn_FEEB17 "Serial Number";
BA_ "SPN" SG_ 2566843159 Sn_FEEB17 588;
BA_ "SigType" SG_ 2566843159 Sn_FEEB17 8;
BA_ "CI_ParId" SG_ 2566843159 Model_FEEB17 "587";
BA_ "CI_SigId" SG_ 2566843159 Model_FEEB17 26082;
BA_ "CI_SigName" SG_ 2566843159 Model_FEEB17 "Model";
BA_ "SPN" SG_ 2566843159 Model_FEEB17 587;
BA_ "SigType" SG_ 2566843159 Model_FEEB17 8;
BA_ "CI_ParId" SG_ 2566843159 Make_FEEB17 "586";
BA_ "CI_SigId" SG_ 2566843159 Make_FEEB17 26081;
BA_ "CI_SigName" SG_ 2566843159 Make_FEEB17 "Make";
BA_ "SPN" SG_ 2566843159 Make_FEEB17 586;
BA_ "SigType" SG_ 2566843159 Make_FEEB17 8;
BA_ "CI_ParId" SG_ 2566843162 Sn_FEEB1A "588";
BA_ "CI_SigId" SG_ 2566843162 Sn_FEEB1A 34479;
BA_ "CI_SigName" SG_ 2566843162 Sn_FEEB1A "Serial Number";
BA_ "SPN" SG_ 2566843162 Sn_FEEB1A 588;
BA_ "SigType" SG_ 2566843162 Sn_FEEB1A 8;
BA_ "CI_ParId" SG_ 2566843162 Model_FEEB1A "587";
BA_ "CI_SigId" SG_ 2566843162 Model_FEEB1A 34478;
BA_ "CI_SigName" SG_ 2566843162 Model_FEEB1A "Model";
BA_ "SPN" SG_ 2566843162 Model_FEEB1A 587;
BA_ "SigType" SG_ 2566843162 Model_FEEB1A 8;
BA_ "CI_ParId" SG_ 2566843162 Make_FEEB1A "586";
BA_ "CI_SigId" SG_ 2566843162 Make_FEEB1A 34477;
BA_ "CI_SigName" SG_ 2566843162 Make_FEEB1A "Make";
BA_ "SPN" SG_ 2566843162 Make_FEEB1A 586;
BA_ "SigType" SG_ 2566843162 Make_FEEB1A 8;
BA_ "CI_ParId" SG_ 2566843165 Sn_FEEB1D "588";
BA_ "CI_SigId" SG_ 2566843165 Sn_FEEB1D 26098;
BA_ "CI_SigName" SG_ 2566843165 Sn_FEEB1D "Serial Number";
BA_ "SPN" SG_ 2566843165 Sn_FEEB1D 588;
BA_ "SigType" SG_ 2566843165 Sn_FEEB1D 8;
BA_ "CI_ParId" SG_ 2566843165 Model_FEEB1D "587";
BA_ "CI_SigId" SG_ 2566843165 Model_FEEB1D 26097;
BA_ "CI_SigName" SG_ 2566843165 Model_FEEB1D "Model";
BA_ "SPN" SG_ 2566843165 Model_FEEB1D 587;
BA_ "SigType" SG_ 2566843165 Model_FEEB1D 8;
BA_ "CI_ParId" SG_ 2566843165 Make_FEEB1D "586";
BA_ "CI_SigId" SG_ 2566843165 Make_FEEB1D 26096;
BA_ "CI_SigName" SG_ 2566843165 Make_FEEB1D "Make";
BA_ "SPN" SG_ 2566843165 Make_FEEB1D 586;
BA_ "SigType" SG_ 2566843165 Make_FEEB1D 8;
BA_ "CI_ParId" SG_ 2566843172 Sn_FEEB24 "588";
BA_ "CI_SigId" SG_ 2566843172 Sn_FEEB24 38556;
BA_ "CI_SigName" SG_ 2566843172 Sn_FEEB24 "Serial Number";
BA_ "SPN" SG_ 2566843172 Sn_FEEB24 588;
BA_ "SigType" SG_ 2566843172 Sn_FEEB24 8;
BA_ "CI_ParId" SG_ 2566843172 Model_FEEB24 "587";
BA_ "CI_SigId" SG_ 2566843172 Model_FEEB24 38555;
BA_ "CI_SigName" SG_ 2566843172 Model_FEEB24 "Model";
BA_ "SPN" SG_ 2566843172 Model_FEEB24 587;
BA_ "SigType" SG_ 2566843172 Model_FEEB24 8;
BA_ "CI_ParId" SG_ 2566843172 Make_FEEB24 "586";
BA_ "CI_SigId" SG_ 2566843172 Make_FEEB24 38554;
BA_ "CI_SigName" SG_ 2566843172 Make_FEEB24 "Make";
BA_ "SPN" SG_ 2566843172 Make_FEEB24 586;
BA_ "SigType" SG_ 2566843172 Make_FEEB24 8;
BA_ "CI_ParId" SG_ 2566843175 Sn_FEEB27 "588";
BA_ "CI_SigId" SG_ 2566843175 Sn_FEEB27 26108;
BA_ "CI_SigName" SG_ 2566843175 Sn_FEEB27 "Serial Number";
BA_ "SPN" SG_ 2566843175 Sn_FEEB27 588;
BA_ "SigType" SG_ 2566843175 Sn_FEEB27 8;
BA_ "CI_ParId" SG_ 2566843175 Model_FEEB27 "587";
BA_ "CI_SigId" SG_ 2566843175 Model_FEEB27 26107;
BA_ "CI_SigName" SG_ 2566843175 Model_FEEB27 "Model";
BA_ "SPN" SG_ 2566843175 Model_FEEB27 587;
BA_ "SigType" SG_ 2566843175 Model_FEEB27 8;
BA_ "CI_ParId" SG_ 2566843175 Make_FEEB27 "586";
BA_ "CI_SigId" SG_ 2566843175 Make_FEEB27 26106;
BA_ "CI_SigName" SG_ 2566843175 Make_FEEB27 "Make";
BA_ "SPN" SG_ 2566843175 Make_FEEB27 586;
BA_ "SigType" SG_ 2566843175 Make_FEEB27 8;
BA_ "CI_ParId" SG_ 2566843183 UnitNumPwrUnit_FEEB2F "233";
BA_ "CI_SigId" SG_ 2566843183 UnitNumPwrUnit_FEEB2F 26119;
BA_ "CI_SigName" SG_ 2566843183 UnitNumPwrUnit_FEEB2F "Unit Number (Power Unit)";
BA_ "SPN" SG_ 2566843183 UnitNumPwrUnit_FEEB2F 233;
BA_ "SigType" SG_ 2566843183 UnitNumPwrUnit_FEEB2F 8;
BA_ "CI_ParId" SG_ 2566843183 Sn_FEEB2F "588";
BA_ "CI_SigId" SG_ 2566843183 Sn_FEEB2F 26118;
BA_ "CI_SigName" SG_ 2566843183 Sn_FEEB2F "Serial Number";
BA_ "SPN" SG_ 2566843183 Sn_FEEB2F 588;
BA_ "SigType" SG_ 2566843183 Sn_FEEB2F 8;
BA_ "CI_ParId" SG_ 2566843183 Model_FEEB2F "587";
BA_ "CI_SigId" SG_ 2566843183 Model_FEEB2F 26117;
BA_ "CI_SigName" SG_ 2566843183 Model_FEEB2F "Model";
BA_ "SPN" SG_ 2566843183 Model_FEEB2F 587;
BA_ "SigType" SG_ 2566843183 Model_FEEB2F 8;
BA_ "CI_ParId" SG_ 2566843183 Make_FEEB2F "586";
BA_ "CI_SigId" SG_ 2566843183 Make_FEEB2F 26116;
BA_ "CI_SigName" SG_ 2566843183 Make_FEEB2F "Make";
BA_ "SPN" SG_ 2566843183 Make_FEEB2F 586;
BA_ "SigType" SG_ 2566843183 Make_FEEB2F 8;
BA_ "CI_ParId" SG_ 2566843184 Sn_FEEB30 "588";
BA_ "CI_SigId" SG_ 2566843184 Sn_FEEB30 34812;
BA_ "CI_SigName" SG_ 2566843184 Sn_FEEB30 "Serial Number";
BA_ "SPN" SG_ 2566843184 Sn_FEEB30 588;
BA_ "SigType" SG_ 2566843184 Sn_FEEB30 8;
BA_ "CI_ParId" SG_ 2566843184 Model_FEEB30 "587";
BA_ "CI_SigId" SG_ 2566843184 Model_FEEB30 34811;
BA_ "CI_SigName" SG_ 2566843184 Model_FEEB30 "Model";
BA_ "SPN" SG_ 2566843184 Model_FEEB30 587;
BA_ "SigType" SG_ 2566843184 Model_FEEB30 8;
BA_ "CI_ParId" SG_ 2566843184 Make_FEEB30 "586";
BA_ "CI_SigId" SG_ 2566843184 Make_FEEB30 34810;
BA_ "CI_SigName" SG_ 2566843184 Make_FEEB30 "Make";
BA_ "SPN" SG_ 2566843184 Make_FEEB30 586;
BA_ "SigType" SG_ 2566843184 Make_FEEB30 8;
BA_ "CI_ParId" SG_ 2566843201 UnitNumPwrUnit_FEEB41 "233";
BA_ "CI_SigId" SG_ 2566843201 UnitNumPwrUnit_FEEB41 26129;
BA_ "CI_SigName" SG_ 2566843201 UnitNumPwrUnit_FEEB41 "Unit Number (Power Unit)";
BA_ "SPN" SG_ 2566843201 UnitNumPwrUnit_FEEB41 233;
BA_ "SigType" SG_ 2566843201 UnitNumPwrUnit_FEEB41 8;
BA_ "CI_ParId" SG_ 2566843201 Sn_FEEB41 "588";
BA_ "CI_SigId" SG_ 2566843201 Sn_FEEB41 26128;
BA_ "CI_SigName" SG_ 2566843201 Sn_FEEB41 "Serial Number";
BA_ "SPN" SG_ 2566843201 Sn_FEEB41 588;
BA_ "SigType" SG_ 2566843201 Sn_FEEB41 8;
BA_ "CI_ParId" SG_ 2566843201 Model_FEEB41 "587";
BA_ "CI_SigId" SG_ 2566843201 Model_FEEB41 26127;
BA_ "CI_SigName" SG_ 2566843201 Model_FEEB41 "Model";
BA_ "SPN" SG_ 2566843201 Model_FEEB41 587;
BA_ "SigType" SG_ 2566843201 Model_FEEB41 8;
BA_ "CI_ParId" SG_ 2566843201 Make_FEEB41 "586";
BA_ "CI_SigId" SG_ 2566843201 Make_FEEB41 26126;
BA_ "CI_SigName" SG_ 2566843201 Make_FEEB41 "Make";
BA_ "SPN" SG_ 2566843201 Make_FEEB41 586;
BA_ "SigType" SG_ 2566843201 Make_FEEB41 8;
BA_ "CI_ParId" SG_ 2566843209 Sn_FEEB49 "588";
BA_ "CI_SigId" SG_ 2566843209 Sn_FEEB49 34484;
BA_ "CI_SigName" SG_ 2566843209 Sn_FEEB49 "Serial Number";
BA_ "SPN" SG_ 2566843209 Sn_FEEB49 588;
BA_ "SigType" SG_ 2566843209 Sn_FEEB49 8;
BA_ "CI_ParId" SG_ 2566843209 Model_FEEB49 "587";
BA_ "CI_SigId" SG_ 2566843209 Model_FEEB49 34483;
BA_ "CI_SigName" SG_ 2566843209 Model_FEEB49 "Model";
BA_ "SPN" SG_ 2566843209 Model_FEEB49 587;
BA_ "SigType" SG_ 2566843209 Model_FEEB49 8;
BA_ "CI_ParId" SG_ 2566843209 Make_FEEB49 "586";
BA_ "CI_SigId" SG_ 2566843209 Make_FEEB49 34482;
BA_ "CI_SigName" SG_ 2566843209 Make_FEEB49 "Make";
BA_ "SPN" SG_ 2566843209 Make_FEEB49 586;
BA_ "SigType" SG_ 2566843209 Make_FEEB49 8;
BA_ "CI_ParId" SG_ 2566843210 UnitNumPwrUnit_FEEB4A "233";
BA_ "CI_SigId" SG_ 2566843210 UnitNumPwrUnit_FEEB4A 26154;
BA_ "CI_SigName" SG_ 2566843210 UnitNumPwrUnit_FEEB4A "Unit Number (Power Unit)";
BA_ "SPN" SG_ 2566843210 UnitNumPwrUnit_FEEB4A 233;
BA_ "SigType" SG_ 2566843210 UnitNumPwrUnit_FEEB4A 8;
BA_ "CI_ParId" SG_ 2566843210 Sn_FEEB4A "588";
BA_ "CI_SigId" SG_ 2566843210 Sn_FEEB4A 26153;
BA_ "CI_SigName" SG_ 2566843210 Sn_FEEB4A "Serial Number";
BA_ "SPN" SG_ 2566843210 Sn_FEEB4A 588;
BA_ "SigType" SG_ 2566843210 Sn_FEEB4A 8;
BA_ "CI_ParId" SG_ 2566843210 Model_FEEB4A "587";
BA_ "CI_SigId" SG_ 2566843210 Model_FEEB4A 26152;
BA_ "CI_SigName" SG_ 2566843210 Model_FEEB4A "Model";
BA_ "SPN" SG_ 2566843210 Model_FEEB4A 587;
BA_ "SigType" SG_ 2566843210 Model_FEEB4A 8;
BA_ "CI_ParId" SG_ 2566843210 Make_FEEB4A "586";
BA_ "CI_SigId" SG_ 2566843210 Make_FEEB4A 26151;
BA_ "CI_SigName" SG_ 2566843210 Make_FEEB4A "Make";
BA_ "SPN" SG_ 2566843210 Make_FEEB4A 586;
BA_ "SigType" SG_ 2566843210 Make_FEEB4A 8;
BA_ "CI_ParId" SG_ 2566843213 UnitNumPwrUnit_FEEB4D "233";
BA_ "CI_SigId" SG_ 2566843213 UnitNumPwrUnit_FEEB4D 37234;
BA_ "CI_SigName" SG_ 2566843213 UnitNumPwrUnit_FEEB4D "Unit Number (Power Unit)";
BA_ "SPN" SG_ 2566843213 UnitNumPwrUnit_FEEB4D 233;
BA_ "SigType" SG_ 2566843213 UnitNumPwrUnit_FEEB4D 8;
BA_ "CI_ParId" SG_ 2566843213 Sn_FEEB4D "588";
BA_ "CI_SigId" SG_ 2566843213 Sn_FEEB4D 37233;
BA_ "CI_SigName" SG_ 2566843213 Sn_FEEB4D "Serial Number";
BA_ "SPN" SG_ 2566843213 Sn_FEEB4D 588;
BA_ "SigType" SG_ 2566843213 Sn_FEEB4D 8;
BA_ "CI_ParId" SG_ 2566843213 Model_FEEB4D "587";
BA_ "CI_SigId" SG_ 2566843213 Model_FEEB4D 37232;
BA_ "CI_SigName" SG_ 2566843213 Model_FEEB4D "Model";
BA_ "SPN" SG_ 2566843213 Model_FEEB4D 587;
BA_ "SigType" SG_ 2566843213 Model_FEEB4D 8;
BA_ "CI_ParId" SG_ 2566843213 Make_FEEB4D "586";
BA_ "CI_SigId" SG_ 2566843213 Make_FEEB4D 37231;
BA_ "CI_SigName" SG_ 2566843213 Make_FEEB4D "Make";
BA_ "SPN" SG_ 2566843213 Make_FEEB4D 586;
BA_ "SigType" SG_ 2566843213 Make_FEEB4D 8;
BA_ "CI_ParId" SG_ 2566843256 UnitNumPwrUnit_FEEB78 "233";
BA_ "CI_SigId" SG_ 2566843256 UnitNumPwrUnit_FEEB78 40194;
BA_ "CI_SigName" SG_ 2566843256 UnitNumPwrUnit_FEEB78 "Unit Number (Power Unit)";
BA_ "SPN" SG_ 2566843256 UnitNumPwrUnit_FEEB78 233;
BA_ "SigType" SG_ 2566843256 UnitNumPwrUnit_FEEB78 8;
BA_ "CI_ParId" SG_ 2566843256 Sn_FEEB78 "588";
BA_ "CI_SigId" SG_ 2566843256 Sn_FEEB78 40193;
BA_ "CI_SigName" SG_ 2566843256 Sn_FEEB78 "Serial Number";
BA_ "SPN" SG_ 2566843256 Sn_FEEB78 588;
BA_ "SigType" SG_ 2566843256 Sn_FEEB78 8;
BA_ "CI_ParId" SG_ 2566843256 Model_FEEB78 "587";
BA_ "CI_SigId" SG_ 2566843256 Model_FEEB78 40192;
BA_ "CI_SigName" SG_ 2566843256 Model_FEEB78 "Model";
BA_ "SPN" SG_ 2566843256 Model_FEEB78 587;
BA_ "SigType" SG_ 2566843256 Model_FEEB78 8;
BA_ "CI_ParId" SG_ 2566843256 Make_FEEB78 "586";
BA_ "CI_SigId" SG_ 2566843256 Make_FEEB78 40191;
BA_ "CI_SigName" SG_ 2566843256 Make_FEEB78 "Make";
BA_ "SPN" SG_ 2566843256 Make_FEEB78 586;
BA_ "SigType" SG_ 2566843256 Make_FEEB78 8;
BA_ "CI_ParId" SG_ 2566843260 Sn_FEEB7C "588";
BA_ "CI_SigId" SG_ 2566843260 Sn_FEEB7C 36818;
BA_ "CI_SigName" SG_ 2566843260 Sn_FEEB7C "Serial Number";
BA_ "SPN" SG_ 2566843260 Sn_FEEB7C 588;
BA_ "SigType" SG_ 2566843260 Sn_FEEB7C 8;
BA_ "CI_ParId" SG_ 2566843260 Model_FEEB7C "587";
BA_ "CI_SigId" SG_ 2566843260 Model_FEEB7C 36817;
BA_ "CI_SigName" SG_ 2566843260 Model_FEEB7C "Model";
BA_ "SPN" SG_ 2566843260 Model_FEEB7C 587;
BA_ "SigType" SG_ 2566843260 Model_FEEB7C 8;
BA_ "CI_ParId" SG_ 2566843260 Make_FEEB7C "586";
BA_ "CI_SigId" SG_ 2566843260 Make_FEEB7C 36816;
BA_ "CI_SigName" SG_ 2566843260 Make_FEEB7C "Make";
BA_ "SPN" SG_ 2566843260 Make_FEEB7C 586;
BA_ "SigType" SG_ 2566843260 Make_FEEB7C 8;
BA_ "CI_ParId" SG_ 2566843375 Sn_FEEBEF "588";
BA_ "CI_SigId" SG_ 2566843375 Sn_FEEBEF 34792;
BA_ "CI_SigName" SG_ 2566843375 Sn_FEEBEF "Serial Number";
BA_ "SPN" SG_ 2566843375 Sn_FEEBEF 588;
BA_ "SigType" SG_ 2566843375 Sn_FEEBEF 8;
BA_ "CI_ParId" SG_ 2566843375 Model_FEEBEF "587";
BA_ "CI_SigId" SG_ 2566843375 Model_FEEBEF 34791;
BA_ "CI_SigName" SG_ 2566843375 Model_FEEBEF "Model";
BA_ "SPN" SG_ 2566843375 Model_FEEBEF 587;
BA_ "SigType" SG_ 2566843375 Model_FEEBEF 8;
BA_ "CI_ParId" SG_ 2566843375 Make_FEEBEF "586";
BA_ "CI_SigId" SG_ 2566843375 Make_FEEBEF 34790;
BA_ "CI_SigName" SG_ 2566843375 Make_FEEBEF "Make";
BA_ "SPN" SG_ 2566843375 Make_FEEBEF 586;
BA_ "SigType" SG_ 2566843375 Make_FEEBEF 8;
BA_ "CI_ParId" SG_ 2566843378 Sn_FEEBF2 "588";
BA_ "CI_SigId" SG_ 2566843378 Sn_FEEBF2 39080;
BA_ "CI_SigName" SG_ 2566843378 Sn_FEEBF2 "Serial Number";
BA_ "SPN" SG_ 2566843378 Sn_FEEBF2 588;
BA_ "SigType" SG_ 2566843378 Sn_FEEBF2 8;
BA_ "CI_ParId" SG_ 2566843378 Model_FEEBF2 "587";
BA_ "CI_SigId" SG_ 2566843378 Model_FEEBF2 39079;
BA_ "CI_SigName" SG_ 2566843378 Model_FEEBF2 "Model";
BA_ "SPN" SG_ 2566843378 Model_FEEBF2 587;
BA_ "SigType" SG_ 2566843378 Model_FEEBF2 8;
BA_ "CI_ParId" SG_ 2566843378 Make_FEEBF2 "586";
BA_ "CI_SigId" SG_ 2566843378 Make_FEEBF2 39078;
BA_ "CI_SigName" SG_ 2566843378 Make_FEEBF2 "Make";
BA_ "SPN" SG_ 2566843378 Make_FEEBF2 586;
BA_ "SigType" SG_ 2566843378 Make_FEEBF2 8;
BA_ "CI_ParId" SG_ 2566843379 Sn_FEEBF3 "588";
BA_ "CI_SigId" SG_ 2566843379 Sn_FEEBF3 33378;
BA_ "CI_SigName" SG_ 2566843379 Sn_FEEBF3 "Serial Number";
BA_ "SPN" SG_ 2566843379 Sn_FEEBF3 588;
BA_ "SigType" SG_ 2566843379 Sn_FEEBF3 8;
BA_ "CI_ParId" SG_ 2566843379 Model_FEEBF3 "587";
BA_ "CI_SigId" SG_ 2566843379 Model_FEEBF3 33377;
BA_ "CI_SigName" SG_ 2566843379 Model_FEEBF3 "Model";
BA_ "SPN" SG_ 2566843379 Model_FEEBF3 587;
BA_ "SigType" SG_ 2566843379 Model_FEEBF3 8;
BA_ "CI_ParId" SG_ 2566843379 Make_FEEBF3 "586";
BA_ "CI_SigId" SG_ 2566843379 Make_FEEBF3 33376;
BA_ "CI_SigName" SG_ 2566843379 Make_FEEBF3 "Make";
BA_ "SPN" SG_ 2566843379 Make_FEEBF3 586;
BA_ "SigType" SG_ 2566843379 Make_FEEBF3 8;
BA_ "CI_ParId" SG_ 2563833623 IllBrtPc "1487";
BA_ "CI_SigId" SG_ 2563833623 IllBrtPc 4193;
BA_ "CI_SigName" SG_ 2563833623 IllBrtPc "Illumination Brightness Percent";
BA_ "GenSigSendType" SG_ 2563833623 IllBrtPc 3;
BA_ "GenSigTimeoutTime_PCM" SG_ 2563833623 IllBrtPc 25000;
BA_ "SPN" SG_ 2563833623 IllBrtPc 1487;
BA_ "SigType" SG_ 2563833623 IllBrtPc 1;
BA_ "CI_ParId" SG_ 2563829281 IllBrtPc_D0EE21 "1487";
BA_ "CI_SigId" SG_ 2563829281 IllBrtPc_D0EE21 4198;
BA_ "CI_SigName" SG_ 2563829281 IllBrtPc_D0EE21 "Illumination Brightness Percent";
BA_ "GenSigSendType" SG_ 2563829281 IllBrtPc_D0EE21 3;
BA_ "GenSigTimeoutTime_PCM" SG_ 2563829281 IllBrtPc_D0EE21 25000;
BA_ "SPN" SG_ 2563829281 IllBrtPc_D0EE21 1487;
BA_ "SigType" SG_ 2563829281 IllBrtPc_D0EE21 1;
BA_ "CI_ParId" SG_ 2563833665 IllBrtPc_D0FF41 "1487";
BA_ "CI_SigId" SG_ 2563833665 IllBrtPc_D0FF41 4204;
BA_ "CI_SigName" SG_ 2563833665 IllBrtPc_D0FF41 "Illumination Brightness Percent";
BA_ "GenSigSendType" SG_ 2563833665 IllBrtPc_D0FF41 3;
BA_ "GenSigTimeoutTime_PCM" SG_ 2563833665 IllBrtPc_D0FF41 25000;
BA_ "SPN" SG_ 2563833665 IllBrtPc_D0FF41 1487;
BA_ "SigType" SG_ 2563833665 IllBrtPc_D0FF41 1;
BA_ "CI_ParId" SG_ 2564882176 BatMainSwHoldReq "1682";
BA_ "CI_SigId" SG_ 2564882176 BatMainSwHoldReq 3241;
BA_ "CI_SigName" SG_ 2564882176 BatMainSwHoldReq "Battery Main Switch Hold Request";
BA_ "GenSigSendType" SG_ 2564882176 BatMainSwHoldReq 3;
BA_ "GenSigTimeoutTime_PCM" SG_ 2564882176 BatMainSwHoldReq 5000;
BA_ "SPN" SG_ 2564882176 BatMainSwHoldReq 1682;
BA_ "SigType" SG_ 2564882176 BatMainSwHoldReq 4;
BA_ "CI_ParId" SG_ 2564882179 EngAutoStartEnaSw "1656";
BA_ "CI_SigId" SG_ 2564882179 EngAutoStartEnaSw 3253;
BA_ "CI_SigName" SG_ 2564882179 EngAutoStartEnaSw "Engine Automatic Start Enable Switch";
BA_ "GenSigSendType" SG_ 2564882179 EngAutoStartEnaSw 3;
BA_ "GenSigTimeoutTime_PCM" SG_ 2564882179 EngAutoStartEnaSw 5000;
BA_ "SPN" SG_ 2564882179 EngAutoStartEnaSw 1656;
BA_ "SigType" SG_ 2564882179 EngAutoStartEnaSw 4;
BA_ "CI_ParId" SG_ 2564882199 AtRegenForceSw "3696";
BA_ "CI_SigId" SG_ 2564882199 AtRegenForceSw 3259;
BA_ "CI_SigName" SG_ 2564882199 AtRegenForceSw "Aftertreatment Regeneration Force Switch";
BA_ "GenSigSendType" SG_ 2564882199 AtRegenForceSw 3;
BA_ "GenSigTimeoutTime_PCM" SG_ 2564882199 AtRegenForceSw 5000;
BA_ "SPN" SG_ 2564882199 AtRegenForceSw 3696;
BA_ "SigType" SG_ 2564882199 AtRegenForceSw 4;
BA_ "CI_ParId" SG_ 2564882201 CabInternTempCmd "1691";
BA_ "CI_SigId" SG_ 2564882201 CabInternTempCmd 3263;
BA_ "CI_SigName" SG_ 2564882201 CabInternTempCmd "Cab Interior Temperature Command";
BA_ "GenSigSendType" SG_ 2564882201 CabInternTempCmd 3;
BA_ "GenSigTimeoutTime_PCM" SG_ 2564882201 CabInternTempCmd 5000;
BA_ "SPN" SG_ 2564882201 CabInternTempCmd 1691;
BA_ "SigType" SG_ 2564882201 CabInternTempCmd 1;
BA_ "CI_ParId" SG_ 2564882209 SeatBeltSw "1856";
BA_ "CI_SigId" SG_ 2564882209 SeatBeltSw 3276;
BA_ "CI_SigName" SG_ 2564882209 SeatBeltSw "Seat Belt Switch";
BA_ "GenSigSendType" SG_ 2564882209 SeatBeltSw 3;
BA_ "GenSigTimeoutTime_PCM" SG_ 2564882209 SeatBeltSw 5000;
BA_ "SPN" SG_ 2564882209 SeatBeltSw 1856;
BA_ "SigType" SG_ 2564882209 SeatBeltSw 4;
BA_ "CI_ParId" SG_ 2564882209 CabInternTempCmd_E0FF21 "1691";
BA_ "CI_SigId" SG_ 2564882209 CabInternTempCmd_E0FF21 3272;
BA_ "CI_SigName" SG_ 2564882209 CabInternTempCmd_E0FF21 "Cab Interior Temperature Command";
BA_ "GenSigSendType" SG_ 2564882209 CabInternTempCmd_E0FF21 3;
BA_ "GenSigTimeoutTime_PCM" SG_ 2564882209 CabInternTempCmd_E0FF21 5000;
BA_ "SPN" SG_ 2564882209 CabInternTempCmd_E0FF21 1691;
BA_ "SigType" SG_ 2564882209 CabInternTempCmd_E0FF21 1;
BA_ "CI_ParId" SG_ 2564882215 BatMainSwHoldReq_E0FF27 "1682";
BA_ "CI_SigId" SG_ 2564882215 BatMainSwHoldReq_E0FF27 3315;
BA_ "CI_SigName" SG_ 2564882215 BatMainSwHoldReq_E0FF27 "Battery Main Switch Hold Request";
BA_ "GenSigSendType" SG_ 2564882215 BatMainSwHoldReq_E0FF27 3;
BA_ "GenSigTimeoutTime_PCM" SG_ 2564882215 BatMainSwHoldReq_E0FF27 5000;
BA_ "SPN" SG_ 2564882215 BatMainSwHoldReq_E0FF27 1682;
BA_ "SigType" SG_ 2564882215 BatMainSwHoldReq_E0FF27 4;
BA_ "CI_ParId" SG_ 2564882227 BatMainSwHoldReq_E0FF33 "1682";
BA_ "CI_SigId" SG_ 2564882227 BatMainSwHoldReq_E0FF33 3318;
BA_ "CI_SigName" SG_ 2564882227 BatMainSwHoldReq_E0FF33 "Battery Main Switch Hold Request";
BA_ "GenSigSendType" SG_ 2564882227 BatMainSwHoldReq_E0FF33 3;
BA_ "GenSigTimeoutTime_PCM" SG_ 2564882227 BatMainSwHoldReq_E0FF33 5000;
BA_ "SPN" SG_ 2564882227 BatMainSwHoldReq_E0FF33 1682;
BA_ "SigType" SG_ 2564882227 BatMainSwHoldReq_E0FF33 4;
BA_ "CI_ParId" SG_ 2564882241 BatMainSwHoldReq_E0FF41 "1682";
BA_ "CI_SigId" SG_ 2564882241 BatMainSwHoldReq_E0FF41 3321;
BA_ "CI_SigName" SG_ 2564882241 BatMainSwHoldReq_E0FF41 "Battery Main Switch Hold Request";
BA_ "GenSigSendType" SG_ 2564882241 BatMainSwHoldReq_E0FF41 3;
BA_ "GenSigTimeoutTime_PCM" SG_ 2564882241 BatMainSwHoldReq_E0FF41 5000;
BA_ "SPN" SG_ 2564882241 BatMainSwHoldReq_E0FF41 1682;
BA_ "SigType" SG_ 2564882241 BatMainSwHoldReq_E0FF41 4;
BA_ "CI_ParId" SG_ 2564882250 BatMainSwHoldReq_E0FF4A "1682";
BA_ "CI_SigId" SG_ 2564882250 BatMainSwHoldReq_E0FF4A 45411;
BA_ "CI_SigName" SG_ 2564882250 BatMainSwHoldReq_E0FF4A "Battery Main Switch Hold Request";
BA_ "GenSigSendType" SG_ 2564882250 BatMainSwHoldReq_E0FF4A 3;
BA_ "GenSigTimeoutTime_SGW" SG_ 2564882250 BatMainSwHoldReq_E0FF4A 5000;
BA_ "SPN" SG_ 2564882250 BatMainSwHoldReq_E0FF4A 1682;
BA_ "SigType" SG_ 2564882250 BatMainSwHoldReq_E0FF4A 4;
BA_ "CI_ParId" SG_ 2566811659 Gcvw "1760";
BA_ "CI_SigId" SG_ 2566811659 Gcvw 956;
BA_ "CI_SigName" SG_ 2566811659 Gcvw "Gross Combination Vehicle Weight";
BA_ "GenSigTimeoutTime_PCM" SG_ 2566811659 Gcvw 5000;
BA_ "SPN" SG_ 2566811659 Gcvw 1760;
BA_ "SigType" SG_ 2566811659 Gcvw 1;
BA_ "CI_ParId" SG_ 2566811687 Gcvw_FE7027 "1760";
BA_ "CI_SigId" SG_ 2566811687 Gcvw_FE7027 35814;
BA_ "CI_SigName" SG_ 2566811687 Gcvw_FE7027 "Gross Combination Vehicle Weight";
BA_ "GenSigTimeoutTime_PCM" SG_ 2566811687 Gcvw_FE7027 5000;
BA_ "SPN" SG_ 2566811687 Gcvw_FE7027 1760;
BA_ "SigType" SG_ 2566811687 Gcvw_FE7027 1;
BA_ "CI_ParId" SG_ 2566802967 Sts2OfDoors "3411";
BA_ "CI_SigId" SG_ 2566802967 Sts2OfDoors 6164;
BA_ "CI_SigName" SG_ 2566802967 Sts2OfDoors "Status 2 of doors";
BA_ "GenSigSendType" SG_ 2566802967 Sts2OfDoors 3;
BA_ "GenSigTimeoutTime_PCM" SG_ 2566802967 Sts2OfDoors 5000;
BA_ "SPN" SG_ 2566802967 Sts2OfDoors 3411;
BA_ "SigType" SG_ 2566802967 Sts2OfDoors 4;
BA_ "CI_ParId" SG_ 2364609063 Dc_Dc1LsVBuckSetp "8561";
BA_ "CI_SigId" SG_ 2364609063 Dc_Dc1LsVBuckSetp 3613;
BA_ "CI_SigName" SG_ 2364609063 Dc_Dc1LsVBuckSetp "DC/DC 1 Low Side Voltage Buck Setpoint";
BA_ "GenSigTimeoutTime_PCM" SG_ 2364609063 Dc_Dc1LsVBuckSetp 500;
BA_ "SPN" SG_ 2364609063 Dc_Dc1LsVBuckSetp 8561;
BA_ "SigType" SG_ 2364609063 Dc_Dc1LsVBuckSetp 1;
BA_ "CI_ParId" SG_ 2364609063 Dc_Dc1OpCmd "8560";
BA_ "CI_SigId" SG_ 2364609063 Dc_Dc1OpCmd 3612;
BA_ "CI_SigName" SG_ 2364609063 Dc_Dc1OpCmd "DC/DC 1 Operational Command";
BA_ "GenSigTimeoutTime_PCM" SG_ 2364609063 Dc_Dc1OpCmd 500;
BA_ "SPN" SG_ 2364609063 Dc_Dc1OpCmd 8560;
BA_ "CI_ParId" SG_ 2365315367 Dc_Dc1LsCurMaxLimReq "8568";
BA_ "CI_SigId" SG_ 2365315367 Dc_Dc1LsCurMaxLimReq 33342;
BA_ "CI_SigName" SG_ 2365315367 Dc_Dc1LsCurMaxLimReq "DC/DC 1 Low Side Current Maximum Limit Request";
BA_ "GenSigSendType" SG_ 2365315367 Dc_Dc1LsCurMaxLimReq 3;
BA_ "GenSigTimeoutTime_PCM" SG_ 2365315367 Dc_Dc1LsCurMaxLimReq 5000;
BA_ "SPN" SG_ 2365315367 Dc_Dc1LsCurMaxLimReq 8568;
BA_ "SigType" SG_ 2365315367 Dc_Dc1LsCurMaxLimReq 1;
BA_ "CI_ParId" SG_ 2364609306 Dc_Dc1PwrLimDueToPwrElnTemp "8580";
BA_ "CI_SigId" SG_ 2364609306 Dc_Dc1PwrLimDueToPwrElnTemp 3639;
BA_ "CI_SigName" SG_ 2364609306 Dc_Dc1PwrLimDueToPwrElnTemp "DC/DC 1 Power Limit due to Power Electronics Temperature";
BA_ "GenSigTimeoutTime_PCM" SG_ 2364609306 Dc_Dc1PwrLimDueToPwrElnTemp 500;
BA_ "SPN" SG_ 2364609306 Dc_Dc1PwrLimDueToPwrElnTemp 8580;
BA_ "SigType" SG_ 2364609306 Dc_Dc1PwrLimDueToPwrElnTemp 4;
BA_ "CI_ParId" SG_ 2364609306 Dc_Dc1OpSts "8569";
BA_ "CI_SigId" SG_ 2364609306 Dc_Dc1OpSts 3628;
BA_ "CI_SigName" SG_ 2364609306 Dc_Dc1OpSts "DC/DC 1 Operational Status";
BA_ "GenSigTimeoutTime_PCM" SG_ 2364609306 Dc_Dc1OpSts 500;
BA_ "SPN" SG_ 2364609306 Dc_Dc1OpSts 8569;
BA_ "CI_ParId" SG_ 2364610330 Dc_Dc1HsPwr "8821";
BA_ "CI_SigId" SG_ 2364610330 Dc_Dc1HsPwr 3651;
BA_ "CI_SigName" SG_ 2364610330 Dc_Dc1HsPwr "DC/DC 1 High Side Power";
BA_ "GenSigTimeoutTime_PCM" SG_ 2364610330 Dc_Dc1HsPwr 500;
BA_ "SPN" SG_ 2364610330 Dc_Dc1HsPwr 8821;
BA_ "SigType" SG_ 2364610330 Dc_Dc1HsPwr 1;
BA_ "CI_ParId" SG_ 2364610330 Dc_Dc1LsPwr "8820";
BA_ "CI_SigId" SG_ 2364610330 Dc_Dc1LsPwr 3650;
BA_ "CI_SigName" SG_ 2364610330 Dc_Dc1LsPwr "DC/DC 1 Low Side Power";
BA_ "GenSigTimeoutTime_PCM" SG_ 2364610330 Dc_Dc1LsPwr 500;
BA_ "SPN" SG_ 2364610330 Dc_Dc1LsPwr 8820;
BA_ "SigType" SG_ 2364610330 Dc_Dc1LsPwr 1;
BA_ "CI_ParId" SG_ 2365315079 Dc_Dc1PwrElnTemp "8594";
BA_ "CI_SigId" SG_ 2365315079 Dc_Dc1PwrElnTemp 37801;
BA_ "CI_SigName" SG_ 2365315079 Dc_Dc1PwrElnTemp "DC/DC 1 Power Electronics Temperature";
BA_ "GenSigTimeoutTime_PCM" SG_ 2365315079 Dc_Dc1PwrElnTemp 5000;
BA_ "SPN" SG_ 2365315079 Dc_Dc1PwrElnTemp 8594;
BA_ "SigType" SG_ 2365315079 Dc_Dc1PwrElnTemp 1;
BA_ "CI_ParId" SG_ 2365315098 Dc_Dc1PwrElnTemp_BD81A "8594";
BA_ "CI_SigId" SG_ 2365315098 Dc_Dc1PwrElnTemp_BD81A 35350;
BA_ "CI_SigName" SG_ 2365315098 Dc_Dc1PwrElnTemp_BD81A "DC/DC 1 Power Electronics Temperature";
BA_ "GenSigTimeoutTime_PCM" SG_ 2365315098 Dc_Dc1PwrElnTemp_BD81A 5000;
BA_ "SPN" SG_ 2365315098 Dc_Dc1PwrElnTemp_BD81A 8594;
BA_ "SigType" SG_ 2365315098 Dc_Dc1PwrElnTemp_BD81A 1;
BA_ "CI_ParId" SG_ 2365315108 Dc_Dc1PwrElnTemp_BD824 "8594";
BA_ "CI_SigId" SG_ 2365315108 Dc_Dc1PwrElnTemp_BD824 37803;
BA_ "CI_SigName" SG_ 2365315108 Dc_Dc1PwrElnTemp_BD824 "DC/DC 1 Power Electronics Temperature";
BA_ "GenSigTimeoutTime_PCM" SG_ 2365315108 Dc_Dc1PwrElnTemp_BD824 5000;
BA_ "SPN" SG_ 2365315108 Dc_Dc1PwrElnTemp_BD824 8594;
BA_ "SigType" SG_ 2365315108 Dc_Dc1PwrElnTemp_BD824 1;
BA_ "CI_ParId" SG_ 2364609562 Dc_Dc1HsCur "8588";
BA_ "CI_SigId" SG_ 2364609562 Dc_Dc1HsCur 3648;
BA_ "CI_SigName" SG_ 2364609562 Dc_Dc1HsCur "DC/DC 1 High Side Current";
BA_ "GenSigTimeoutTime_PCM" SG_ 2364609562 Dc_Dc1HsCur 500;
BA_ "SPN" SG_ 2364609562 Dc_Dc1HsCur 8588;
BA_ "SigType" SG_ 2364609562 Dc_Dc1HsCur 1;
BA_ "CI_ParId" SG_ 2364609562 Dc_Dc1HsV "8587";
BA_ "CI_SigId" SG_ 2364609562 Dc_Dc1HsV 3647;
BA_ "CI_SigName" SG_ 2364609562 Dc_Dc1HsV "DC/DC 1 High Side Voltage";
BA_ "GenSigTimeoutTime_PCM" SG_ 2364609562 Dc_Dc1HsV 500;
BA_ "SPN" SG_ 2364609562 Dc_Dc1HsV 8587;
BA_ "SigType" SG_ 2364609562 Dc_Dc1HsV 1;
BA_ "CI_ParId" SG_ 2364609562 Dc_Dc1LsCur "8586";
BA_ "CI_SigId" SG_ 2364609562 Dc_Dc1LsCur 3646;
BA_ "CI_SigName" SG_ 2364609562 Dc_Dc1LsCur "DC/DC 1 Low Side Current";
BA_ "GenSigTimeoutTime_PCM" SG_ 2364609562 Dc_Dc1LsCur 500;
BA_ "SPN" SG_ 2364609562 Dc_Dc1LsCur 8586;
BA_ "SigType" SG_ 2364609562 Dc_Dc1LsCur 1;
BA_ "CI_ParId" SG_ 2364609562 Dc_Dc1LsV "8585";
BA_ "CI_SigId" SG_ 2364609562 Dc_Dc1LsV 3645;
BA_ "CI_SigName" SG_ 2364609562 Dc_Dc1LsV "DC/DC 1 Low Side Voltage";
BA_ "GenSigTimeoutTime_PCM" SG_ 2364609562 Dc_Dc1LsV 500;
BA_ "SPN" SG_ 2364609562 Dc_Dc1LsV 8585;
BA_ "SigType" SG_ 2364609562 Dc_Dc1LsV 1;
BA_ "CI_ParId" SG_ 2364610599 Dc_Dc2LsVBuckSetp "8893";
BA_ "CI_SigId" SG_ 2364610599 Dc_Dc2LsVBuckSetp 42766;
BA_ "CI_SigName" SG_ 2364610599 Dc_Dc2LsVBuckSetp "DC/DC 2 Low Side Voltage Buck Setpoint";
BA_ "GenSigTimeoutTime_PCM" SG_ 2364610599 Dc_Dc2LsVBuckSetp 500;
BA_ "SPN" SG_ 2364610599 Dc_Dc2LsVBuckSetp 8893;
BA_ "SigType" SG_ 2364610599 Dc_Dc2LsVBuckSetp 1;
BA_ "CI_ParId" SG_ 2364610599 Dc_Dc2OpCmd "8892";
BA_ "CI_SigId" SG_ 2364610599 Dc_Dc2OpCmd 42765;
BA_ "CI_SigName" SG_ 2364610599 Dc_Dc2OpCmd "DC/DC 2 Operational Command";
BA_ "GenSigTimeoutTime_PCM" SG_ 2364610599 Dc_Dc2OpCmd 500;
BA_ "SPN" SG_ 2364610599 Dc_Dc2OpCmd 8892;
BA_ "CI_ParId" SG_ 2365311015 Dc_Dc2LsCurMaxLimReq "8943";
BA_ "CI_SigId" SG_ 2365311015 Dc_Dc2LsCurMaxLimReq 42772;
BA_ "CI_SigName" SG_ 2365311015 Dc_Dc2LsCurMaxLimReq "DC/DC 2 Low Side Current Maximum Limit Request";
BA_ "GenSigSendType" SG_ 2365311015 Dc_Dc2LsCurMaxLimReq 3;
BA_ "GenSigTimeoutTime_PCM" SG_ 2365311015 Dc_Dc2LsCurMaxLimReq 5000;
BA_ "SPN" SG_ 2365311015 Dc_Dc2LsCurMaxLimReq 8943;
BA_ "SigType" SG_ 2365311015 Dc_Dc2LsCurMaxLimReq 1;
BA_ "CI_ParId" SG_ 2364611879 Dc_Dc3LsVBuckSetp "8948";
BA_ "CI_SigId" SG_ 2364611879 Dc_Dc3LsVBuckSetp 45703;
BA_ "CI_SigName" SG_ 2364611879 Dc_Dc3LsVBuckSetp "DC/DC 3 Low Side Voltage Buck Setpoint";
BA_ "GenSigTimeoutTime_PCM" SG_ 2364611879 Dc_Dc3LsVBuckSetp 500;
BA_ "SPN" SG_ 2364611879 Dc_Dc3LsVBuckSetp 8948;
BA_ "SigType" SG_ 2364611879 Dc_Dc3LsVBuckSetp 1;
BA_ "CI_ParId" SG_ 2364611879 Dc_Dc3OpCmd "8947";
BA_ "CI_SigId" SG_ 2364611879 Dc_Dc3OpCmd 45701;
BA_ "CI_SigName" SG_ 2364611879 Dc_Dc3OpCmd "DC/DC 3 Operational Command";
BA_ "GenSigTimeoutTime_PCM" SG_ 2364611879 Dc_Dc3OpCmd 500;
BA_ "SPN" SG_ 2364611879 Dc_Dc3OpCmd 8947;
BA_ "CI_ParId" SG_ 2365309479 Dc_Dc3LsCurMaxLimReq "8998";
BA_ "CI_SigId" SG_ 2365309479 Dc_Dc3LsCurMaxLimReq 45710;
BA_ "CI_SigName" SG_ 2365309479 Dc_Dc3LsCurMaxLimReq "DC/DC 3 Low Side Current Maximum Limit Request";
BA_ "GenSigSendType" SG_ 2365309479 Dc_Dc3LsCurMaxLimReq 3;
BA_ "GenSigTimeoutTime_PCM" SG_ 2365309479 Dc_Dc3LsCurMaxLimReq 5000;
BA_ "SPN" SG_ 2365309479 Dc_Dc3LsCurMaxLimReq 8998;
BA_ "SigType" SG_ 2365309479 Dc_Dc3LsCurMaxLimReq 1;
BA_ "CI_ParId" SG_ 2566847488 FuelLev1 "96";
BA_ "CI_SigId" SG_ 2566847488 FuelLev1 5157;
BA_ "CI_SigName" SG_ 2566847488 FuelLev1 "Fuel Level 1";
BA_ "GenSigTimeoutTime_PCM" SG_ 2566847488 FuelLev1 5000;
BA_ "SPN" SG_ 2566847488 FuelLev1 96;
BA_ "SigType" SG_ 2566847488 FuelLev1 1;
BA_ "CI_ParId" SG_ 2566847521 FuelLev2 "38";
BA_ "CI_SigId" SG_ 2566847521 FuelLev2 5175;
BA_ "CI_SigName" SG_ 2566847521 FuelLev2 "Fuel Level 2";
BA_ "GenSigTimeoutTime_PCM" SG_ 2566847521 FuelLev2 5000;
BA_ "SPN" SG_ 2566847521 FuelLev2 38;
BA_ "SigType" SG_ 2566847521 FuelLev2 1;
BA_ "CI_ParId" SG_ 2566847521 FuelLev1_FEFC21 "96";
BA_ "CI_SigId" SG_ 2566847521 FuelLev1_FEFC21 5171;
BA_ "CI_SigName" SG_ 2566847521 FuelLev1_FEFC21 "Fuel Level 1";
BA_ "GenSigTimeoutTime_PCM" SG_ 2566847521 FuelLev1_FEFC21 5000;
BA_ "SPN" SG_ 2566847521 FuelLev1_FEFC21 96;
BA_ "SigType" SG_ 2566847521 FuelLev1_FEFC21 1;
BA_ "CI_ParId" SG_ 2566810606 Driv2Id "1626";
BA_ "CI_SigId" SG_ 2566810606 Driv2Id 1640;
BA_ "CI_SigName" SG_ 2566810606 Driv2Id "Driver 2 identification";
BA_ "GenSigTimeoutTime_PCM" SG_ 2566810606 Driv2Id 50000;
BA_ "SPN" SG_ 2566810606 Driv2Id 1626;
BA_ "SigType" SG_ 2566810606 Driv2Id 8;
BA_ "CI_ParId" SG_ 2566810606 Driv1Id "1625";
BA_ "CI_SigId" SG_ 2566810606 Driv1Id 1639;
BA_ "CI_SigName" SG_ 2566810606 Driv1Id "Driver 1 identification";
BA_ "GenSigTimeoutTime_PCM" SG_ 2566810606 Driv1Id 50000;
BA_ "SPN" SG_ 2566810606 Driv1Id 1625;
BA_ "SigType" SG_ 2566810606 Driv1Id 8;
BA_ "CI_ParId" SG_ 2566718743 EngWaitToStartLampData "5416";
BA_ "CI_SigId" SG_ 2566718743 EngWaitToStartLampData 2546;
BA_ "CI_SigName" SG_ 2566718743 EngWaitToStartLampData "Engine Wait To Start Lamp Data";
BA_ "GenSigTimeoutTime_PCM" SG_ 2566718743 EngWaitToStartLampData 5000;
BA_ "SPN" SG_ 2566718743 EngWaitToStartLampData 5416;
BA_ "SigType" SG_ 2566718743 EngWaitToStartLampData 4;
BA_ "CI_ParId" SG_ 2566718743 EngCoolTempHighLampData "5100";
BA_ "CI_SigId" SG_ 2566718743 EngCoolTempHighLampData 2535;
BA_ "CI_SigName" SG_ 2566718743 EngCoolTempHighLampData "Engine Coolant Temperature High Lamp Data";
BA_ "GenSigTimeoutTime_PCM" SG_ 2566718743 EngCoolTempHighLampData 5000;
BA_ "SPN" SG_ 2566718743 EngCoolTempHighLampData 5100;
BA_ "SigType" SG_ 2566718743 EngCoolTempHighLampData 4;
BA_ "CI_ParId" SG_ 2566718743 ObdMilData "5096";
BA_ "CI_SigId" SG_ 2566718743 ObdMilData 2531;
BA_ "CI_SigName" SG_ 2566718743 ObdMilData "OBD Malfunction Indicator Lamp Data";
BA_ "GenSigTimeoutTime_PCM" SG_ 2566718743 ObdMilData 5000;
BA_ "SPN" SG_ 2566718743 ObdMilData 5096;
BA_ "SigType" SG_ 2566718743 ObdMilData 4;
BA_ "CI_ParId" SG_ 2566834688 SpnCm20 "1706";
BA_ "CI_SigId" SG_ 2566834688 SpnCm20 11746;
BA_ "CI_SigName" SG_ 2566834688 SpnCm20 "SPN Conversion Method 20";
BA_ "GenSigSendType" SG_ 2566834688 SpnCm20 3;
BA_ "GenSigTimeoutTime_PCM" SG_ 2566834688 SpnCm20 5000;
BA_ "SPN" SG_ 2566834688 SpnCm20 1706;
BA_ "CI_ParId" SG_ 2566834691 SpnCm10 "1706";
BA_ "CI_SigId" SG_ 2566834691 SpnCm10 11806;
BA_ "CI_SigName" SG_ 2566834691 SpnCm10 "SPN Conversion Method 10";
BA_ "GenSigSendType" SG_ 2566834691 SpnCm10 3;
BA_ "GenSigTimeoutTime_PCM" SG_ 2566834691 SpnCm10 5000;
BA_ "SPN" SG_ 2566834691 SpnCm10 1706;
BA_ "CI_ParId" SG_ 2566834693 SpnCm10_FECA05 "1706";
BA_ "CI_SigId" SG_ 2566834693 SpnCm10_FECA05 40782;
BA_ "CI_SigName" SG_ 2566834693 SpnCm10_FECA05 "SPN Conversion Method 10";
BA_ "GenSigSendType" SG_ 2566834693 SpnCm10_FECA05 3;
BA_ "GenSigTimeoutTime_PCM" SG_ 2566834693 SpnCm10_FECA05 5000;
BA_ "SPN" SG_ 2566834693 SpnCm10_FECA05 1706;
BA_ "CI_ParId" SG_ 2566834695 SpnCm10_FECA07 "1706";
BA_ "CI_SigId" SG_ 2566834695 SpnCm10_FECA07 37924;
BA_ "CI_SigName" SG_ 2566834695 SpnCm10_FECA07 "SPN Conversion Method 10";
BA_ "GenSigSendType" SG_ 2566834695 SpnCm10_FECA07 3;
BA_ "GenSigTimeoutTime_PCM" SG_ 2566834695 SpnCm10_FECA07 5000;
BA_ "SPN" SG_ 2566834695 SpnCm10_FECA07 1706;
BA_ "CI_ParId" SG_ 2566834699 SpnCm10_FECA0B "1706";
BA_ "CI_SigId" SG_ 2566834699 SpnCm10_FECA0B 12086;
BA_ "CI_SigName" SG_ 2566834699 SpnCm10_FECA0B "SPN Conversion Method 10";
BA_ "GenSigSendType" SG_ 2566834699 SpnCm10_FECA0B 3;
BA_ "GenSigTimeoutTime_PCM" SG_ 2566834699 SpnCm10_FECA0B 5000;
BA_ "SPN" SG_ 2566834699 SpnCm10_FECA0B 1706;
BA_ "CI_ParId" SG_ 2566834704 SpnCm10_FECA10 "1706";
BA_ "CI_SigId" SG_ 2566834704 SpnCm10_FECA10 12201;
BA_ "CI_SigName" SG_ 2566834704 SpnCm10_FECA10 "SPN Conversion Method 10";
BA_ "GenSigSendType" SG_ 2566834704 SpnCm10_FECA10 3;
BA_ "GenSigTimeoutTime_PCM" SG_ 2566834704 SpnCm10_FECA10 5000;
BA_ "SPN" SG_ 2566834704 SpnCm10_FECA10 1706;
BA_ "CI_ParId" SG_ 2566834707 SpnCm10_FECA13 "1706";
BA_ "CI_SigId" SG_ 2566834707 SpnCm10_FECA13 12256;
BA_ "CI_SigName" SG_ 2566834707 SpnCm10_FECA13 "SPN Conversion Method 10";
BA_ "GenSigSendType" SG_ 2566834707 SpnCm10_FECA13 3;
BA_ "GenSigTimeoutTime_PCM" SG_ 2566834707 SpnCm10_FECA13 5000;
BA_ "SPN" SG_ 2566834707 SpnCm10_FECA13 1706;
BA_ "CI_ParId" SG_ 2566834711 SpnCm20_FECA17 "1706";
BA_ "CI_SigId" SG_ 2566834711 SpnCm20_FECA17 12361;
BA_ "CI_SigName" SG_ 2566834711 SpnCm20_FECA17 "SPN Conversion Method 20";
BA_ "GenSigSendType" SG_ 2566834711 SpnCm20_FECA17 3;
BA_ "GenSigTimeoutTime_PCM" SG_ 2566834711 SpnCm20_FECA17 5000;
BA_ "SPN" SG_ 2566834711 SpnCm20_FECA17 1706;
BA_ "CI_ParId" SG_ 2566834713 SpnCm10_FECA19 "1706";
BA_ "CI_SigId" SG_ 2566834713 SpnCm10_FECA19 12416;
BA_ "CI_SigName" SG_ 2566834713 SpnCm10_FECA19 "SPN Conversion Method 10";
BA_ "GenSigSendType" SG_ 2566834713 SpnCm10_FECA19 3;
BA_ "GenSigTimeoutTime_PCM" SG_ 2566834713 SpnCm10_FECA19 5000;
BA_ "SPN" SG_ 2566834713 SpnCm10_FECA19 1706;
BA_ "CI_ParId" SG_ 2566834714 SpnCm10_FECA1A "1706";
BA_ "CI_SigId" SG_ 2566834714 SpnCm10_FECA1A 33846;
BA_ "CI_SigName" SG_ 2566834714 SpnCm10_FECA1A "SPN Conversion Method 10";
BA_ "GenSigSendType" SG_ 2566834714 SpnCm10_FECA1A 3;
BA_ "GenSigTimeoutTime_PCM" SG_ 2566834714 SpnCm10_FECA1A 5000;
BA_ "SPN" SG_ 2566834714 SpnCm10_FECA1A 1706;
BA_ "CI_ParId" SG_ 2566834717 SpnCm10_FECA1D "1706";
BA_ "CI_SigId" SG_ 2566834717 SpnCm10_FECA1D 12526;
BA_ "CI_SigName" SG_ 2566834717 SpnCm10_FECA1D "SPN Conversion Method 10";
BA_ "GenSigSendType" SG_ 2566834717 SpnCm10_FECA1D 3;
BA_ "GenSigTimeoutTime_PCM" SG_ 2566834717 SpnCm10_FECA1D 5000;
BA_ "SPN" SG_ 2566834717 SpnCm10_FECA1D 1706;
BA_ "CI_ParId" SG_ 2566834721 SpnCm10_FECA21 "1706";
BA_ "CI_SigId" SG_ 2566834721 SpnCm10_FECA21 12582;
BA_ "CI_SigName" SG_ 2566834721 SpnCm10_FECA21 "SPN Conversion Method 10";
BA_ "GenSigSendType" SG_ 2566834721 SpnCm10_FECA21 3;
BA_ "GenSigTimeoutTime_PCM" SG_ 2566834721 SpnCm10_FECA21 5000;
BA_ "SPN" SG_ 2566834721 SpnCm10_FECA21 1706;
BA_ "CI_ParId" SG_ 2566834724 SpnCm10_FECA24 "1706";
BA_ "CI_SigId" SG_ 2566834724 SpnCm10_FECA24 37979;
BA_ "CI_SigName" SG_ 2566834724 SpnCm10_FECA24 "SPN Conversion Method 10";
BA_ "GenSigSendType" SG_ 2566834724 SpnCm10_FECA24 3;
BA_ "GenSigTimeoutTime_PCM" SG_ 2566834724 SpnCm10_FECA24 5000;
BA_ "SPN" SG_ 2566834724 SpnCm10_FECA24 1706;
BA_ "CI_ParId" SG_ 2566834727 SpnCm10_FECA27 "1706";
BA_ "CI_SigId" SG_ 2566834727 SpnCm10_FECA27 12692;
BA_ "CI_SigName" SG_ 2566834727 SpnCm10_FECA27 "SPN Conversion Method 10";
BA_ "GenSigTimeoutTime_PCM" SG_ 2566834727 SpnCm10_FECA27 5000;
BA_ "SPN" SG_ 2566834727 SpnCm10_FECA27 1706;
BA_ "CI_ParId" SG_ 2566834730 SpnCm10_FECA2A "1706";
BA_ "CI_SigId" SG_ 2566834730 SpnCm10_FECA2A 12802;
BA_ "CI_SigName" SG_ 2566834730 SpnCm10_FECA2A "SPN Conversion Method 10";
BA_ "GenSigSendType" SG_ 2566834730 SpnCm10_FECA2A 3;
BA_ "GenSigTimeoutTime_PCM" SG_ 2566834730 SpnCm10_FECA2A 5000;
BA_ "SPN" SG_ 2566834730 SpnCm10_FECA2A 1706;
BA_ "CI_ParId" SG_ 2566834735 SpnCm10_FECA2F "1706";
BA_ "CI_SigId" SG_ 2566834735 SpnCm10_FECA2F 12747;
BA_ "CI_SigName" SG_ 2566834735 SpnCm10_FECA2F "SPN Conversion Method 10";
BA_ "GenSigSendType" SG_ 2566834735 SpnCm10_FECA2F 3;
BA_ "GenSigTimeoutTime_PCM" SG_ 2566834735 SpnCm10_FECA2F 5000;
BA_ "SPN" SG_ 2566834735 SpnCm10_FECA2F 1706;
BA_ "CI_ParId" SG_ 2566834736 SpnCm10_FECA30 "1706";
BA_ "CI_SigId" SG_ 2566834736 SpnCm10_FECA30 34882;
BA_ "CI_SigName" SG_ 2566834736 SpnCm10_FECA30 "SPN Conversion Method 10";
BA_ "GenSigSendType" SG_ 2566834736 SpnCm10_FECA30 3;
BA_ "GenSigTimeoutTime_PCM" SG_ 2566834736 SpnCm10_FECA30 5000;
BA_ "SPN" SG_ 2566834736 SpnCm10_FECA30 1706;
BA_ "CI_ParId" SG_ 2566834739 SpnCm10_FECA33 "1706";
BA_ "CI_SigId" SG_ 2566834739 SpnCm10_FECA33 13023;
BA_ "CI_SigName" SG_ 2566834739 SpnCm10_FECA33 "SPN Conversion Method 10";
BA_ "GenSigSendType" SG_ 2566834739 SpnCm10_FECA33 3;
BA_ "GenSigTimeoutTime_PCM" SG_ 2566834739 SpnCm10_FECA33 5000;
BA_ "SPN" SG_ 2566834739 SpnCm10_FECA33 1706;
BA_ "CI_ParId" SG_ 2566834753 SpnCm10_FECA41 "1706";
BA_ "CI_SigId" SG_ 2566834753 SpnCm10_FECA41 13164;
BA_ "CI_SigName" SG_ 2566834753 SpnCm10_FECA41 "SPN Conversion Method 10";
BA_ "GenSigSendType" SG_ 2566834753 SpnCm10_FECA41 3;
BA_ "GenSigTimeoutTime_PCM" SG_ 2566834753 SpnCm10_FECA41 5000;
BA_ "SPN" SG_ 2566834753 SpnCm10_FECA41 1706;
BA_ "CI_ParId" SG_ 2566834761 SpnCm10_FECA49 "1706";
BA_ "CI_SigId" SG_ 2566834761 SpnCm10_FECA49 33901;
BA_ "CI_SigName" SG_ 2566834761 SpnCm10_FECA49 "SPN Conversion Method 10";
BA_ "GenSigSendType" SG_ 2566834761 SpnCm10_FECA49 3;
BA_ "GenSigTimeoutTime_PCM" SG_ 2566834761 SpnCm10_FECA49 5000;
BA_ "SPN" SG_ 2566834761 SpnCm10_FECA49 1706;
BA_ "CI_ParId" SG_ 2566834762 SpnCm10_FECA4A "1706";
BA_ "CI_SigId" SG_ 2566834762 SpnCm10_FECA4A 13494;
BA_ "CI_SigName" SG_ 2566834762 SpnCm10_FECA4A "SPN Conversion Method 10";
BA_ "GenSigSendType" SG_ 2566834762 SpnCm10_FECA4A 3;
BA_ "GenSigTimeoutTime_SGW" SG_ 2566834762 SpnCm10_FECA4A 5000;
BA_ "SPN" SG_ 2566834762 SpnCm10_FECA4A 1706;
BA_ "CI_ParId" SG_ 2566834765 SpnCm10_FECA4D "1706";
BA_ "CI_SigId" SG_ 2566834765 SpnCm10_FECA4D 36952;
BA_ "CI_SigName" SG_ 2566834765 SpnCm10_FECA4D "SPN Conversion Method 10";
BA_ "GenSigSendType" SG_ 2566834765 SpnCm10_FECA4D 3;
BA_ "GenSigTimeoutTime_PCM" SG_ 2566834765 SpnCm10_FECA4D 5000;
BA_ "SPN" SG_ 2566834765 SpnCm10_FECA4D 1706;
BA_ "CI_ParId" SG_ 2566834771 SpnCm10_FECA53 "1706";
BA_ "CI_SigId" SG_ 2566834771 SpnCm10_FECA53 13825;
BA_ "CI_SigName" SG_ 2566834771 SpnCm10_FECA53 "SPN Conversion Method 10";
BA_ "GenSigSendType" SG_ 2566834771 SpnCm10_FECA53 3;
BA_ "GenSigTimeoutTime_PCM" SG_ 2566834771 SpnCm10_FECA53 5000;
BA_ "SPN" SG_ 2566834771 SpnCm10_FECA53 1706;
BA_ "CI_ParId" SG_ 2566834802 SpnCm10_FECA72 "1706";
BA_ "CI_SigId" SG_ 2566834802 SpnCm10_FECA72 14055;
BA_ "CI_SigName" SG_ 2566834802 SpnCm10_FECA72 "SPN Conversion Method 10";
BA_ "GenSigSendType" SG_ 2566834802 SpnCm10_FECA72 3;
BA_ "GenSigTimeoutTime_PCM" SG_ 2566834802 SpnCm10_FECA72 5000;
BA_ "SPN" SG_ 2566834802 SpnCm10_FECA72 1706;
BA_ "CI_ParId" SG_ 2566834808 SpnCm10_FECA78 "1706";
BA_ "CI_SigId" SG_ 2566834808 SpnCm10_FECA78 39926;
BA_ "CI_SigName" SG_ 2566834808 SpnCm10_FECA78 "SPN Conversion Method 10";
BA_ "GenSigSendType" SG_ 2566834808 SpnCm10_FECA78 3;
BA_ "GenSigTimeoutTime_PCM" SG_ 2566834808 SpnCm10_FECA78 5000;
BA_ "SPN" SG_ 2566834808 SpnCm10_FECA78 1706;
BA_ "CI_ParId" SG_ 2566834812 SpnCm10_FECA7C "1706";
BA_ "CI_SigId" SG_ 2566834812 SpnCm10_FECA7C 36537;
BA_ "CI_SigName" SG_ 2566834812 SpnCm10_FECA7C "SPN Conversion Method 10";
BA_ "GenSigSendType" SG_ 2566834812 SpnCm10_FECA7C 3;
BA_ "GenSigTimeoutTime_PCM" SG_ 2566834812 SpnCm10_FECA7C 5000;
BA_ "SPN" SG_ 2566834812 SpnCm10_FECA7C 1706;
BA_ "CI_ParId" SG_ 2566834817 SpnCm10_FECA81 "1706";
BA_ "CI_SigId" SG_ 2566834817 SpnCm10_FECA81 36142;
BA_ "CI_SigName" SG_ 2566834817 SpnCm10_FECA81 "SPN Conversion Method 10";
BA_ "GenSigSendType" SG_ 2566834817 SpnCm10_FECA81 3;
BA_ "GenSigTimeoutTime_PCM" SG_ 2566834817 SpnCm10_FECA81 5000;
BA_ "SPN" SG_ 2566834817 SpnCm10_FECA81 1706;
BA_ "CI_ParId" SG_ 2566834844 SpnCm10_FECA9C "1706";
BA_ "CI_SigId" SG_ 2566834844 SpnCm10_FECA9C 42894;
BA_ "CI_SigName" SG_ 2566834844 SpnCm10_FECA9C "SPN Conversion Method 10";
BA_ "GenSigSendType" SG_ 2566834844 SpnCm10_FECA9C 3;
BA_ "GenSigTimeoutTime_PCM" SG_ 2566834844 SpnCm10_FECA9C 5000;
BA_ "SPN" SG_ 2566834844 SpnCm10_FECA9C 1706;
BA_ "CI_ParId" SG_ 2566834846 SpnCm10_FECA9E "1706";
BA_ "CI_SigId" SG_ 2566834846 SpnCm10_FECA9E 42949;
BA_ "CI_SigName" SG_ 2566834846 SpnCm10_FECA9E "SPN Conversion Method 10";
BA_ "GenSigSendType" SG_ 2566834846 SpnCm10_FECA9E 3;
BA_ "GenSigTimeoutTime_PCM" SG_ 2566834846 SpnCm10_FECA9E 5000;
BA_ "SPN" SG_ 2566834846 SpnCm10_FECA9E 1706;
BA_ "CI_ParId" SG_ 2566834847 SpnCm10_FECA9F "1706";
BA_ "CI_SigId" SG_ 2566834847 SpnCm10_FECA9F 14236;
BA_ "CI_SigName" SG_ 2566834847 SpnCm10_FECA9F "SPN Conversion Method 10";
BA_ "GenSigSendType" SG_ 2566834847 SpnCm10_FECA9F 3;
BA_ "GenSigTimeoutTime_PCM" SG_ 2566834847 SpnCm10_FECA9F 5000;
BA_ "SPN" SG_ 2566834847 SpnCm10_FECA9F 1706;
BA_ "CI_ParId" SG_ 2566834848 SpnCm10_FECAA0 "1706";
BA_ "CI_SigId" SG_ 2566834848 SpnCm10_FECAA0 14291;
BA_ "CI_SigName" SG_ 2566834848 SpnCm10_FECAA0 "SPN Conversion Method 10";
BA_ "GenSigSendType" SG_ 2566834848 SpnCm10_FECAA0 3;
BA_ "GenSigTimeoutTime_PCM" SG_ 2566834848 SpnCm10_FECAA0 5000;
BA_ "SPN" SG_ 2566834848 SpnCm10_FECAA0 1706;
BA_ "CI_ParId" SG_ 2566834889 SpnCm10_FECAC9 "1706";
BA_ "CI_SigId" SG_ 2566834889 SpnCm10_FECAC9 41892;
BA_ "CI_SigName" SG_ 2566834889 SpnCm10_FECAC9 "SPN Conversion Method 10";
BA_ "GenSigSendType" SG_ 2566834889 SpnCm10_FECAC9 3;
BA_ "GenSigTimeoutTime_PCM" SG_ 2566834889 SpnCm10_FECAC9 5000;
BA_ "SPN" SG_ 2566834889 SpnCm10_FECAC9 1706;
BA_ "CI_ParId" SG_ 2566834917 SpnCm10_FECAE5 "1706";
BA_ "CI_SigId" SG_ 2566834917 SpnCm10_FECAE5 14456;
BA_ "CI_SigName" SG_ 2566834917 SpnCm10_FECAE5 "SPN Conversion Method 10";
BA_ "GenSigSendType" SG_ 2566834917 SpnCm10_FECAE5 3;
BA_ "GenSigTimeoutTime_PCM" SG_ 2566834917 SpnCm10_FECAE5 5000;
BA_ "SPN" SG_ 2566834917 SpnCm10_FECAE5 1706;
BA_ "CI_ParId" SG_ 2566834926 SpnCm10_FECAEE "1706";
BA_ "CI_SigId" SG_ 2566834926 SpnCm10_FECAEE 14687;
BA_ "CI_SigName" SG_ 2566834926 SpnCm10_FECAEE "SPN Conversion Method 10";
BA_ "GenSigSendType" SG_ 2566834926 SpnCm10_FECAEE 3;
BA_ "GenSigTimeoutTime_PCM" SG_ 2566834926 SpnCm10_FECAEE 5000;
BA_ "SPN" SG_ 2566834926 SpnCm10_FECAEE 1706;
BA_ "CI_ParId" SG_ 2566834927 SpnCm10_FECAEF "1706";
BA_ "CI_SigId" SG_ 2566834927 SpnCm10_FECAEF 14743;
BA_ "CI_SigName" SG_ 2566834927 SpnCm10_FECAEF "SPN Conversion Method 10";
BA_ "GenSigSendType" SG_ 2566834927 SpnCm10_FECAEF 3;
BA_ "GenSigTimeoutTime_PCM" SG_ 2566834927 SpnCm10_FECAEF 5000;
BA_ "SPN" SG_ 2566834927 SpnCm10_FECAEF 1706;
BA_ "CI_ParId" SG_ 2566834930 SpnCm10_FECAF2 "1706";
BA_ "CI_SigId" SG_ 2566834930 SpnCm10_FECAF2 38791;
BA_ "CI_SigName" SG_ 2566834930 SpnCm10_FECAF2 "SPN Conversion Method 10";
BA_ "GenSigSendType" SG_ 2566834930 SpnCm10_FECAF2 3;
BA_ "GenSigTimeoutTime_PCM" SG_ 2566834930 SpnCm10_FECAF2 5000;
BA_ "SPN" SG_ 2566834930 SpnCm10_FECAF2 1706;
BA_ "CI_ParId" SG_ 2566834931 SpnCm10_FECAF3 "1706";
BA_ "CI_SigId" SG_ 2566834931 SpnCm10_FECAF3 14798;
BA_ "CI_SigName" SG_ 2566834931 SpnCm10_FECAF3 "SPN Conversion Method 10";
BA_ "GenSigSendType" SG_ 2566834931 SpnCm10_FECAF3 3;
BA_ "GenSigTimeoutTime_PCM" SG_ 2566834931 SpnCm10_FECAF3 5000;
BA_ "SPN" SG_ 2566834931 SpnCm10_FECAF3 1706;
BA_ "CI_ParId" SG_ 2566834947 SpnCm10_FECB03 "1706";
BA_ "CI_SigId" SG_ 2566834947 SpnCm10_FECB03 15234;
BA_ "CI_SigName" SG_ 2566834947 SpnCm10_FECB03 "SPN Conversion Method 10";
BA_ "SPN" SG_ 2566834947 SpnCm10_FECB03 1706;
BA_ "CI_ParId" SG_ 2566834949 SpnCm10_FECB05 "1706";
BA_ "CI_SigId" SG_ 2566834949 SpnCm10_FECB05 40838;
BA_ "CI_SigName" SG_ 2566834949 SpnCm10_FECB05 "SPN Conversion Method 10";
BA_ "SPN" SG_ 2566834949 SpnCm10_FECB05 1706;
BA_ "CI_ParId" SG_ 2566834951 SpnCm10_FECB07 "1706";
BA_ "CI_SigId" SG_ 2566834951 SpnCm10_FECB07 38034;
BA_ "CI_SigName" SG_ 2566834951 SpnCm10_FECB07 "SPN Conversion Method 10";
BA_ "SPN" SG_ 2566834951 SpnCm10_FECB07 1706;
BA_ "CI_ParId" SG_ 2566834970 SpnCm10_FECB1A "1706";
BA_ "CI_SigId" SG_ 2566834970 SpnCm10_FECB1A 33956;
BA_ "CI_SigName" SG_ 2566834970 SpnCm10_FECB1A "SPN Conversion Method 10";
BA_ "SPN" SG_ 2566834970 SpnCm10_FECB1A 1706;
BA_ "CI_ParId" SG_ 2566834973 SpnCm10_FECB1D "1706";
BA_ "CI_SigId" SG_ 2566834973 SpnCm10_FECB1D 15898;
BA_ "CI_SigName" SG_ 2566834973 SpnCm10_FECB1D "SPN Conversion Method 10";
BA_ "SPN" SG_ 2566834973 SpnCm10_FECB1D 1706;
BA_ "CI_ParId" SG_ 2566834980 SpnCm10_FECB24 "1706";
BA_ "CI_SigId" SG_ 2566834980 SpnCm10_FECB24 38089;
BA_ "CI_SigName" SG_ 2566834980 SpnCm10_FECB24 "SPN Conversion Method 10";
BA_ "SPN" SG_ 2566834980 SpnCm10_FECB24 1706;
BA_ "CI_ParId" SG_ 2566834991 SpnCm10_FECB2F "1706";
BA_ "CI_SigId" SG_ 2566834991 SpnCm10_FECB2F 16008;
BA_ "CI_SigName" SG_ 2566834991 SpnCm10_FECB2F "SPN Conversion Method 10";
BA_ "SPN" SG_ 2566834991 SpnCm10_FECB2F 1706;
BA_ "CI_ParId" SG_ 2566834992 SpnCm10_FECB30 "1706";
BA_ "CI_SigId" SG_ 2566834992 SpnCm10_FECB30 34937;
BA_ "CI_SigName" SG_ 2566834992 SpnCm10_FECB30 "SPN Conversion Method 10";
BA_ "SPN" SG_ 2566834992 SpnCm10_FECB30 1706;
BA_ "CI_ParId" SG_ 2566834995 SpnCm10_FECB33 "1706";
BA_ "CI_SigId" SG_ 2566834995 SpnCm10_FECB33 16118;
BA_ "CI_SigName" SG_ 2566834995 SpnCm10_FECB33 "SPN Conversion Method 10";
BA_ "SPN" SG_ 2566834995 SpnCm10_FECB33 1706;
BA_ "CI_ParId" SG_ 2566835017 SpnCm10_FECB49 "1706";
BA_ "CI_SigId" SG_ 2566835017 SpnCm10_FECB49 34011;
BA_ "CI_SigName" SG_ 2566835017 SpnCm10_FECB49 "SPN Conversion Method 10";
BA_ "SPN" SG_ 2566835017 SpnCm10_FECB49 1706;
BA_ "CI_ParId" SG_ 2566835018 SpnCm10_FECB4A "1706";
BA_ "CI_SigId" SG_ 2566835018 SpnCm10_FECB4A 16393;
BA_ "CI_SigName" SG_ 2566835018 SpnCm10_FECB4A "SPN Conversion Method 10";
BA_ "SPN" SG_ 2566835018 SpnCm10_FECB4A 1706;
BA_ "CI_ParId" SG_ 2566835021 SpnCm10_FECB4D "1706";
BA_ "CI_SigId" SG_ 2566835021 SpnCm10_FECB4D 37007;
BA_ "CI_SigName" SG_ 2566835021 SpnCm10_FECB4D "SPN Conversion Method 10";
BA_ "SPN" SG_ 2566835021 SpnCm10_FECB4D 1706;
BA_ "CI_ParId" SG_ 2566835058 SpnCm10_FECB72 "1706";
BA_ "CI_SigId" SG_ 2566835058 SpnCm10_FECB72 16558;
BA_ "CI_SigName" SG_ 2566835058 SpnCm10_FECB72 "SPN Conversion Method 10";
BA_ "SPN" SG_ 2566835058 SpnCm10_FECB72 1706;
BA_ "CI_ParId" SG_ 2566835068 SpnCm10_FECB7C "1706";
BA_ "CI_SigId" SG_ 2566835068 SpnCm10_FECB7C 36592;
BA_ "CI_SigName" SG_ 2566835068 SpnCm10_FECB7C "SPN Conversion Method 10";
BA_ "SPN" SG_ 2566835068 SpnCm10_FECB7C 1706;
BA_ "CI_ParId" SG_ 2566835183 SpnCm10_FECBEF "1706";
BA_ "CI_SigId" SG_ 2566835183 SpnCm10_FECBEF 34582;
BA_ "CI_SigName" SG_ 2566835183 SpnCm10_FECBEF "SPN Conversion Method 10";
BA_ "SPN" SG_ 2566835183 SpnCm10_FECBEF 1706;
BA_ "CI_ParId" SG_ 2566835186 SpnCm10_FECBF2 "1706";
BA_ "CI_SigId" SG_ 2566835186 SpnCm10_FECBF2 38846;
BA_ "CI_SigName" SG_ 2566835186 SpnCm10_FECBF2 "SPN Conversion Method 10";
BA_ "SPN" SG_ 2566835186 SpnCm10_FECBF2 1706;
BA_ "CI_ParId" SG_ 2566835187 SpnCm10_FECBF3 "1706";
BA_ "CI_SigId" SG_ 2566835187 SpnCm10_FECBF3 32805;
BA_ "CI_SigName" SG_ 2566835187 SpnCm10_FECBF3 "SPN Conversion Method 10";
BA_ "SPN" SG_ 2566835187 SpnCm10_FECBF3 1706;
BA_ "CI_ParId" SG_ 2566835459 WhBasedVehSpeed_1 "84";
BA_ "CI_SigId" SG_ 2566835459 WhBasedVehSpeed_1 18014;
BA_ "CI_SigName" SG_ 2566835459 WhBasedVehSpeed_1 "Wheel-Based Vehicle Speed � 1";
BA_ "SPN" SG_ 2566835459 WhBasedVehSpeed_1 84;
BA_ "SigType" SG_ 2566835459 WhBasedVehSpeed_1 1;
BA_ "CI_ParId" SG_ 2566835461 HrTotVehDist_10 "917";
BA_ "CI_SigId" SG_ 2566835461 HrTotVehDist_10 41039;
BA_ "CI_SigName" SG_ 2566835461 HrTotVehDist_10 "High Resolution Total Vehicle Distance � 10";
BA_ "SPN" SG_ 2566835461 HrTotVehDist_10 917;
BA_ "SigType" SG_ 2566835461 HrTotVehDist_10 1;
BA_ "CI_ParId" SG_ 2566835463 HrTotVehDist_10_FECD07 "917";
BA_ "CI_SigId" SG_ 2566835463 HrTotVehDist_10_FECD07 38292;
BA_ "CI_SigName" SG_ 2566835463 HrTotVehDist_10_FECD07 "High Resolution Total Vehicle Distance � 10";
BA_ "SPN" SG_ 2566835463 HrTotVehDist_10_FECD07 917;
BA_ "SigType" SG_ 2566835463 HrTotVehDist_10_FECD07 1;
BA_ "CI_ParId" SG_ 2566835482 HrTotVehDist_10_FECD1A "917";
BA_ "CI_SigId" SG_ 2566835482 HrTotVehDist_10_FECD1A 34212;
BA_ "CI_SigName" SG_ 2566835482 HrTotVehDist_10_FECD1A "High Resolution Total Vehicle Distance � 10";
BA_ "SPN" SG_ 2566835482 HrTotVehDist_10_FECD1A 917;
BA_ "SigType" SG_ 2566835482 HrTotVehDist_10_FECD1A 1;
BA_ "CI_ParId" SG_ 2566835485 HrTotVehDist_10_FECD1D "917";
BA_ "CI_SigId" SG_ 2566835485 HrTotVehDist_10_FECD1D 19639;
BA_ "CI_SigName" SG_ 2566835485 HrTotVehDist_10_FECD1D "High Resolution Total Vehicle Distance � 10";
BA_ "SPN" SG_ 2566835485 HrTotVehDist_10_FECD1D 917;
BA_ "SigType" SG_ 2566835485 HrTotVehDist_10_FECD1D 1;
BA_ "CI_ParId" SG_ 2566835492 HrTotVehDist_10_FECD24 "917";
BA_ "CI_SigId" SG_ 2566835492 HrTotVehDist_10_FECD24 38493;
BA_ "CI_SigName" SG_ 2566835492 HrTotVehDist_10_FECD24 "High Resolution Total Vehicle Distance � 10";
BA_ "SPN" SG_ 2566835492 HrTotVehDist_10_FECD24 917;
BA_ "SigType" SG_ 2566835492 HrTotVehDist_10_FECD24 1;
BA_ "CI_ParId" SG_ 2566835503 HrTotVehDist_10_FECD2F "917";
BA_ "CI_SigId" SG_ 2566835503 HrTotVehDist_10_FECD2F 33338;
BA_ "CI_SigName" SG_ 2566835503 HrTotVehDist_10_FECD2F "High Resolution Total Vehicle Distance � 10";
BA_ "SPN" SG_ 2566835503 HrTotVehDist_10_FECD2F 917;
BA_ "SigType" SG_ 2566835503 HrTotVehDist_10_FECD2F 1;
BA_ "CI_ParId" SG_ 2566835504 HrTotVehDist_10_FECD30 "917";
BA_ "CI_SigId" SG_ 2566835504 HrTotVehDist_10_FECD30 35138;
BA_ "CI_SigName" SG_ 2566835504 HrTotVehDist_10_FECD30 "High Resolution Total Vehicle Distance � 10";
BA_ "SPN" SG_ 2566835504 HrTotVehDist_10_FECD30 917;
BA_ "SigType" SG_ 2566835504 HrTotVehDist_10_FECD30 1;
BA_ "CI_ParId" SG_ 2566835529 HrTotVehDist_10_FECD49 "917";
BA_ "CI_SigId" SG_ 2566835529 HrTotVehDist_10_FECD49 34413;
BA_ "CI_SigName" SG_ 2566835529 HrTotVehDist_10_FECD49 "High Resolution Total Vehicle Distance � 10";
BA_ "SPN" SG_ 2566835529 HrTotVehDist_10_FECD49 917;
BA_ "SigType" SG_ 2566835529 HrTotVehDist_10_FECD49 1;
BA_ "CI_ParId" SG_ 2566835530 HrTotVehDist_10_FECD4A "917";
BA_ "CI_SigId" SG_ 2566835530 HrTotVehDist_10_FECD4A 21088;
BA_ "CI_SigName" SG_ 2566835530 HrTotVehDist_10_FECD4A "High Resolution Total Vehicle Distance � 10";
BA_ "SPN" SG_ 2566835530 HrTotVehDist_10_FECD4A 917;
BA_ "SigType" SG_ 2566835530 HrTotVehDist_10_FECD4A 1;
BA_ "CI_ParId" SG_ 2566835533 HrTotVehDist_10_FECD4D "917";
BA_ "CI_SigId" SG_ 2566835533 HrTotVehDist_10_FECD4D 37209;
BA_ "CI_SigName" SG_ 2566835533 HrTotVehDist_10_FECD4D "High Resolution Total Vehicle Distance � 10";
BA_ "SPN" SG_ 2566835533 HrTotVehDist_10_FECD4D 917;
BA_ "SigType" SG_ 2566835533 HrTotVehDist_10_FECD4D 1;
BA_ "CI_ParId" SG_ 2566835539 HrTotVehDist_10_FECD53 "917";
BA_ "CI_SigId" SG_ 2566835539 HrTotVehDist_10_FECD53 21691;
BA_ "CI_SigName" SG_ 2566835539 HrTotVehDist_10_FECD53 "High Resolution Total Vehicle Distance � 10";
BA_ "SPN" SG_ 2566835539 HrTotVehDist_10_FECD53 917;
BA_ "SigType" SG_ 2566835539 HrTotVehDist_10_FECD53 1;
BA_ "CI_ParId" SG_ 2566835576 HrTotVehDist_10_FECD78 "917";
BA_ "CI_SigId" SG_ 2566835576 HrTotVehDist_10_FECD78 40182;
BA_ "CI_SigName" SG_ 2566835576 HrTotVehDist_10_FECD78 "High Resolution Total Vehicle Distance � 10";
BA_ "SPN" SG_ 2566835576 HrTotVehDist_10_FECD78 917;
BA_ "SigType" SG_ 2566835576 HrTotVehDist_10_FECD78 1;
BA_ "CI_ParId" SG_ 2566835580 HrTotVehDist_10_FECD7C "917";
BA_ "CI_SigId" SG_ 2566835580 HrTotVehDist_10_FECD7C 36794;
BA_ "CI_SigName" SG_ 2566835580 HrTotVehDist_10_FECD7C "High Resolution Total Vehicle Distance � 10";
BA_ "SPN" SG_ 2566835580 HrTotVehDist_10_FECD7C 917;
BA_ "SigType" SG_ 2566835580 HrTotVehDist_10_FECD7C 1;
BA_ "CI_ParId" SG_ 2566835657 HrTotVehDist_10_FECDC9 "917";
BA_ "CI_SigId" SG_ 2566835657 HrTotVehDist_10_FECDC9 45099;
BA_ "CI_SigName" SG_ 2566835657 HrTotVehDist_10_FECDC9 "High Resolution Total Vehicle Distance � 10";
BA_ "SPN" SG_ 2566835657 HrTotVehDist_10_FECDC9 917;
BA_ "SigType" SG_ 2566835657 HrTotVehDist_10_FECDC9 1;
BA_ "CI_ParId" SG_ 2566835695 HrTotVehDist_10_FECDEF "917";
BA_ "CI_SigId" SG_ 2566835695 HrTotVehDist_10_FECDEF 34783;
BA_ "CI_SigName" SG_ 2566835695 HrTotVehDist_10_FECDEF "High Resolution Total Vehicle Distance � 10";
BA_ "SPN" SG_ 2566835695 HrTotVehDist_10_FECDEF 917;
BA_ "SigType" SG_ 2566835695 HrTotVehDist_10_FECDEF 1;
BA_ "CI_ParId" SG_ 2566835698 HrTotVehDist_10_FECDF2 "917";
BA_ "CI_SigId" SG_ 2566835698 HrTotVehDist_10_FECDF2 39049;
BA_ "CI_SigName" SG_ 2566835698 HrTotVehDist_10_FECDF2 "High Resolution Total Vehicle Distance � 10";
BA_ "SPN" SG_ 2566835698 HrTotVehDist_10_FECDF2 917;
BA_ "SigType" SG_ 2566835698 HrTotVehDist_10_FECDF2 1;
BA_ "CI_ParId" SG_ 2566835699 HrTotVehDist_10_FECDF3 "917";
BA_ "CI_SigId" SG_ 2566835699 HrTotVehDist_10_FECDF3 21289;
BA_ "CI_SigName" SG_ 2566835699 HrTotVehDist_10_FECDF3 "High Resolution Total Vehicle Distance � 10";
BA_ "SPN" SG_ 2566835699 HrTotVehDist_10_FECDF3 917;
BA_ "SigType" SG_ 2566835699 HrTotVehDist_10_FECDF3 1;
BA_ "CI_ParId" SG_ 2565867237 DiffLckStsCent "564";
BA_ "CI_SigId" SG_ 2565867237 DiffLckStsCent 4160;
BA_ "CI_SigName" SG_ 2565867237 DiffLckStsCent "Differential Lock State - Central";
BA_ "GenSigSendType" SG_ 2565867237 DiffLckStsCent 3;
BA_ "GenSigTimeoutTime_PCM" SG_ 2565867237 DiffLckStsCent 2500;
BA_ "SPN" SG_ 2565867237 DiffLckStsCent 564;
BA_ "SigType" SG_ 2565867237 DiffLckStsCent 4;
BA_ "CI_ParId" SG_ 2565867237 DiffLckStsRa1 "569";
BA_ "CI_SigId" SG_ 2565867237 DiffLckStsRa1 4158;
BA_ "CI_SigName" SG_ 2565867237 DiffLckStsRa1 "Differential Lock State - Rear Axle 1";
BA_ "GenSigSendType" SG_ 2565867237 DiffLckStsRa1 3;
BA_ "GenSigTimeoutTime_PCM" SG_ 2565867237 DiffLckStsRa1 2500;
BA_ "SPN" SG_ 2565867237 DiffLckStsRa1 569;
BA_ "SigType" SG_ 2565867237 DiffLckStsRa1 4;
BA_ "CI_ParId" SG_ 2565867237 DiffLckStsFa1 "567";
BA_ "CI_SigId" SG_ 2565867237 DiffLckStsFa1 4156;
BA_ "CI_SigName" SG_ 2565867237 DiffLckStsFa1 "Differential Lock State - Front Axle 1";
BA_ "GenSigSendType" SG_ 2565867237 DiffLckStsFa1 3;
BA_ "GenSigTimeoutTime_PCM" SG_ 2565867237 DiffLckStsFa1 2500;
BA_ "SPN" SG_ 2565867237 DiffLckStsFa1 567;
BA_ "SigType" SG_ 2565867237 DiffLckStsFa1 4;
VAL_ 2566723411 AllAirbagDeactSwSts_FD1753 0 "Activated" 1 "Deactivated" 2 "Error, cannot be determined" 3 "Not Available" ;
VAL_ 2566723411 PassAirbagDeactSwSts_FD1753 0 "Activated" 1 "Deactivated" 2 "Error, cannot be determined" 3 "Not Available" ;
VAL_ 2566723411 Beltlock7Sts 0 "Unlocked" 1 "Locked" 2 "Error,State cannot be determined" 3 "Not Available" ;
VAL_ 2566723411 Beltlock6Sts 0 "Unlocked" 1 "Locked" 2 "Error,State cannot be determined" 3 "Not Available" ;
VAL_ 2566723411 Beltlock5Sts 0 "Unlocked" 1 "Locked" 2 "Error,State cannot be determined" 3 "Not Available" ;
VAL_ 2566723411 Beltlock4Sts 0 "Unlocked" 1 "Locked" 2 "Error,State cannot be determined" 3 "Not Available" ;
VAL_ 2566723411 Beltlock3Sts 0 "Unlocked" 1 "Locked" 2 "Error,State cannot be determined" 3 "Not Available" ;
VAL_ 2566723411 PassBeltlockSts_FD1753 0 "Unlocked" 1 "Locked" 2 "Error,State cannot be determined" 3 "Not Available" ;
VAL_ 2566723411 DrivBeltlockSts_FD1753 0 "Unlocked" 1 "Locked" 2 "Error,State cannot be determined" 3 "Not Available" ;
VAL_ 2365579520 GasolInj4Diag 0 "No fault present" 1 "Inj CA" 2 "Inj CC to VCC" 3 "Inj CC to GND" ;
VAL_ 2365579520 GasolInj3Diag 0 "No fault present" 1 "Inj CA" 2 "Inj CC to VCC" 3 "Inj CC to GND" ;
VAL_ 2365579520 GasolInj2Diag 0 "No fault present" 1 "Inj CA" 2 "Inj CC to VCC" 3 "Inj CC to GND" ;
VAL_ 2365579520 GasolInj1Diag 0 "No fault present" 1 "Inj CA" 2 "Inj CC to VCC" 3 "Inj CC to GND" ;
VAL_ 2365579520 AckGasolInjEna 0 "Not Petrol ACK" 1 "Petrol ACK" ;
VAL_ 2365579520 AckGasInjEna 0 "Not Gas ACK" 1 "Gas ACK" ;
VAL_ 2365579520 CngInjBottomFault 0 "Inj1" 1 "Inj2" 2 "Inj3" 3 "Inj4" ;
VAL_ 2365579520 CngInj1Diag 0 "No fault present" 1 "Inj CA" 2 "Inj CC to VCC" 3 "Inj CC to GND" ;
VAL_ 2365579520 CngInj2Diag 0 "No fault present" 1 "Inj CA" 2 "Inj CC to VCC" 3 "Inj CC to GND" ;
VAL_ 2365579520 CngInj3Diag 0 "No fault present" 1 "Inj CA" 2 "Inj CC to VCC" 3 "Inj CC to GND" ;
VAL_ 2365579520 CngInj4Diag 0 "No fault present" 1 "Inj CA" 2 "Inj CC to VCC" 3 "Inj CC to GND" ;
VAL_ 2365579520 FuelRailPrsSensValData 0 "Valid" 1 "Not valid" ;
VAL_ 2365579520 TempRailPrsSensValData 0 "Valid" 1 "Not valid" ;
VAL_ 2365579520 CngTankPrsSensValData 0 "Valid" 1 "Not valid" ;
VAL_ 2365579520 CngInjBottomFaultType 0 "No fault present" 1 "Inj CA" 2 "Inj CC to VCC" 3 "Inj CC to GND" ;
VAL_ 2365579520 FuelSelSts 0 "Gasoline" 1 "Gas" ;
VAL_ 2365579520 DiagInj2And3ValData 0 "Valid" 1 "Not valid" ;
VAL_ 2365579520 DiagInj1And4ValData 0 "Valid" 1 "Not valid" ;
VAL_ 2566844672 CcSts 0 "Off/Disabled" 1 "Hold" 2 "Accelerate" 3 "Decelerate" 4 "Resume" 5 "Set" 6 "Accelerator Override" 7 "Not Available" ;
VAL_ 2566844672 PtoGovSts 0 "Off/Disabled" 1 "Hold" 2 "Remote Hold" 3 "Standby" 4 "Remote Standby" 5 "Set" 6 "Dec/Coast" 7 "Resume" 8 "Accelerate" 9 "Accelerator Override" 10 "Preprogr. set speed 1" 11 "Preprogr. set speed 2" 12 "Preprogr. set speed 3" 13 "Preprogr. set speed 4" 14 "Preprogr. set speed 5" 15 "Preprogr. set speed 6" 16 "Preprogr. set speed 7" 17 "Preprogr. set speed 8" 18 "Set speed memory 1" 19 "Set speed memory 2" 20 "Set speed memory 3" 30 "Not defined" 31 "Not Available" ;
VAL_ 2566844672 CcAccelSw 0 "Off" 1 "On" 2 "Error" 3 "Not Available" ;
VAL_ 2566844672 CcResSw 0 "Off" 1 "On" 2 "Error" 3 "Not Available" ;
VAL_ 2566844672 CcCoastDecelSw 0 "Off" 1 "On" 2 "Error" 3 "Not Available" ;
VAL_ 2566844672 CcSetSw 0 "Off" 1 "On" 2 "Error" 3 "Not Available" ;
VAL_ 2566844672 CltSw_FEF100 0 "Released" 1 "Depressed" 2 "Error" 3 "Not Available" ;
VAL_ 2566844672 BrkSw 0 "Released" 1 "Depressed" 2 "Error" 3 "Not Available" ;
VAL_ 2566844672 CcEnaSw 0 "Disabled" 1 "Enabled" 2 "Error" 3 "Not Available" ;
VAL_ 2566844672 CcActv 0 "Off" 1 "On" 2 "Error" 3 "Not Available" ;
VAL_ 2566844689 CcSts_FEF111 0 "Off/Disabled" 1 "Hold" 2 "Accelerate" 3 "Decelerate" 4 "Resume" 5 "Set" 6 "Accelerator Override" 7 "Not Available" ;
VAL_ 2566844689 CcAccelSw_FEF111 0 "Off" 1 "On" 2 "Error" 3 "Not Available" ;
VAL_ 2566844689 CcResSw_FEF111 0 "Off" 1 "On" 2 "Error" 3 "Not Available" ;
VAL_ 2566844689 CcCoastDecelSw_FEF111 0 "Off" 1 "On" 2 "Error" 3 "Not Available" ;
VAL_ 2566844689 CcSetSw_FEF111 0 "Off" 1 "On" 2 "Error" 3 "Not Available" ;
VAL_ 2566844689 CcEnaSw_FEF111 0 "Disabled" 1 "Enabled" 2 "Error" 3 "Not Available" ;
VAL_ 2566844689 CcActv_FEF111 0 "Off" 1 "On" 2 "Error" 3 "Not Available" ;
VAL_ 2566708224 IsaVslRdySts 0 "Off" 1 "On" 2 "Error" 3 "Not Available/Not Supported" ;
VAL_ 2566708224 VslaRdySts 0 "Off" 1 "On" 2 "Error" 3 "Not Available/Not Supported" ;
VAL_ 2566708224 AebsRdySts 0 "Off" 1 "On" 2 "Condit. exists preventing resp." 3 "Not Available/Not Supported" ;
VAL_ 2566708224 AccRdySts 0 "Off" 1 "On" 2 "Error Condition" 3 "Not Available/Not Supported" ;
VAL_ 2365321995 VehSpeedAsilDConfor 0 "Does not conform (Permanently)" 1 "Conforms to ASIL D" 2 "Does not conform (Temporarily)" 3 "Not Available" ;
VAL_ 2365321995 VehHoldSts 0 "Not held" 1 "Held standstill" 2 "Error Indicator" 3 "Not Available" ;
VAL_ 2564882176 BatMainSwHoldReq 0 "Release Battery Main Switch" 1 "Hold Battery Main Switch" 2 "Undefined" 3 "Don�t Care / Take no action" ;
VAL_ 2564882179 EngAutoStartEnaSw 0 "Off" 1 "On" 2 "Error" 3 "Not Available" ;
VAL_ 2564882199 AtRegenForceSw 0 "Not active" 1 "Active" 2 "Error" 3 "Not Available" ;
VAL_ 2564882209 SeatBeltSw 0 "Not Buckled" 1 "Ok, Buckled" 2 "Error, State cannot be determin." 3 "Not Available" ;
VAL_ 2564882215 BatMainSwHoldReq_E0FF27 0 "Release Battery Main Switch" 1 "Hold Battery Main Switch" 2 "Undefined" 3 "Don�t Care / Take no action" ;
VAL_ 2564882227 BatMainSwHoldReq_E0FF33 0 "Release Battery Main Switch" 1 "Hold Battery Main Switch" 2 "Undefined" 3 "Don�t Care / Take no action" ;
VAL_ 2564882241 BatMainSwHoldReq_E0FF41 0 "Release Battery Main Switch" 1 "Hold Battery Main Switch" 2 "Undefined" 3 "Don�t Care / Take no action" ;
VAL_ 2564882250 BatMainSwHoldReq_E0FF4A 0 "Release Battery Main Switch" 1 "Hold Battery Main Switch" 2 "Undefined" 3 "Don�t Care / Take no action" ;
VAL_ 2566802967 Sts2OfDoors 0 "All doors are disabled (Unlock)" 1 "At least 1 door enabled (Lock)" 2 "Error" 3 "Not Available" ;
VAL_ 2364609063 Dc_Dc1OpCmd 0 "Disable" 1 "Standby mode" 2 "Buck mode" 3 "Boost mode" 4 "Reserved" 5 "Reserved" 6 "Reserved" 7 "Reserved" 8 "Reserved" 9 "Reserved" 10 "Reserved" 11 "Reserved" 12 "Reserved" 13 "Reserved" 15 "Don�t Care / Take no action" ;
VAL_ 2364609306 Dc_Dc1PwrLimDueToPwrElnTemp 0 "No power limit" 1 "Power limited" 2 "Error" 3 "Not Available" ;
VAL_ 2364609306 Dc_Dc1OpSts 0 "Disabled" 1 "Initialization in process" 2 "Operational Standby" 3 "Operational Buck mode" 4 "Operational Boost mode" 5 "Normal power down in process" 6 "Malfunction / protection disable" 7 "Reserved" 8 "Reserved" 9 "Reserved" 10 "Reserved" 11 "Reserved" 12 "Reserved" 13 "Manufacturer assignable state" 14 "Error" 15 "Not Available" ;
VAL_ 2566718743 EngWaitToStartLampData 0 "On" 1 "Off" 2 "Error" 3 "Not Available" ;
VAL_ 2566718743 EngCoolTempHighLampData 0 "Off" 1 "On" 2 "Reserved" 3 "Not Available" ;
VAL_ 2566718743 ObdMilData 0 "Off" 1 "On" 2 "Reserved" 3 "Not Available" ;
VAL_ 2566834688 SpnCm20 0 "SPN v.4" 1 "SPN v.1,2,3" ;
VAL_ 2566834691 SpnCm10 0 "SPN v.4" 1 "SPN v.1,2,3" ;
VAL_ 2566834693 SpnCm10_FECA05 0 "SPN v.4" 1 "SPN v.1,2,3" ;
VAL_ 2566834695 SpnCm10_FECA07 0 "SPN v.4" 1 "SPN v.1,2,3" ;
VAL_ 2566834699 SpnCm10_FECA0B 0 "SPN v.4" 1 "SPN v.1,2,3" ;
VAL_ 2566834704 SpnCm10_FECA10 0 "SPN v.4" 1 "SPN v.1,2,3" ;
VAL_ 2566834707 SpnCm10_FECA13 0 "SPN v.4" 1 "SPN v.1,2,3" ;
VAL_ 2566834711 SpnCm20_FECA17 0 "SPN v.4" 1 "SPN v.1,2,3" ;
VAL_ 2566834713 SpnCm10_FECA19 0 "SPN v.4" 1 "SPN v.1,2,3" ;
VAL_ 2566834714 SpnCm10_FECA1A 0 "SPN v.4" 1 "SPN v.1,2,3" ;
VAL_ 2566834717 SpnCm10_FECA1D 0 "SPN v.4" 1 "SPN v.1,2,3" ;
VAL_ 2566834721 SpnCm10_FECA21 0 "SPN v.4" 1 "SPN v.1,2,3" ;
VAL_ 2566834724 SpnCm10_FECA24 0 "SPN v.4" 1 "SPN v.1,2,3" ;
VAL_ 2566834727 SpnCm10_FECA27 0 "SPN v.4" 1 "SPN v.1,2,3" ;
VAL_ 2566834730 SpnCm10_FECA2A 0 "SPN v.4" 1 "SPN v.1,2,3" ;
VAL_ 2566834735 SpnCm10_FECA2F 0 "SPN v.4" 1 "SPN v.1,2,3" ;
VAL_ 2566834736 SpnCm10_FECA30 0 "SPN v.4" 1 "SPN v.1,2,3" ;
VAL_ 2566834739 SpnCm10_FECA33 0 "SPN v.4" 1 "SPN v.1,2,3" ;
VAL_ 2566834753 SpnCm10_FECA41 0 "SPN v.4" 1 "SPN v.1,2,3" ;
VAL_ 2566834761 SpnCm10_FECA49 0 "SPN v.4" 1 "SPN v.1,2,3" ;
VAL_ 2566834762 SpnCm10_FECA4A 0 "SPN v.4" 1 "SPN v.1,2,3" ;
VAL_ 2566834765 SpnCm10_FECA4D 0 "SPN v.4" 1 "SPN v.1,2,3" ;
VAL_ 2566834771 SpnCm10_FECA53 0 "SPN v.4" 1 "SPN v.1,2,3" ;
VAL_ 2566834802 SpnCm10_FECA72 0 "SPN v.4" 1 "SPN v.1,2,3" ;
VAL_ 2566834808 SpnCm10_FECA78 0 "SPN v.4" 1 "SPN v.1,2,3" ;
VAL_ 2566834812 SpnCm10_FECA7C 0 "SPN v.4" 1 "SPN v.1,2,3" ;
VAL_ 2566834817 SpnCm10_FECA81 0 "SPN v.4" 1 "SPN v.1,2,3" ;
VAL_ 2566834844 SpnCm10_FECA9C 0 "SPN v.4" 1 "SPN v.1,2,3" ;
VAL_ 2566834846 SpnCm10_FECA9E 0 "SPN v.4" 1 "SPN v.1,2,3" ;
VAL_ 2566834847 SpnCm10_FECA9F 0 "SPN v.4" 1 "SPN v.1,2,3" ;
VAL_ 2566834848 SpnCm10_FECAA0 0 "SPN v.4" 1 "SPN v.1,2,3" ;
VAL_ 2566834889 SpnCm10_FECAC9 0 "SPN v.4" 1 "SPN v.1,2,3" ;
VAL_ 2566834917 SpnCm10_FECAE5 0 "SPN v.4" 1 "SPN v.1,2,3" ;
VAL_ 2566834926 SpnCm10_FECAEE 0 "SPN v.4" 1 "SPN v.1,2,3" ;
VAL_ 2566834927 SpnCm10_FECAEF 0 "SPN v.4" 1 "SPN v.1,2,3" ;
VAL_ 2566834930 SpnCm10_FECAF2 0 "SPN v.4" 1 "SPN v.1,2,3" ;
VAL_ 2566834931 SpnCm10_FECAF3 0 "SPN v.4" 1 "SPN v.1,2,3" ;
VAL_ 2566834947 SpnCm10_FECB03 0 "SPN v.4" 1 "SPN v.1,2,3" ;
VAL_ 2566834949 SpnCm10_FECB05 0 "SPN v.4" 1 "SPN v.1,2,3" ;
VAL_ 2566834951 SpnCm10_FECB07 0 "SPN v.4" 1 "SPN v.1,2,3" ;
VAL_ 2566834970 SpnCm10_FECB1A 0 "SPN v.4" 1 "SPN v.1,2,3" ;
VAL_ 2566834973 SpnCm10_FECB1D 0 "SPN v.4" 1 "SPN v.1,2,3" ;
VAL_ 2566834980 SpnCm10_FECB24 0 "SPN v.4" 1 "SPN v.1,2,3" ;
VAL_ 2566834991 SpnCm10_FECB2F 0 "SPN v.4" 1 "SPN v.1,2,3" ;
VAL_ 2566834992 SpnCm10_FECB30 0 "SPN v.4" 1 "SPN v.1,2,3" ;
VAL_ 2566834995 SpnCm10_FECB33 0 "SPN v.4" 1 "SPN v.1,2,3" ;
VAL_ 2566835017 SpnCm10_FECB49 0 "SPN v.4" 1 "SPN v.1,2,3" ;
VAL_ 2566835018 SpnCm10_FECB4A 0 "SPN v.4" 1 "SPN v.1,2,3" ;
VAL_ 2566835021 SpnCm10_FECB4D 0 "SPN v.4" 1 "SPN v.1,2,3" ;
VAL_ 2566835058 SpnCm10_FECB72 0 "SPN v.4" 1 "SPN v.1,2,3" ;
VAL_ 2566835068 SpnCm10_FECB7C 0 "SPN v.4" 1 "SPN v.1,2,3" ;
VAL_ 2566835183 SpnCm10_FECBEF 0 "SPN v.4" 1 "SPN v.1,2,3" ;
VAL_ 2566835186 SpnCm10_FECBF2 0 "SPN v.4" 1 "SPN v.1,2,3" ;
VAL_ 2566835187 SpnCm10_FECBF3 0 "SPN v.4" 1 "SPN v.1,2,3" ;
VAL_ 2565867237 DiffLckStsCent 0 "Disengaged" 1 "Engaged" 2 "Error" 3 "Not Available" ;
VAL_ 2565867237 DiffLckStsRa1 0 "Differential lock disengaged" 1 "Differential lock engaged" 2 "Error" 3 "Not Available" ;
VAL_ 2565867237 DiffLckStsFa1 0 "Disengaged" 1 "Engaged" 2 "Error" 3 "Not Available" ;
